VERSION ""

NS_ :

BS_:

BU_: BCM_PB ECM_PB TCM_PB Router_PB APA_PB SBSA_PB EBCM_PB IPC_PB SDM_PB EPS_PB AHL_AFL_PB ECC_PB ESCL_PB Firewall_PB CGM_PB PFAF_PB IBOOST_PB

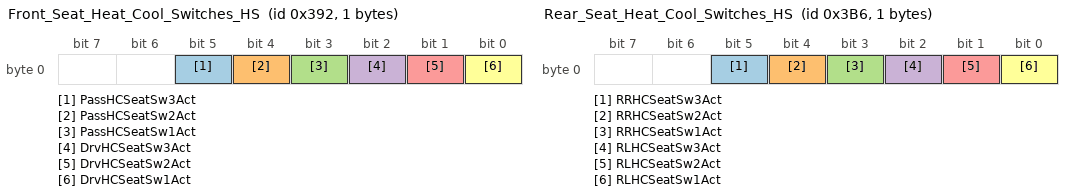
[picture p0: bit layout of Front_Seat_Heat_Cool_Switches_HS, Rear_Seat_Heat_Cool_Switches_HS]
BO_ 914 Front_Seat_Heat_Cool_Switches_HS: 1 ECC_PB
 SG_ PassHCSeatSw3Act : 5|1@0+ (1,0) [0|1] ""  BCM_PB
 SG_ PassHCSeatSw2Act : 4|1@0+ (1,0) [0|1] ""  BCM_PB
 SG_ PassHCSeatSw1Act : 3|1@0+ (1,0) [0|1] ""  BCM_PB
 SG_ DrvHCSeatSw3Act : 2|1@0+ (1,0) [0|1] ""  BCM_PB
 SG_ DrvHCSeatSw2Act : 1|1@0+ (1,0) [0|1] ""  BCM_PB
 SG_ DrvHCSeatSw1Act : 0|1@0+ (1,0) [0|1] ""  BCM_PB

BO_ 950 Rear_Seat_Heat_Cool_Switches_HS: 1 ECC_PB
 SG_ RRHCSeatSw3Act : 5|1@0+ (1,0) [0|1] ""  BCM_PB
 SG_ RRHCSeatSw2Act : 4|1@0+ (1,0) [0|1] ""  BCM_PB
 SG_ RRHCSeatSw1Act : 3|1@0+ (1,0) [0|1] ""  BCM_PB
 SG_ RLHCSeatSw3Act : 2|1@0+ (1,0) [0|1] ""  BCM_PB
 SG_ RLHCSeatSw2Act : 1|1@0+ (1,0) [0|1] ""  BCM_PB
 SG_ RLHCSeatSw1Act : 0|1@0+ (1,0) [0|1] ""  BCM_PB

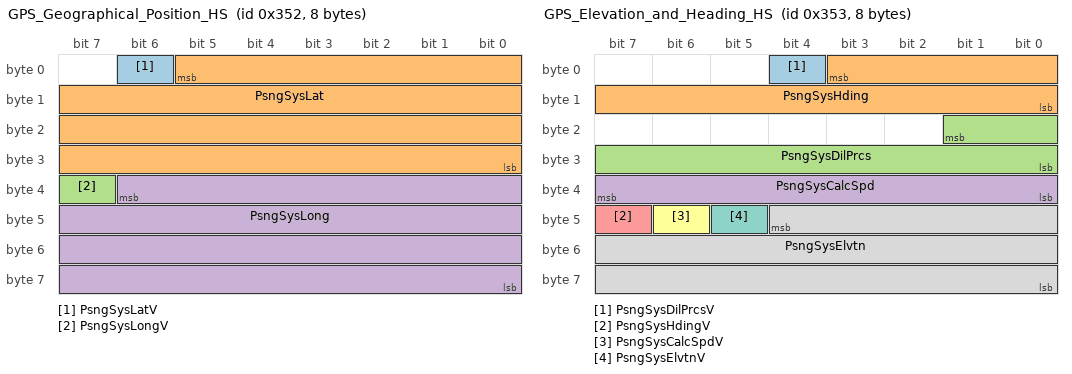
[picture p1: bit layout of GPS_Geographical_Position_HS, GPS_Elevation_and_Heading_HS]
BO_ 850 GPS_Geographical_Position_HS: 8 Firewall_PB
 SG_ PsngSysLatV : 6|1@0+ (1,0) [0|1] ""  ECC_PB
 SG_ PsngSysLat : 5|30@0- (1,0) [-536870912|536870911] "msarc"  ECC_PB
 SG_ PsngSysLongV : 39|1@0+ (1,0) [0|1] ""  ECC_PB
 SG_ PsngSysLong : 38|31@0- (1,0) [-1073741824|1073741823] "msarc"  ECC_PB

BO_ 851 GPS_Elevation_and_Heading_HS: 8 Firewall_PB
 SG_ PsngSysDilPrcsV : 4|1@0+ (1,0) [0|1] "" Vector__XXX
 SG_ PsngSysHding : 3|12@0+ (0.1,0) [0|409.5] "deg"  ECC_PB
 SG_ PsngSysDilPrcs : 17|10@0+ (0.1,0) [0|102.3] "" Vector__XXX
 SG_ PsngSysCalcSpd : 39|8@0+ (1,0) [0|255] "km/h" Vector__XXX
 SG_ PsngSysHdingV : 47|1@0+ (1,0) [0|1] ""  ECC_PB
 SG_ PsngSysCalcSpdV : 46|1@0+ (1,0) [0|1] "" Vector__XXX
 SG_ PsngSysElvtnV : 45|1@0+ (1,0) [0|1] ""  ECC_PB
 SG_ PsngSysElvtn : 44|21@0+ (1,-100000) [-100000|1997151] "cm"  ECC_PB

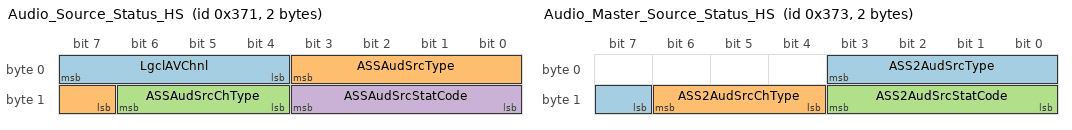
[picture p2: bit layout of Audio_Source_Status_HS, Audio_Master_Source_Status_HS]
BO_ 881 Audio_Source_Status_HS: 2 Firewall_PB
 SG_ LgclAVChnl : 7|4@0+ (1,0) [0|15] "" Vector__XXX
 SG_ ASSAudSrcType : 3|5@0+ (1,0) [0|31] ""  ECC_PB
 SG_ ASSAudSrcChType : 14|3@0+ (1,0) [0|7] ""  ECC_PB
 SG_ ASSAudSrcStatCode : 11|4@0+ (1,0) [0|15] ""  ECC_PB

BO_ 883 Audio_Master_Source_Status_HS: 2 Firewall_PB
 SG_ ASS2AudSrcType : 3|5@0+ (1,0) [0|31] ""  ECC_PB
 SG_ ASS2AudSrcChType : 14|3@0+ (1,0) [0|7] ""  ECC_PB
 SG_ ASS2AudSrcStatCode : 11|4@0+ (1,0) [0|15] ""  ECC_PB

BO_ 948 Rear_Seat_Heat_Cool_Control_HS: 4 BCM_PB
 SG_ RLHCSMIndReq : 4|2@0+ (1,0) [0|3] ""  ECC_PB
 SG_ RLHCSMInd1 : 2|1@0+ (1,0) [0|1] ""  ECC_PB
 SG_ RLHCSMInd2 : 1|1@0+ (1,0) [0|1] ""  ECC_PB
 SG_ RLHCSMInd3 : 0|1@0+ (1,0) [0|1] ""  ECC_PB
 SG_ RRHCSMIndReq : 12|2@0+ (1,0) [0|3] ""  ECC_PB
 SG_ RRHCSMInd1 : 10|1@0+ (1,0) [0|1] ""  ECC_PB
 SG_ RRHCSMInd2 : 9|1@0+ (1,0) [0|1] ""  ECC_PB
 SG_ RRHCSMInd3 : 8|1@0+ (1,0) [0|1] ""  ECC_PB
 SG_ RLHCSLIndReq : 22|2@0+ (1,0) [0|3] ""  ECC_PB
 SG_ RLHCSLSeatLev1 : 20|1@0+ (1,0) [0|1] ""  ECC_PB
 SG_ RLHCSLSeatLev2 : 19|1@0+ (1,0) [0|1] ""  ECC_PB
 SG_ RLHCSLSeatLev3 : 18|1@0+ (1,0) [0|1] ""  ECC_PB
 SG_ RLHCSLSeatLev4 : 17|1@0+ (1,0) [0|1] ""  ECC_PB
 SG_ RLHCSLSeatLev5 : 16|1@0+ (1,0) [0|1] ""  ECC_PB
 SG_ RRHCSLIndReq : 30|2@0+ (1,0) [0|3] ""  ECC_PB
 SG_ RRHCSLSeatLev1 : 28|1@0+ (1,0) [0|1] ""  ECC_PB
 SG_ RRHCSLSeatLev2 : 27|1@0+ (1,0) [0|1] ""  ECC_PB
 SG_ RRHCSLSeatLev3 : 26|1@0+ (1,0) [0|1] ""  ECC_PB
 SG_ RRHCSLSeatLev4 : 25|1@0+ (1,0) [0|1] ""  ECC_PB
 SG_ RRHCSLSeatLev5 : 24|1@0+ (1,0) [0|1] ""  ECC_PB

BO_ 1061 Display_Measurement_System_HS: 1 IPC_PB
 SG_ DispMeasSys : 2|1@0+ (1,0) [0|1] "" Vector__XXX
 SG_ DispMeasSysExt : 1|2@0+ (1,0) [0|3] ""  ECC_PB

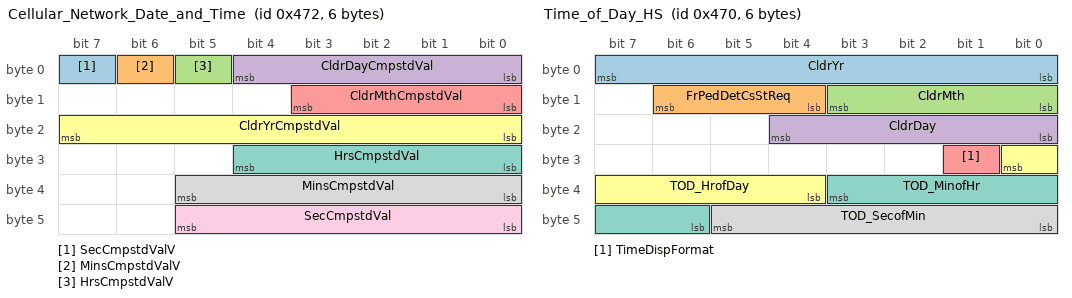
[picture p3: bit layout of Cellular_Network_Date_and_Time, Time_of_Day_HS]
BO_ 1138 Cellular_Network_Date_and_Time: 6 Firewall_PB
 SG_ SecCmpstdValV : 7|1@0+ (1,0) [0|1] "" Vector__XXX
 SG_ MinsCmpstdValV : 6|1@0+ (1,0) [0|1] "" Vector__XXX
 SG_ HrsCmpstdValV : 5|1@0+ (1,0) [0|1] "" Vector__XXX
 SG_ CldrDayCmpstdVal : 4|5@0+ (1,0) [0|31] "days"  ECC_PB
 SG_ CldrMthCmpstdVal : 11|4@0+ (1,0) [0|15] ""  ECC_PB
 SG_ CldrYrCmpstdVal : 23|8@0+ (1,2000) [2000|2255] "year" Vector__XXX
 SG_ HrsCmpstdVal : 28|5@0+ (1,0) [0|31] "h" Vector__XXX
 SG_ MinsCmpstdVal : 37|6@0+ (1,0) [0|63] "min" Vector__XXX
 SG_ SecCmpstdVal : 45|6@0+ (1,0) [0|63] "secs" Vector__XXX

BO_ 1136 Time_of_Day_HS: 6 Firewall_PB
 SG_ CldrYr : 7|8@0+ (1,2000) [2000|2255] "year" Vector__XXX
 SG_ FrPedDetCsStReq : 14|3@0+ (1,0) [0|7] "" Vector__XXX
 SG_ CldrMth : 11|4@0+ (1,0) [0|15] ""  ECC_PB
 SG_ CldrDay : 20|5@0+ (1,0) [0|31] "days"  ECC_PB
 SG_ TimeDispFormat : 25|1@0+ (1,0) [0|1] "" Vector__XXX
 SG_ TOD_HrofDay : 24|5@0+ (1,0) [0|31] "hr"  ECC_PB
 SG_ TOD_MinofHr : 35|6@0+ (1,0) [0|63] "min"  ECC_PB
 SG_ TOD_SecofMin : 45|6@0+ (1,0) [0|63] "s"  ECC_PB

BO_ 2430336753 Func_USDT_Req_to_All_F_TestTool: 8 Firewall_PB
 SG_ DgnInf : 7|64@0+ (1,0) [0|1.84467440737096E+019] ""  ECC_PB

BO_ 2430336755 Func_USDT_Req_to_All_F_ONSTAR: 8 Firewall_PB
 SG_ DgnInf : 7|64@0+ (1,0) [0|1.84467440737096E+019] ""  ECC_PB

BO_ 2497376665 Phy_USDT_Resp_F_ECC_To_TestTool: 8 ECC_PB
 SG_ DgnInf : 7|64@0+ (1,0) [0|1.84467440737096E+019] ""  Firewall_PB

BO_ 2497507737 Phy_UUDT_Resp_F_ECC_To_TestTool: 8 ECC_PB
 SG_ DgnInf : 7|64@0+ (1,0) [0|1.84467440737096E+019] ""  Firewall_PB

BO_ 2497377177 Phy_USDT_Resp_F_ECC_To_ONSTAR: 8 ECC_PB
 SG_ DgnInf : 7|64@0+ (1,0) [0|1.84467440737096E+019] ""  Firewall_PB

BO_ 2497508249 Phy_UUDT_Resp_F_ECC_To_ONSTAR: 8 ECC_PB
 SG_ DgnInf : 7|64@0+ (1,0) [0|1.84467440737096E+019] ""  Firewall_PB

BO_ 2497354225 Phy_USDT_Req_to_ECC_F_TestTool: 8 Firewall_PB
 SG_ DgnInf : 7|64@0+ (1,0) [0|1.84467440737096E+019] ""  ECC_PB

BO_ 2497354227 Phy_USDT_Req_to_ECC_F_ONSTAR: 8 Firewall_PB
 SG_ DgnInf : 7|64@0+ (1,0) [0|1.84467440737096E+019] ""  ECC_PB

BO_ 1088 Re_Initialization_Request_BCM: 1 BCM_PB
 SG_ ReIniReq_BCM : 7|1@0+ (1,0) [0|1] ""  ECC_PB

BO_ 1089 Re_Initialization_Request_IPC: 1 IPC_PB
 SG_ ReIniReq_IPC : 7|1@0+ (1,0) [0|1] ""  ECC_PB

BO_ 1122 Re_Initialization_Request_APA: 1 APA_PB
 SG_ ReIniReq_APA : 7|1@0+ (1,0) [0|1] ""  ECC_PB

BO_ 1091 Re_Initialization_Request_ECC: 1 ECC_PB
 SG_ ReIniReq_ECC : 7|1@0+ (1,0) [0|1] ""  IPC_PB,APA_PB,SBSA_PB,BCM_PB,ESCL_PB,Firewall_PB,SDM_PB

BO_ 1093 Re_Initialization_Request_ESCL: 1 ESCL_PB
 SG_ ReIniReq_ESCL : 7|1@0+ (1,0) [0|1] ""  ECC_PB

BO_ 1094 Re_Initialization_Request_FCM: 1 Firewall_PB
 SG_ ReIniReq_FCM : 7|1@0+ (1,0) [0|1] ""  ECC_PB

BO_ 1095 Re_Initialization_Request_ONSTAR: 1 Firewall_PB
 SG_ ReIniReq_ONSTAR : 7|1@0+ (1,0) [0|1] ""  ECC_PB

BO_ 1096 Re_Initialization_Request_RadioH: 1 Firewall_PB
 SG_ ReIniReq_RadioHead : 7|1@0+ (1,0) [0|1] ""  ECC_PB

BO_ 1097 Re_Initialization_Request_SDM: 1 SDM_PB
 SG_ ReIniReq_SDM : 7|1@0+ (1,0) [0|1] ""  ECC_PB

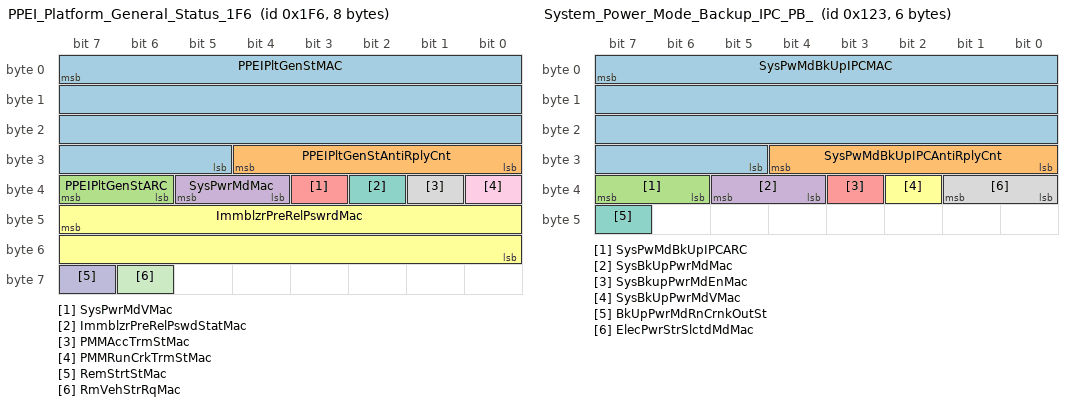
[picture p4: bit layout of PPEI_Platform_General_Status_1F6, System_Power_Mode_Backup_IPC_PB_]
BO_ 502 PPEI_Platform_General_Status_1F6: 8 BCM_PB
 SG_ PPEIPltGenStMAC : 7|27@0+ (1,0) [0|134217727] "" Vector__XXX
 SG_ PPEIPltGenStAntiRplyCnt : 28|5@0+ (1,0) [0|31] "" Vector__XXX
 SG_ PPEIPltGenStARC : 39|2@0+ (1,0) [0|3] "" Vector__XXX
 SG_ SysPwrMdMac : 37|2@0+ (1,0) [0|3] ""  ECC_PB
 SG_ SysPwrMdVMac : 35|1@0+ (1,0) [0|1] ""  ECC_PB
 SG_ ImmblzrPreRelPswrdMac : 47|16@0+ (1,0) [0|65535] "passwrd" Vector__XXX
 SG_ ImmblzrPreRelPswdStatMac : 34|1@0+ (1,0) [0|1] "" Vector__XXX
 SG_ PMMAccTrmStMac : 33|1@0+ (1,0) [0|1] "" Vector__XXX
 SG_ PMMRunCrkTrmStMac : 32|1@0+ (1,0) [0|1] "" Vector__XXX
 SG_ RemStrtStMac : 63|1@0+ (1,0) [0|1] ""  ECC_PB
 SG_ RmVehStrRqMac : 62|1@0+ (1,0) [0|1] "" Vector__XXX

BO_ 291 System_Power_Mode_Backup_IPC_PB_: 6 IPC_PB
 SG_ SysPwMdBkUpIPCMAC : 7|27@0+ (1,0) [0|134217727] "" Vector__XXX
 SG_ SysPwMdBkUpIPCAntiRplyCnt : 28|5@0+ (1,0) [0|31] "" Vector__XXX
 SG_ SysPwMdBkUpIPCARC : 39|2@0+ (1,0) [0|3] "" Vector__XXX
 SG_ SysBkUpPwrMdMac : 37|2@0+ (1,0) [0|3] ""  ECC_PB
 SG_ SysBkupPwrMdEnMac : 35|1@0+ (1,0) [0|1] ""  ECC_PB
 SG_ SysBkUpPwrMdVMac : 34|1@0+ (1,0) [0|1] ""  ECC_PB
 SG_ BkUpPwrMdRnCrnkOutSt : 47|1@0+ (1,0) [0|1] "" Vector__XXX
 SG_ ElecPwrStrSlctdMdMac : 33|2@0+ (1,0) [0|3] "" Vector__XXX

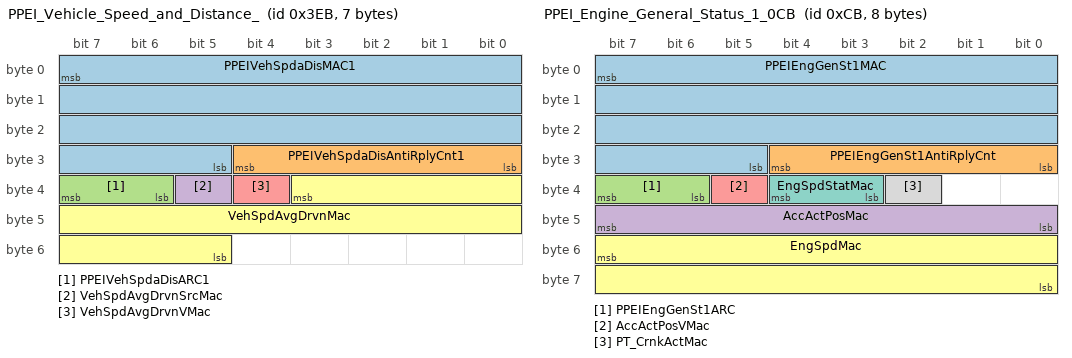
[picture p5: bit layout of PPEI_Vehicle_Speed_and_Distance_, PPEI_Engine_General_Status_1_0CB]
BO_ 1003 PPEI_Vehicle_Speed_and_Distance_: 7 ECM_PB
 SG_ PPEIVehSpdaDisMAC1 : 7|27@0+ (1,0) [0|134217727] "" Vector__XXX
 SG_ PPEIVehSpdaDisAntiRplyCnt1 : 28|5@0+ (1,0) [0|31] "" Vector__XXX
 SG_ PPEIVehSpdaDisARC1 : 39|2@0+ (1,0) [0|3] "" Vector__XXX
 SG_ VehSpdAvgDrvnSrcMac : 37|1@0+ (1,0) [0|1] "" Vector__XXX
 SG_ VehSpdAvgDrvnVMac : 36|1@0+ (1,0) [0|1] ""  ECC_PB
 SG_ VehSpdAvgDrvnMac : 35|15@0+ (0.015625,0) [0|511.984375] "km/h"  ECC_PB

BO_ 203 PPEI_Engine_General_Status_1_0CB: 8 ECM_PB
 SG_ PPEIEngGenSt1MAC : 7|27@0+ (1,0) [0|134217727] "" Vector__XXX
 SG_ PPEIEngGenSt1AntiRplyCnt : 28|5@0+ (1,0) [0|31] "" Vector__XXX
 SG_ PPEIEngGenSt1ARC : 39|2@0+ (1,0) [0|3] "" Vector__XXX
 SG_ AccActPosMac : 47|8@0+ (0.392157,0) [0|100.000035] "%" Vector__XXX
 SG_ AccActPosVMac : 37|1@0+ (1,0) [0|1] "" Vector__XXX
 SG_ EngSpdMac : 55|16@0+ (0.25,0) [0|16383.75] "rpm"  ECC_PB
 SG_ EngSpdStatMac : 36|2@0+ (1,0) [0|3] ""  ECC_PB
 SG_ PT_CrnkActMac : 34|1@0+ (1,0) [0|1] "" Vector__XXX

BO_ 1630 Climate_Control_Customization_In: 6 ECC_PB
 SG_ AirQltySnsCstCrStVal : 7|3@0+ (1,0) [0|7] ""  Firewall_PB
 SG_ AirQltySnsCstStAvl : 4|1@0+ (1,0) [0|1] ""  Firewall_PB
 SG_ AirQltySnsCstAvlFlg1 : 3|1@0+ (1,0) [0|1] ""  Firewall_PB
 SG_ AirQltySnsCstAvlFlg2 : 2|1@0+ (1,0) [0|1] ""  Firewall_PB
 SG_ AirQltySnsCstAvlFlg3 : 1|1@0+ (1,0) [0|1] ""  Firewall_PB
 SG_ AirQltySnsCstAvlFlg4 : 0|1@0+ (1,0) [0|1] ""  Firewall_PB
 SG_ AirQltySnsCstAvlFlg5 : 15|1@0+ (1,0) [0|1] ""  Firewall_PB
 SG_ AirQltySnsCstAvlFlg6 : 14|1@0+ (1,0) [0|1] ""  Firewall_PB
 SG_ AirQltySnsCstAvlFlg7 : 13|1@0+ (1,0) [0|1] ""  Firewall_PB
 SG_ IonzrCtrlCstCrStVal : 12|3@0+ (1,0) [0|7] ""  Firewall_PB
 SG_ IonzrCtrlCstStAvl : 9|1@0+ (1,0) [0|1] ""  Firewall_PB
 SG_ IonzrCtrlCstAvlFlg1 : 8|1@0+ (1,0) [0|1] ""  Firewall_PB
 SG_ IonzrCtrlCstAvlFlg2 : 23|1@0+ (1,0) [0|1] ""  Firewall_PB
 SG_ IonzrCtrlCstAvlFlg3 : 22|1@0+ (1,0) [0|1] ""  Firewall_PB
 SG_ IonzrCtrlCstAvlFlg4 : 21|1@0+ (1,0) [0|1] ""  Firewall_PB
 SG_ IonzrCtrlCstAvlFlg5 : 20|1@0+ (1,0) [0|1] ""  Firewall_PB
 SG_ IonzrCtrlCstAvlFlg6 : 19|1@0+ (1,0) [0|1] ""  Firewall_PB
 SG_ IonzrCtrlCstAvlFlg7 : 18|1@0+ (1,0) [0|1] ""  Firewall_PB
 SG_ AutoDfgCstCrStVal : 17|3@0+ (1,0) [0|7] ""  Firewall_PB
 SG_ AutoDfgCstStAvl : 30|1@0+ (1,0) [0|1] ""  Firewall_PB
 SG_ AutoDfgCstAvlFlg1 : 29|1@0+ (1,0) [0|1] ""  Firewall_PB
 SG_ AutoDfgCstAvlFlg2 : 28|1@0+ (1,0) [0|1] ""  Firewall_PB
 SG_ AutoDfgCstAvlFlg3 : 27|1@0+ (1,0) [0|1] ""  Firewall_PB
 SG_ AutoDfgCstAvlFlg4 : 26|1@0+ (1,0) [0|1] ""  Firewall_PB
 SG_ AutoDfgCstAvlFlg5 : 25|1@0+ (1,0) [0|1] ""  Firewall_PB
 SG_ AutoDfgCstAvlFlg6 : 24|1@0+ (1,0) [0|1] ""  Firewall_PB
 SG_ AutoDfgCstAvlFlg7 : 39|1@0+ (1,0) [0|1] ""  Firewall_PB
 SG_ AutoFanCstCrStVal : 38|3@0+ (1,0) [0|7] ""  Firewall_PB
 SG_ AutoFanCstStAvl : 35|1@0+ (1,0) [0|1] ""  Firewall_PB
 SG_ AutoFanCstAvlFlg1 : 34|1@0+ (1,0) [0|1] ""  Firewall_PB
 SG_ AutoFanCstAvlFlg2 : 33|1@0+ (1,0) [0|1] ""  Firewall_PB
 SG_ AutoFanCstAvlFlg3 : 32|1@0+ (1,0) [0|1] ""  Firewall_PB
 SG_ AutoFanCstAvlFlg4 : 47|1@0+ (1,0) [0|1] ""  Firewall_PB
 SG_ AutoFanCstAvlFlg5 : 46|1@0+ (1,0) [0|1] ""  Firewall_PB
 SG_ AutoFanCstAvlFlg6 : 45|1@0+ (1,0) [0|1] ""  Firewall_PB
 SG_ AutoFanCstAvlFlg7 : 44|1@0+ (1,0) [0|1] ""  Firewall_PB

BO_ 1638 Climate_Control_Customizati_0000: 7 ECC_PB
 SG_ RrDfgStUpCstCrStVal : 7|3@0+ (1,0) [0|7] ""  Firewall_PB
 SG_ RrDfgStUpCstStAvl : 4|1@0+ (1,0) [0|1] ""  Firewall_PB
 SG_ RrDfgStUpCstAvlFlg1 : 3|1@0+ (1,0) [0|1] ""  Firewall_PB
 SG_ RrDfgStUpCstAvlFlg2 : 2|1@0+ (1,0) [0|1] ""  Firewall_PB
 SG_ RrDfgStUpCstAvlFlg3 : 1|1@0+ (1,0) [0|1] ""  Firewall_PB
 SG_ RrDfgStUpCstAvlFlg4 : 0|1@0+ (1,0) [0|1] ""  Firewall_PB
 SG_ RrDfgStUpCstAvlFlg5 : 15|1@0+ (1,0) [0|1] ""  Firewall_PB
 SG_ RrDfgStUpCstAvlFlg6 : 14|1@0+ (1,0) [0|1] ""  Firewall_PB
 SG_ RrDfgStUpCstAvlFlg7 : 13|1@0+ (1,0) [0|1] ""  Firewall_PB
 SG_ RrZnStUpCstCrStVal : 12|3@0+ (1,0) [0|7] ""  Firewall_PB
 SG_ RrZnStUpCstStAvl : 9|1@0+ (1,0) [0|1] ""  Firewall_PB
 SG_ RrZnStUpCstAvlFlg1 : 8|1@0+ (1,0) [0|1] ""  Firewall_PB
 SG_ RrZnStUpCstAvlFlg2 : 23|1@0+ (1,0) [0|1] ""  Firewall_PB
 SG_ RrZnStUpCstAvlFlg3 : 22|1@0+ (1,0) [0|1] ""  Firewall_PB
 SG_ RrZnStUpCstAvlFlg4 : 21|1@0+ (1,0) [0|1] ""  Firewall_PB
 SG_ RrZnStUpCstAvlFlg5 : 20|1@0+ (1,0) [0|1] ""  Firewall_PB
 SG_ RrZnStUpCstAvlFlg6 : 19|1@0+ (1,0) [0|1] ""  Firewall_PB
 SG_ RrZnStUpCstAvlFlg7 : 18|1@0+ (1,0) [0|1] ""  Firewall_PB
 SG_ AutoCoolStCstCrStVal : 17|3@0+ (1,0) [0|7] ""  Firewall_PB
 SG_ AutoCoolStCstStAvl : 30|1@0+ (1,0) [0|1] ""  Firewall_PB
 SG_ AutoCoolStCstAvlFlg1 : 29|1@0+ (1,0) [0|1] ""  Firewall_PB
 SG_ AutoCoolStCstAvlFlg2 : 28|1@0+ (1,0) [0|1] ""  Firewall_PB
 SG_ AutoCoolStCstAvlFlg3 : 27|1@0+ (1,0) [0|1] ""  Firewall_PB
 SG_ AutoCoolStCstAvlFlg4 : 26|1@0+ (1,0) [0|1] ""  Firewall_PB
 SG_ AutoCoolStCstAvlFlg5 : 25|1@0+ (1,0) [0|1] ""  Firewall_PB
 SG_ AutoCoolStCstAvlFlg6 : 24|1@0+ (1,0) [0|1] ""  Firewall_PB
 SG_ AutoCoolStCstAvlFlg7 : 39|1@0+ (1,0) [0|1] ""  Firewall_PB
 SG_ AutoHtdStCstCrStVal : 38|3@0+ (1,0) [0|7] ""  Firewall_PB
 SG_ AutoHtdStCstStAvl : 35|1@0+ (1,0) [0|1] ""  Firewall_PB
 SG_ AutoHtdStCstAvlFlg1 : 34|1@0+ (1,0) [0|1] ""  Firewall_PB
 SG_ AutoHtdStCstAvlFlg2 : 33|1@0+ (1,0) [0|1] ""  Firewall_PB
 SG_ AutoHtdStCstAvlFlg3 : 32|1@0+ (1,0) [0|1] ""  Firewall_PB
 SG_ AutoHtdStCstAvlFlg4 : 47|1@0+ (1,0) [0|1] ""  Firewall_PB
 SG_ AutoHtdStCstAvlFlg5 : 46|1@0+ (1,0) [0|1] ""  Firewall_PB
 SG_ AutoHtdStCstAvlFlg6 : 45|1@0+ (1,0) [0|1] ""  Firewall_PB
 SG_ AutoHtdStCstAvlFlg7 : 44|1@0+ (1,0) [0|1] ""  Firewall_PB
 SG_ HVACRmtStrtStCstCurSetVal : 43|3@0+ (1,0) [0|7] ""  Firewall_PB
 SG_ HVACRmtStrtStCstStAvl : 40|1@0+ (1,0) [0|1] ""  Firewall_PB
 SG_ HVACRmtStrtStCstAvlFlg1 : 55|1@0+ (1,0) [0|1] ""  Firewall_PB
 SG_ HVACRmtStrtStCstAvlFlg2 : 54|1@0+ (1,0) [0|1] ""  Firewall_PB
 SG_ HVACRmtStrtStCstAvlFlg3 : 53|1@0+ (1,0) [0|1] ""  Firewall_PB
 SG_ HVACRmtStrtStCstAvlFlg4 : 52|1@0+ (1,0) [0|1] ""  Firewall_PB
 SG_ HVACRmtStrtStCstAvlFlg5 : 51|1@0+ (1,0) [0|1] ""  Firewall_PB
 SG_ HVACRmtStrtStCstAvlFlg6 : 50|1@0+ (1,0) [0|1] ""  Firewall_PB
 SG_ HVACRmtStrtStCstAvlFlg7 : 49|1@0+ (1,0) [0|1] ""  Firewall_PB

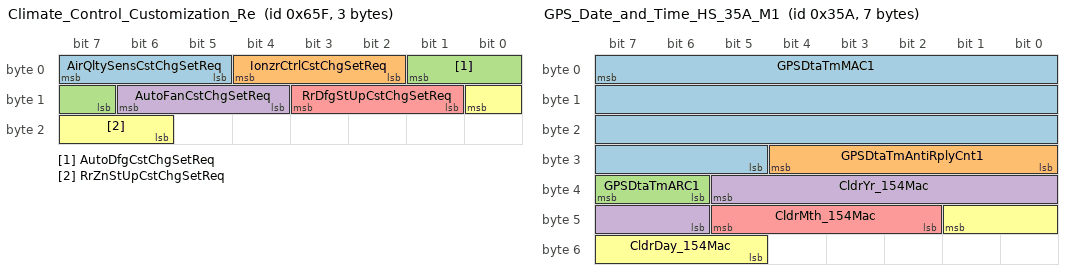
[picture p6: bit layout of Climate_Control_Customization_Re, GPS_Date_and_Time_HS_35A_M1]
BO_ 1631 Climate_Control_Customization_Re: 3 Firewall_PB
 SG_ AirQltySensCstChgSetReq : 7|3@0+ (1,0) [0|7] ""  ECC_PB
 SG_ IonzrCtrlCstChgSetReq : 4|3@0+ (1,0) [0|7] ""  ECC_PB
 SG_ AutoDfgCstChgSetReq : 1|3@0+ (1,0) [0|7] ""  ECC_PB
 SG_ AutoFanCstChgSetReq : 14|3@0+ (1,0) [0|7] ""  ECC_PB
 SG_ RrDfgStUpCstChgSetReq : 11|3@0+ (1,0) [0|7] ""  ECC_PB
 SG_ RrZnStUpCstChgSetReq : 8|3@0+ (1,0) [0|7] ""  ECC_PB

BO_ 1639 Climate_Control_Customizati_0001: 2 Firewall_PB
 SG_ AutoHtdStCstChgSetReq : 7|3@0+ (1,0) [0|7] ""  ECC_PB
 SG_ HVACRmtStrtStCstChgSetReq : 1|3@0+ (1,0) [0|7] ""  ECC_PB

BO_ 1704 Restore_Customization_Defaults_R: 1 Firewall_PB
 SG_ RstrCstDfltReq : 7|1@0+ (1,0) [0|1] ""  ECC_PB

BO_ 1713 Indication_Temperature_Setting: 7 ECC_PB
 SG_ IndAirDstFL : 7|4@0+ (1,0) [0|15] ""  Firewall_PB
 SG_ IndAirDstFR : 3|4@0+ (1,0) [0|15] ""  Firewall_PB
 SG_ IndFrtHVAC_On : 15|1@0+ (1,0) [0|1] ""  Firewall_PB
 SG_ IndBlwStngLvlFrt : 14|4@0+ (1,0) [0|15] ""  Firewall_PB
 SG_ IndBlwStngStFrt : 10|2@0+ (1,0) [0|3] ""  Firewall_PB
 SG_ IndTmpStngLvlFL : 8|7@0+ (1,0) [0|127] ""  Firewall_PB
 SG_ IndTmpStngStFL : 17|3@0+ (1,0) [0|7] ""  Firewall_PB
 SG_ IndTmpStngLvlFR : 30|7@0+ (1,0) [0|127] ""  Firewall_PB
 SG_ IndTmpStngStFR : 39|3@0+ (1,0) [0|7] ""  Firewall_PB
 SG_ IndTmpUnts : 36|1@0+ (1,0) [0|1] ""  Firewall_PB
 SG_ IndRecircStng : 35|2@0+ (1,0) [0|3] ""  Firewall_PB
 SG_ IndFogPrtcTkngFrshAirActMsg : 33|1@0+ (1,0) [0|1] ""  Firewall_PB
 SG_ IndAirQltSysTkngRecircActMsg : 32|1@0+ (1,0) [0|1] ""  Firewall_PB
 SG_ IndLowSpdPlltnTkngRecircActMsg : 47|1@0+ (1,0) [0|1] ""  Firewall_PB
 SG_ IndRrWndDfgStng : 46|1@0+ (1,0) [0|1] ""  Firewall_PB
 SG_ AirCndActIO : 45|1@0+ (1,0) [0|1] ""  Firewall_PB,IPC_PB
 SG_ IndCompStng : 44|2@0+ (1,0) [0|3] ""  Firewall_PB
 SG_ IndClmMdStng : 42|2@0+ (1,0) [0|3] ""  Firewall_PB
 SG_ IndInzrStat : 40|3@0+ (1,0) [0|7] ""  Firewall_PB
 SG_ IndAC_OnBatCoolMsg : 53|1@0+ (1,0) [0|1] ""  Firewall_PB
 SG_ IndSYNC_All : 52|1@0+ (1,0) [0|1] ""  Firewall_PB
 SG_ HVAC_StngsCtrlAvlbl : 50|1@0+ (1,0) [0|1] ""  Firewall_PB

BO_ 1716 Request_Air_Distribution_Info: 8 Firewall_PB
 SG_ ReqAirDstFLInfo : 7|4@0+ (1,0) [0|15] ""  ECC_PB
 SG_ ReqAirDstFRInfo : 3|4@0+ (1,0) [0|15] ""  ECC_PB
 SG_ ReqFrtHVAC_PwrChgInfo : 15|1@0+ (1,0) [0|1] ""  ECC_PB
 SG_ ReqFrtAutoInfo : 14|1@0+ (1,0) [0|1] ""  ECC_PB
 SG_ ReqBlwLvlChgFrtInfo : 13|5@0+ (1,-16) [0|31] ""  ECC_PB
 SG_ ReqBlwLvlFrtInfo : 8|4@0+ (1,0) [0|15] ""  ECC_PB
 SG_ ReqBlwLvlFrtAtvInfo : 20|1@0+ (1,0) [0|1] ""  ECC_PB
 SG_ ReqBlwSpdRdctnInfo : 19|1@0+ (1,0) [0|1] ""  ECC_PB
 SG_ ReqTmpChgFLInfo : 18|7@0+ (1,-64) [0|127] ""  ECC_PB
 SG_ ReqTmpChgFRInfo : 27|7@0+ (1,-64) [0|127] ""  ECC_PB
 SG_ ReqTmpLvlFLInfo : 36|7@0+ (1,0) [0|127] ""  ECC_PB
 SG_ ReqTmpLvlFLAtvInfo : 45|1@0+ (1,0) [0|1] ""  ECC_PB
 SG_ ReqTmpLvlFRInfo : 44|7@0+ (1,0) [0|127] ""  ECC_PB
 SG_ ReqTmpLvlFRAtvInfo : 53|1@0+ (1,0) [0|1] ""  ECC_PB
 SG_ ReqRecircStngChgInfo : 52|1@0+ (1,0) [0|1] ""  ECC_PB
 SG_ ReqCompStngChgInfo : 51|1@0+ (1,0) [0|1] ""  ECC_PB
 SG_ ReqCompStngInfo : 50|2@0+ (1,0) [0|3] ""  ECC_PB
 SG_ ReqClmtMdStngChgInfo : 48|1@0+ (1,0) [0|1] ""  ECC_PB
 SG_ ReqClmtMdStngInfo : 63|2@0+ (1,0) [0|3] ""  ECC_PB
 SG_ ReqSYNC_AllChgInfo : 61|1@0+ (1,0) [0|1] ""  ECC_PB

BO_ 1717 Request_Front_Climate_APP: 7 ECC_PB
 SG_ ReqFrtClmtApp : 51|1@0+ (1,0) [0|1] ""  Firewall_PB

BO_ 858 GPS_Date_and_Time_HS_35A_M1: 7 Firewall_PB
 SG_ GPSDtaTmMAC1 : 7|27@0+ (1,0) [0|134217727] "" Vector__XXX
 SG_ GPSDtaTmAntiRplyCnt1 : 28|5@0+ (1,0) [0|31] "" Vector__XXX
 SG_ GPSDtaTmARC1 : 39|2@0+ (1,0) [0|3] "" Vector__XXX
 SG_ CldrYr_154Mac : 37|8@0+ (1,2000) [2000|2255] "year" Vector__XXX
 SG_ CldrMth_154Mac : 45|4@0+ (1,0) [0|15] ""  ECC_PB
 SG_ CldrDay_154Mac : 41|5@0+ (1,0) [0|31] "days"  ECC_PB

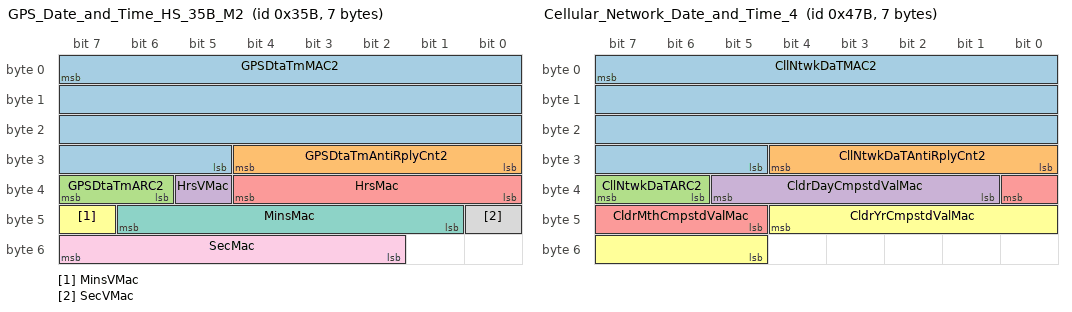
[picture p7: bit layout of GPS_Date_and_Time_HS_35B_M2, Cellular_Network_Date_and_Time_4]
BO_ 859 GPS_Date_and_Time_HS_35B_M2: 7 Firewall_PB
 SG_ GPSDtaTmMAC2 : 7|27@0+ (1,0) [0|134217727] "" Vector__XXX
 SG_ GPSDtaTmAntiRplyCnt2 : 28|5@0+ (1,0) [0|31] "" Vector__XXX
 SG_ GPSDtaTmARC2 : 39|2@0+ (1,0) [0|3] "" Vector__XXX
 SG_ HrsVMac : 37|1@0+ (1,0) [0|1] ""  ECC_PB
 SG_ HrsMac : 36|5@0+ (1,0) [0|31] "h"  ECC_PB
 SG_ MinsVMac : 47|1@0+ (1,0) [0|1] ""  ECC_PB
 SG_ MinsMac : 46|6@0+ (1,0) [0|63] "min"  ECC_PB
 SG_ SecVMac : 40|1@0+ (1,0) [0|1] "" Vector__XXX
 SG_ SecMac : 55|6@0+ (1,0) [0|63] "s" Vector__XXX

BO_ 1147 Cellular_Network_Date_and_Time_4: 7 Firewall_PB
 SG_ CllNtwkDaTMAC2 : 7|27@0+ (1,0) [0|134217727] "" Vector__XXX
 SG_ CllNtwkDaTAntiRplyCnt2 : 28|5@0+ (1,0) [0|31] "" Vector__XXX
 SG_ CllNtwkDaTARC2 : 39|2@0+ (1,0) [0|3] "" Vector__XXX
 SG_ CldrDayCmpstdValMac : 37|5@0+ (1,0) [0|31] "days"  ECC_PB
 SG_ CldrMthCmpstdValMac : 32|4@0+ (1,0) [0|15] ""  ECC_PB
 SG_ CldrYrCmpstdValMac : 44|8@0+ (1,2000) [2000|2255] "year" Vector__XXX

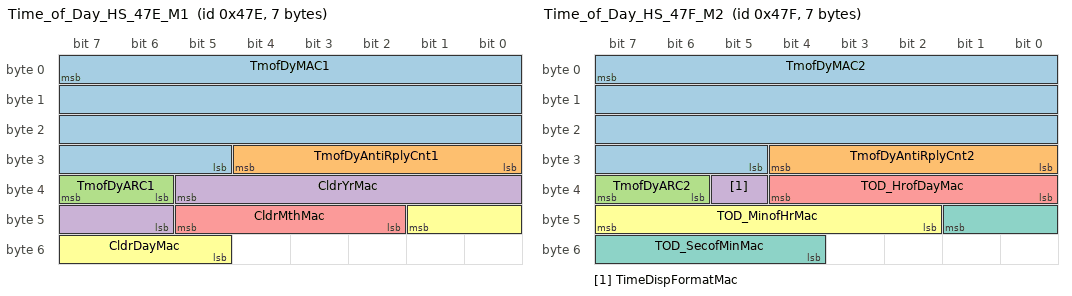
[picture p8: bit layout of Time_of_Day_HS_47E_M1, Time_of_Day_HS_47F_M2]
BO_ 1150 Time_of_Day_HS_47E_M1: 7 Firewall_PB
 SG_ TmofDyMAC1 : 7|27@0+ (1,0) [0|134217727] "" Vector__XXX
 SG_ TmofDyAntiRplyCnt1 : 28|5@0+ (1,0) [0|31] "" Vector__XXX
 SG_ TmofDyARC1 : 39|2@0+ (1,0) [0|3] "" Vector__XXX
 SG_ CldrYrMac : 37|8@0+ (1,2000) [2000|2255] "year" Vector__XXX
 SG_ CldrMthMac : 45|4@0+ (1,0) [0|15] ""  ECC_PB
 SG_ CldrDayMac : 41|5@0+ (1,0) [0|31] "days"  ECC_PB

BO_ 1151 Time_of_Day_HS_47F_M2: 7 Firewall_PB
 SG_ TmofDyMAC2 : 7|27@0+ (1,0) [0|134217727] "" Vector__XXX
 SG_ TmofDyAntiRplyCnt2 : 28|5@0+ (1,0) [0|31] "" Vector__XXX
 SG_ TmofDyARC2 : 39|2@0+ (1,0) [0|3] "" Vector__XXX
 SG_ TimeDispFormatMac : 37|1@0+ (1,0) [0|1] "" Vector__XXX
 SG_ TOD_HrofDayMac : 36|5@0+ (1,0) [0|31] "hr"  ECC_PB
 SG_ TOD_MinofHrMac : 47|6@0+ (1,0) [0|63] "min"  ECC_PB
 SG_ TOD_SecofMinMac : 41|6@0+ (1,0) [0|63] "s"  ECC_PB

BO_ 921 DTC_Triggered_399: 7 ECC_PB
 SG_ DTCIUnused6_399 : 7|1@0+ (1,0) [0|1] ""  Firewall_PB
 SG_ DTCIUnused5_399 : 6|1@0+ (1,0) [0|1] ""  Firewall_PB
 SG_ DTCIUnused4_399 : 5|1@0+ (1,0) [0|1] ""  Firewall_PB
 SG_ DTCIUnused3_399 : 4|1@0+ (1,0) [0|1] ""  Firewall_PB
 SG_ DTCIUnused2_399 : 3|1@0+ (1,0) [0|1] ""  Firewall_PB
 SG_ DTCIUnused1_399 : 2|1@0+ (1,0) [0|1] ""  Firewall_PB
 SG_ DTCI_WrnIndTrggrd_399 : 1|1@0+ (1,0) [0|1] ""  Firewall_PB
 SG_ DTCI_DTCTriggered_399 : 0|1@0+ (1,0) [0|1] ""  Firewall_PB
 SG_ DTCI_DTCSource_399 : 15|8@0+ (1,0) [0|255] ""  Firewall_PB
 SG_ DTCI_DTCNumber_399 : 23|16@0+ (1,0) [0|65535] ""  Firewall_PB
 SG_ DTCI_DTCFailType_399 : 39|8@0+ (1,0) [0|255] ""  Firewall_PB
 SG_ DTCI_WIR_399 : 47|1@0+ (1,0) [0|1] ""  Firewall_PB
 SG_ DTCI_TNCTOC_399 : 46|1@0+ (1,0) [0|1] ""  Firewall_PB
 SG_ DTCI_TFSLC_399 : 45|1@0+ (1,0) [0|1] ""  Firewall_PB
 SG_ DTCI_TNCSLC_399 : 44|1@0+ (1,0) [0|1] ""  Firewall_PB
 SG_ DTCI_CDTC_399 : 43|1@0+ (1,0) [0|1] ""  Firewall_PB
 SG_ DTCI_PDTC_399 : 42|1@0+ (1,0) [0|1] ""  Firewall_PB
 SG_ DTCI_TFTOC_399 : 41|1@0+ (1,0) [0|1] ""  Firewall_PB
 SG_ DTCI_TF_399 : 40|1@0+ (1,0) [0|1] ""  Firewall_PB
 SG_ DTCI_DTCFaultType_399 : 55|8@0+ (1,0) [0|255] ""  Firewall_PB

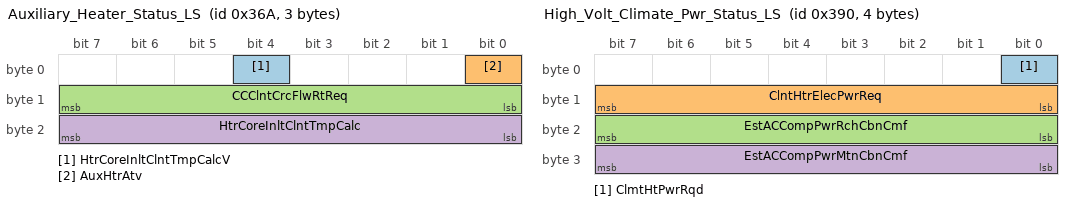
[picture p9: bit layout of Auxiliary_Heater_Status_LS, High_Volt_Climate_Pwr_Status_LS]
BO_ 874 Auxiliary_Heater_Status_LS: 3 ECC_PB
 SG_ HtrCoreInltClntTmpCalcV : 4|1@0+ (1,0) [0|1] ""  CGM_PB
 SG_ AuxHtrAtv : 0|1@0+ (1,0) [0|1] ""  CGM_PB
 SG_ CCClntCrcFlwRtReq : 15|8@0+ (0.392157,0) [0|100.000035] "%"  CGM_PB
 SG_ HtrCoreInltClntTmpCalc : 23|8@0+ (1,-40) [-40|215] "degC"  CGM_PB

BO_ 912 High_Volt_Climate_Pwr_Status_LS: 4 ECC_PB
 SG_ ClmtHtPwrRqd : 0|1@0+ (1,0) [0|1] ""  CGM_PB
 SG_ ClntHtrElecPwrReq : 15|8@0+ (0.04,0) [0|10.2] "kW" Vector__XXX
 SG_ EstACCompPwrRchCbnCmf : 23|8@0+ (0.04,0) [0|10.2] "kw"  CGM_PB
 SG_ EstACCompPwrMtnCbnCmf : 31|8@0+ (0.04,0) [0|10.2] "kW"  CGM_PB

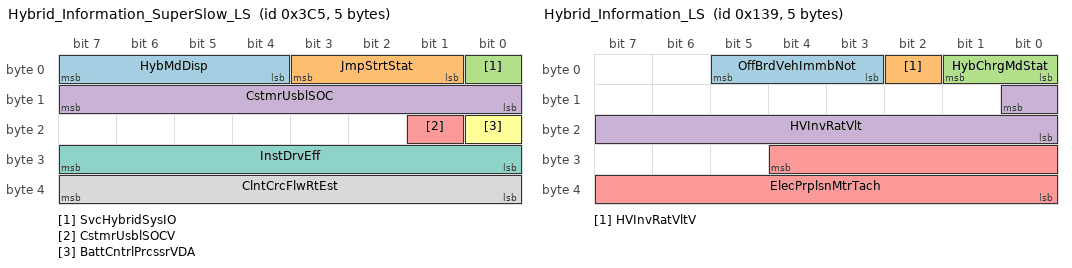
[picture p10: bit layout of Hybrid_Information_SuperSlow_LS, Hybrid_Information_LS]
BO_ 965 Hybrid_Information_SuperSlow_LS: 5 CGM_PB
 SG_ HybMdDisp : 7|4@0+ (1,0) [0|15] "" Vector__XXX
 SG_ JmpStrtStat : 3|3@0+ (1,0) [0|7] "" Vector__XXX
 SG_ SvcHybridSysIO : 0|1@0+ (1,0) [0|1] "" Vector__XXX
 SG_ CstmrUsblSOC : 15|8@0+ (0.39216,0) [0|100.0008] "%" Vector__XXX
 SG_ CstmrUsblSOCV : 17|1@0+ (1,0) [0|1] "" Vector__XXX
 SG_ BattCntrlPrcssrVDA : 16|1@0+ (1,0) [0|1] "" Vector__XXX
 SG_ InstDrvEff : 31|8@0- (0.78125,0) [-100|99.21875] "%" Vector__XXX
 SG_ ClntCrcFlwRtEst : 39|8@0+ (0.392157,0) [0|100.000035] "%"  ECC_PB

BO_ 313 Hybrid_Information_LS: 5 CGM_PB
 SG_ OffBrdVehImmbNot : 5|3@0+ (1,0) [0|7] "" Vector__XXX
 SG_ HVInvRatVltV : 2|1@0+ (1,0) [0|1] ""  ECC_PB
 SG_ HybChrgMdStat : 1|2@0+ (1,0) [0|3] "" Vector__XXX
 SG_ HVInvRatVlt : 8|9@0+ (1,0) [0|511] "volts"  ECC_PB
 SG_ ElecPrplsnMtrTach : 28|13@0+ (1,0) [0|8191] "rpm" Vector__XXX

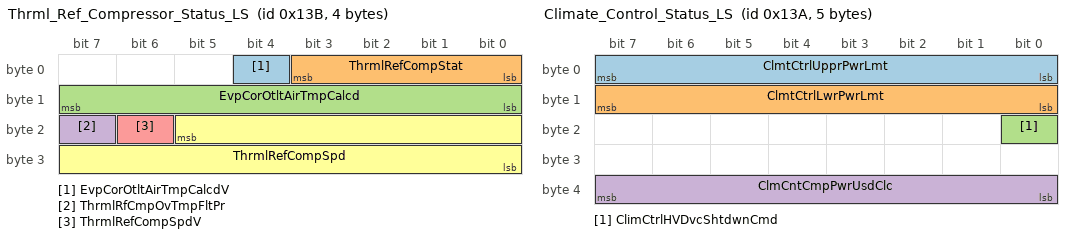
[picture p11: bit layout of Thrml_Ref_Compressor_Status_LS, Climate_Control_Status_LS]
BO_ 315 Thrml_Ref_Compressor_Status_LS: 4 CGM_PB
 SG_ EvpCorOtltAirTmpCalcdV : 4|1@0+ (1,0) [0|1] ""  ECC_PB
 SG_ ThrmlRefCompStat : 3|4@0+ (1,0) [0|15] ""  ECC_PB
 SG_ EvpCorOtltAirTmpCalcd : 15|8@0+ (0.5,-40) [-40|87.5] "degC"  ECC_PB
 SG_ ThrmlRfCmpOvTmpFltPr : 23|1@0+ (1,0) [0|1] ""  ECC_PB
 SG_ ThrmlRefCompSpdV : 22|1@0+ (1,0) [0|1] ""  ECC_PB
 SG_ ThrmlRefCompSpd : 21|14@0+ (1,0) [0|16383] "rpm"  ECC_PB

BO_ 314 Climate_Control_Status_LS: 5 CGM_PB
 SG_ ClmtCtrlUpprPwrLmt : 7|8@0+ (0.1,0) [0|25.5] "kW"  ECC_PB
 SG_ ClmtCtrlLwrPwrLmt : 15|8@0+ (0.1,0) [0|25.5] "kW"  ECC_PB
 SG_ ClimCtrlHVDvcShtdwnCmd : 16|1@0+ (1,0) [0|1] ""  ECC_PB
 SG_ ClmCntCmpPwrUsdClc : 39|8@0+ (0.04,0) [0|10.2] "kW"  ECC_PB

BO_ 317 Aux_Coolant_Heater_Status_LS: 8 CGM_PB
 SG_ LBCCsStAvl : 7|1@0+ (1,0) [0|1] "" Vector__XXX
 SG_ LBCChrgLvlPrfExpIO : 6|1@0+ (1,0) [0|1] "" Vector__XXX
 SG_ AuxClntHtrVlvStat : 5|3@0+ (1,0) [0|7] ""  ECC_PB
 SG_ LBCCsCrStVal : 2|2@0+ (1,0) [0|3] "" Vector__XXX
 SG_ EngAstHtDfrdHtMdAct : 0|1@0+ (1,0) [0|1] ""  ECC_PB
 SG_ LBCCDRR_ClrStrdPosResp : 12|2@0+ (1,0) [0|3] "" Vector__XXX
 SG_ LBCCDRR_PosNumbr : 10|3@0+ (1,0) [0|7] "" Vector__XXX
 SG_ LBCPSS_PosUpdtStat : 20|2@0+ (1,0) [0|3] "" Vector__XXX
 SG_ LBCPSS_PosUpdtLct : 18|3@0+ (1,0) [0|7] "" Vector__XXX
 SG_ LBCCF_Lct1PosStrdIO : 31|1@0+ (1,0) [0|1] "" Vector__XXX
 SG_ LBCCF_Lct2PosStrdIO : 30|1@0+ (1,0) [0|1] "" Vector__XXX
 SG_ LBCCF_Lct3PosStrdIO : 29|1@0+ (1,0) [0|1] "" Vector__XXX
 SG_ LBCCF_Lct4PosStrdIO : 28|1@0+ (1,0) [0|1] "" Vector__XXX
 SG_ LBCVLS_VehGPSLctV : 27|1@0+ (1,0) [0|1] "" Vector__XXX
 SG_ LBCVLS_VehGPSLct : 26|3@0+ (1,0) [0|7] "" Vector__XXX
 SG_ ChrgCyclElecEngyEcnEq : 35|12@0+ (0.1,0) [0|409.5] "km/l" Vector__XXX
 SG_ ChrgCyclOvrlEngyEcnEq : 51|12@0+ (0.1,0) [0|409.5] "km/l" Vector__XXX

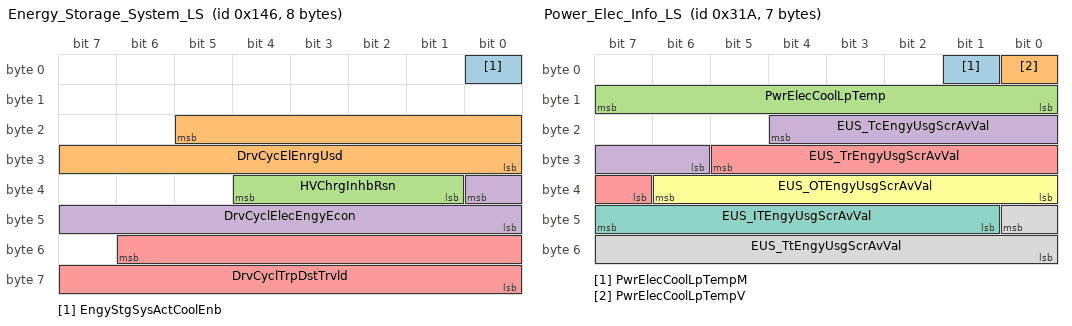
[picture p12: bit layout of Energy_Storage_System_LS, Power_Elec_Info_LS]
BO_ 326 Energy_Storage_System_LS: 8 CGM_PB
 SG_ EngyStgSysActCoolEnb : 0|1@0+ (1,0) [0|1] ""  ECC_PB
 SG_ DrvCycElEnrgUsd : 21|14@0+ (0.36,0) [0|5897.88] "MJ" Vector__XXX
 SG_ HVChrgInhbRsn : 36|4@0+ (1,0) [0|15] "" Vector__XXX
 SG_ DrvCyclElecEngyEcon : 32|9@0+ (0.1,0) [0|51.1] "" Vector__XXX
 SG_ DrvCyclTrpDstTrvld : 54|15@0+ (0.1,0) [0|3276.7] "km" Vector__XXX

BO_ 794 Power_Elec_Info_LS: 7 CGM_PB
 SG_ PwrElecCoolLpTempM : 1|1@0+ (1,0) [0|1] ""  ECC_PB
 SG_ PwrElecCoolLpTempV : 0|1@0+ (1,0) [0|1] ""  ECC_PB
 SG_ PwrElecCoolLpTemp : 15|8@0+ (1,-40) [-40|215] "degC"  ECC_PB
 SG_ EUS_TcEngyUsgScrAvVal : 20|7@0- (0.1,0) [-5|5] "" Vector__XXX
 SG_ EUS_TrEngyUsgScrAvVal : 29|7@0- (0.1,0) [-5|5] "" Vector__XXX
 SG_ EUS_OTEngyUsgScrAvVal : 38|7@0- (0.1,0) [-5|5] "" Vector__XXX
 SG_ EUS_ITEngyUsgScrAvVal : 47|7@0- (0.1,0) [-5|5] "" Vector__XXX
 SG_ EUS_TtEngyUsgScrAvVal : 40|9@0- (0.1,0) [-20|20] "" Vector__XXX

BO_ 1575 Network_Management_Gateway: 8 CGM_PB
 SG_ SrcNodeID : 7|8@0+ (1,0) [0|255] ""  ECC_PB
 SG_ UDat : 23|48@0+ (1,0) [0|281474976710655] ""  ECC_PB

BO_ 1587 Network_Management_PFAF: 8 PFAF_PB
 SG_ SrcNodeID : 7|8@0+ (1,0) [0|255] ""  ECC_PB
 SG_ UDat : 23|48@0+ (1,0) [0|281474976710655] ""  ECC_PB

BO_ 1588 Network_Management_IBOOST: 8 IBOOST_PB
 SG_ SrcNodeID : 7|8@0+ (1,0) [0|255] ""  ECC_PB
 SG_ UDat : 23|48@0+ (1,0) [0|281474976710655] ""  ECC_PB

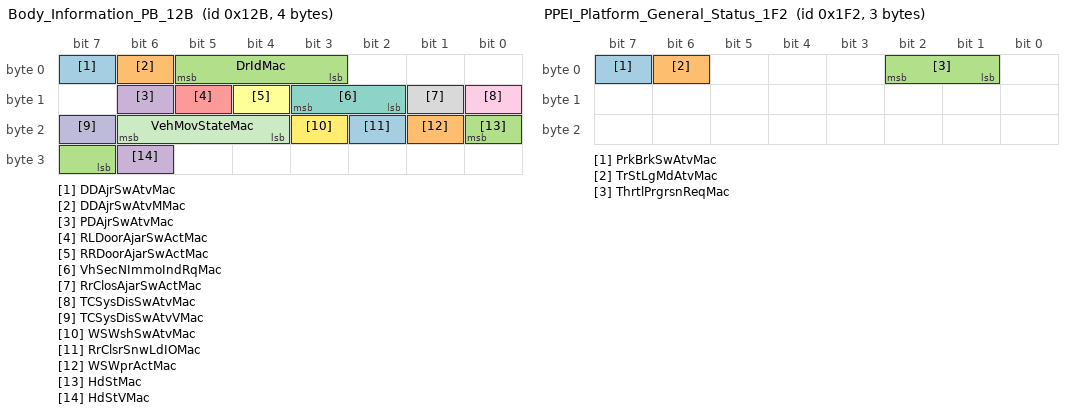
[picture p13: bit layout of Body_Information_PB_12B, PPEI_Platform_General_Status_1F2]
BO_ 299 Body_Information_PB_12B: 4 BCM_PB
 SG_ DDAjrSwAtvMac : 7|1@0+ (1,0) [0|1] "" Vector__XXX
 SG_ DDAjrSwAtvMMac : 6|1@0+ (1,0) [0|1] "" Vector__XXX
 SG_ DrIdMac : 5|3@0+ (1,0) [0|7] ""  ECC_PB
 SG_ PDAjrSwAtvMac : 14|1@0+ (1,0) [0|1] "" Vector__XXX
 SG_ RLDoorAjarSwActMac : 13|1@0+ (1,0) [0|1] "" Vector__XXX
 SG_ RRDoorAjarSwActMac : 12|1@0+ (1,0) [0|1] "" Vector__XXX
 SG_ VhSecNImmoIndRqMac : 11|2@0+ (1,0) [0|3] "" Vector__XXX
 SG_ RrClosAjarSwActMac : 9|1@0+ (1,0) [0|1] "" Vector__XXX
 SG_ TCSysDisSwAtvMac : 8|1@0+ (1,0) [0|1] "" Vector__XXX
 SG_ TCSysDisSwAtvVMac : 23|1@0+ (1,0) [0|1] "" Vector__XXX
 SG_ VehMovStateMac : 22|3@0+ (1,0) [0|7] "" Vector__XXX
 SG_ WSWshSwAtvMac : 19|1@0+ (1,0) [0|1] "" Vector__XXX
 SG_ RrClsrSnwLdIOMac : 18|1@0+ (1,0) [0|1] "" Vector__XXX
 SG_ WSWprActMac : 17|1@0+ (1,0) [0|1] "" Vector__XXX
 SG_ HdStMac : 16|2@0+ (1,0) [0|3] "" Vector__XXX
 SG_ HdStVMac : 30|1@0+ (1,0) [0|1] "" Vector__XXX

BO_ 498 PPEI_Platform_General_Status_1F2: 3 BCM_PB
 SG_ PrkBrkSwAtvMac : 7|1@0+ (1,0) [0|1] "" Vector__XXX
 SG_ TrStLgMdAtvMac : 6|1@0+ (1,0) [0|1] ""  ECC_PB
 SG_ ThrtlPrgrsnReqMac : 2|2@0+ (1,0) [0|3] "" Vector__XXX

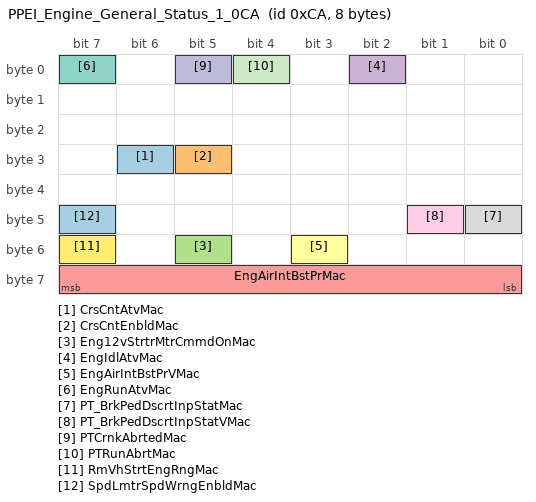
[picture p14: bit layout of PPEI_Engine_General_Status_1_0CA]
BO_ 202 PPEI_Engine_General_Status_1_0CA: 8 ECM_PB
 SG_ CrsCntAtvMac : 30|1@0+ (1,0) [0|1] "" Vector__XXX
 SG_ CrsCntEnbldMac : 29|1@0+ (1,0) [0|1] "" Vector__XXX
 SG_ Eng12vStrtrMtrCmmdOnMac : 53|1@0+ (1,0) [0|1] "" Vector__XXX
 SG_ EngIdlAtvMac : 2|1@0+ (1,0) [0|1] "" Vector__XXX
 SG_ EngAirIntBstPrMac : 63|8@0- (1,0) [-128|127] "kPaG" Vector__XXX
 SG_ EngAirIntBstPrVMac : 51|1@0+ (1,0) [0|1] "" Vector__XXX
 SG_ EngRunAtvMac : 7|1@0+ (1,0) [0|1] ""  ECC_PB
 SG_ PT_BrkPedDscrtInpStatMac : 40|1@0+ (1,0) [0|1] "" Vector__XXX
 SG_ PT_BrkPedDscrtInpStatVMac : 41|1@0+ (1,0) [0|1] "" Vector__XXX
 SG_ PTCrnkAbrtedMac : 5|1@0+ (1,0) [0|1] "" Vector__XXX
 SG_ PTRunAbrtMac : 4|1@0+ (1,0) [0|1] "" Vector__XXX
 SG_ RmVhStrtEngRngMac : 55|1@0+ (1,0) [0|1] ""  ECC_PB
 SG_ SpdLmtrSpdWrngEnbldMac : 47|1@0+ (1,0) [0|1] "" Vector__XXX

BO_TX_BU_ 1122 : APA_PB,SBSA_PB;

BA_DEF_ BO_  "DiagConnection" INT 0 100;
BA_DEF_ BO_  "GenMsgILSupport" ENUM  "No","Yes";
BA_DEF_ BO_  "GenMsgCycleTime" INT 0 100000;
BA_DEF_ BO_  "GenMsgDelayTime" INT 0 100000;
BA_DEF_ BO_  "DiagRequest" ENUM  "No","Yes";
BA_DEF_ BO_  "DiagResponse" ENUM  "No","Yes";
BA_DEF_ BO_  "DiagState" ENUM  "No","Yes";
BA_DEF_ BO_  "MessageSubnet" ENUM  "BB","PB","CB","Body","HS","Powertrain","Chassis","Spare","PE","CC";
BA_DEF_ BO_  "TpTxIndex" INT 0 99;
BA_DEF_ BO_  "GenMsgStartDelayTime" INT 0 100000;
BA_DEF_ SG_  "GenSigStartValue" INT 0 65535;
BA_DEF_ SG_  "SignalLongName" STRING ;
BA_DEF_ SG_  "SignalType" STRING ;
BA_DEF_ SG_  "GenSigDeltaValue" INT 0 65535;
BA_DEF_ SG_  "GenSigSendOnInit" ENUM  "Not Initialized","Application","Handler";
BA_DEF_ BO_  "GenMsgSendType" ENUM  "Cyclic","NotUsed","NotUsed","NotUsed","NotUsed","NotUsed","NotUsed","NotUsed","NoMsgSendType";
BA_DEF_ BO_  "NmAsrMessage" ENUM  "No","Yes";
BA_DEF_ BO_  "DiagUUDTResponse" ENUM  "No","Yes";
BA_DEF_ SG_  "GenSigSendType" ENUM  "NotUsed","OnWrite","OnWriteWithRepetition","OnChange","OnChangeWithRepetition","IfActive","IfActiveWithRepeition","NoSigSendType";
BA_DEF_ BO_  "SystemMessageLongSymbol" STRING ;
BA_DEF_REL_ BU_SG_REL_  "GenSigTimeoutMsg" HEX 0 2032;
BA_DEF_REL_ BU_SG_REL_  "GenSigTimeoutTime" INT 0 15000;
BA_DEF_REL_ BU_SG_REL_  "GenSigSuprvResp" ENUM  "None","Notify App","Substitute Default";
BA_DEF_REL_ BU_SG_REL_  "GenSigSuprvRespSubValue" INT 0 65535;
BA_DEF_REL_ BU_SG_REL_  "GenSigVBitResp" ENUM  "No","Yes";
BA_DEF_REL_ BU_SG_REL_  "GenSigVBitRespComment" STRING ;
BA_DEF_REL_ BU_SG_REL_  "GenSigVDAFailResp" ENUM  "No","Yes";
BA_DEF_REL_ BU_SG_REL_  "GenSigRxStartValue" STRING ;
BA_DEF_REL_ BU_SG_REL_  "GenSigVDAFailComment" STRING ;
BA_DEF_DEF_  "DiagConnection" 0;
BA_DEF_DEF_  "GenMsgILSupport" "Yes";
BA_DEF_DEF_  "GenMsgCycleTime" 0;
BA_DEF_DEF_  "GenMsgDelayTime" 0;
BA_DEF_DEF_  "DiagRequest" "No";
BA_DEF_DEF_  "DiagResponse" "No";
BA_DEF_DEF_  "DiagState" "No";
BA_DEF_DEF_  "MessageSubnet" "Body";
BA_DEF_DEF_  "TpTxIndex" 0;
BA_DEF_DEF_  "GenMsgStartDelayTime" 0;
BA_DEF_DEF_  "GenSigStartValue" 0;
BA_DEF_DEF_  "SignalLongName" "";
BA_DEF_DEF_  "SignalType" "";
BA_DEF_DEF_  "GenSigDeltaValue" 0;
BA_DEF_DEF_  "GenSigSendOnInit" "Not Initialized";
BA_DEF_DEF_  "GenMsgSendType" "NoMsgSendType";
BA_DEF_DEF_  "NmAsrMessage" "No";
BA_DEF_DEF_  "DiagUUDTResponse" "No";
BA_DEF_DEF_  "GenSigSendType" "NoSigSendType";
BA_DEF_DEF_REL_ "GenSigTimeoutMsg" 0;
BA_DEF_DEF_REL_ "GenSigTimeoutTime" 0;
BA_DEF_DEF_REL_ "GenSigSuprvResp" "None";
BA_DEF_DEF_REL_ "GenSigSuprvRespSubValue" 0;
BA_DEF_DEF_REL_ "GenSigVBitResp" "No";
BA_DEF_DEF_REL_ "GenSigVBitRespComment" "";
BA_DEF_DEF_REL_ "GenSigVDAFailResp" "No";
BA_DEF_DEF_REL_ "GenSigRxStartValue" "";
BA_DEF_DEF_REL_ "GenSigVDAFailComment" "";
BA_DEF_DEF_  "SystemMessageLongSymbol" "";
BA_ "MessageSubnet" BO_ 914 1;
BA_ "GenMsgDelayTime" BO_ 914 100;
BA_ "GenMsgCycleTime" BO_ 914 1000;
BA_ "GenMsgSendType" BO_ 914 0;
BA_ "MessageSubnet" BO_ 950 1;
BA_ "GenMsgDelayTime" BO_ 950 100;
BA_ "GenMsgCycleTime" BO_ 950 1000;
BA_ "GenMsgSendType" BO_ 950 0;
BA_ "MessageSubnet" BO_ 850 1;
BA_ "GenMsgDelayTime" BO_ 850 100;
BA_ "MessageSubnet" BO_ 851 1;
BA_ "GenMsgDelayTime" BO_ 851 100;
BA_ "MessageSubnet" BO_ 881 1;
BA_ "GenMsgDelayTime" BO_ 881 10;
BA_ "MessageSubnet" BO_ 883 1;
BA_ "GenMsgDelayTime" BO_ 883 200;
BA_ "MessageSubnet" BO_ 948 1;
BA_ "GenMsgDelayTime" BO_ 948 100;
BA_ "GenMsgCycleTime" BO_ 948 1000;
BA_ "GenMsgSendType" BO_ 948 0;
BA_ "MessageSubnet" BO_ 1061 1;
BA_ "GenMsgDelayTime" BO_ 1061 30;
BA_ "GenMsgCycleTime" BO_ 1061 100;
BA_ "GenMsgSendType" BO_ 1061 0;
BA_ "MessageSubnet" BO_ 1138 1;
BA_ "GenMsgDelayTime" BO_ 1138 500;
BA_ "MessageSubnet" BO_ 1136 1;
BA_ "GenMsgDelayTime" BO_ 1136 100;
BA_ "MessageSubnet" BO_ 2430336753 1;
BA_ "GenMsgILSupport" BO_ 2430336753 0;
BA_ "DiagState" BO_ 2430336753 1;
BA_ "DiagConnection" BO_ 2430336753 2;
BA_ "MessageSubnet" BO_ 2430336755 1;
BA_ "GenMsgILSupport" BO_ 2430336755 0;
BA_ "DiagState" BO_ 2430336755 1;
BA_ "DiagConnection" BO_ 2430336755 1;
BA_ "MessageSubnet" BO_ 2497376665 1;
BA_ "DiagResponse" BO_ 2497376665 1;
BA_ "DiagConnection" BO_ 2497376665 2;
BA_ "MessageSubnet" BO_ 2497507737 1;
BA_ "GenMsgILSupport" BO_ 2497507737 0;
BA_ "DiagUUDTResponse" BO_ 2497507737 1;
BA_ "DiagConnection" BO_ 2497507737 2;
BA_ "MessageSubnet" BO_ 2497377177 1;
BA_ "DiagResponse" BO_ 2497377177 1;
BA_ "DiagConnection" BO_ 2497377177 1;
BA_ "MessageSubnet" BO_ 2497508249 1;
BA_ "GenMsgILSupport" BO_ 2497508249 0;
BA_ "DiagUUDTResponse" BO_ 2497508249 1;
BA_ "DiagConnection" BO_ 2497508249 1;
BA_ "MessageSubnet" BO_ 2497354225 1;
BA_ "DiagRequest" BO_ 2497354225 1;
BA_ "DiagConnection" BO_ 2497354225 2;
BA_ "MessageSubnet" BO_ 2497354227 1;
BA_ "DiagRequest" BO_ 2497354227 1;
BA_ "DiagConnection" BO_ 2497354227 1;
BA_ "MessageSubnet" BO_ 1088 1;
BA_ "GenMsgDelayTime" BO_ 1088 10;
BA_ "MessageSubnet" BO_ 1089 1;
BA_ "GenMsgDelayTime" BO_ 1089 10;
BA_ "MessageSubnet" BO_ 1122 1;
BA_ "GenMsgDelayTime" BO_ 1122 10;
BA_ "MessageSubnet" BO_ 1091 1;
BA_ "GenMsgDelayTime" BO_ 1091 10;
BA_ "MessageSubnet" BO_ 1093 1;
BA_ "GenMsgDelayTime" BO_ 1093 10;
BA_ "MessageSubnet" BO_ 1094 1;
BA_ "GenMsgDelayTime" BO_ 1094 10;
BA_ "MessageSubnet" BO_ 1095 1;
BA_ "GenMsgDelayTime" BO_ 1095 10;
BA_ "MessageSubnet" BO_ 1096 1;
BA_ "GenMsgDelayTime" BO_ 1096 10;
BA_ "SystemMessageLongSymbol" BO_ 1096 "Re_Initialization_Request_RadioHead";
BA_ "MessageSubnet" BO_ 1097 1;
BA_ "GenMsgDelayTime" BO_ 1097 10;
BA_ "MessageSubnet" BO_ 502 1;
BA_ "GenMsgDelayTime" BO_ 502 30;
BA_ "GenMsgCycleTime" BO_ 502 100;
BA_ "GenMsgStartDelayTime" BO_ 502 10;
BA_ "GenMsgSendType" BO_ 502 0;
BA_ "SystemMessageLongSymbol" BO_ 502 "PPEI_Platform_General_Status_1F6_M";
BA_ "MessageSubnet" BO_ 291 1;
BA_ "GenMsgCycleTime" BO_ 291 100;
BA_ "GenMsgSendType" BO_ 291 0;
BA_ "SystemMessageLongSymbol" BO_ 291 "System_Power_Mode_Backup_IPC_PB_123_M";
BA_ "MessageSubnet" BO_ 1003 1;
BA_ "GenMsgCycleTime" BO_ 1003 100;
BA_ "GenMsgSendType" BO_ 1003 0;
BA_ "SystemMessageLongSymbol" BO_ 1003 "PPEI_Vehicle_Speed_and_Distance_3EB_M1";
BA_ "MessageSubnet" BO_ 203 1;
BA_ "GenMsgCycleTime" BO_ 203 12;
BA_ "GenMsgSendType" BO_ 203 0;
BA_ "SystemMessageLongSymbol" BO_ 203 "PPEI_Engine_General_Status_1_0CB_M";
BA_ "MessageSubnet" BO_ 1630 1;
BA_ "GenMsgCycleTime" BO_ 1630 100;
BA_ "GenMsgSendType" BO_ 1630 0;
BA_ "SystemMessageLongSymbol" BO_ 1630 "Climate_Control_Customization_Info_1";
BA_ "MessageSubnet" BO_ 1638 1;
BA_ "GenMsgCycleTime" BO_ 1638 100;
BA_ "GenMsgSendType" BO_ 1638 0;
BA_ "SystemMessageLongSymbol" BO_ 1638 "Climate_Control_Customization_Info_2";
BA_ "MessageSubnet" BO_ 1631 1;
BA_ "GenMsgCycleTime" BO_ 1631 100;
BA_ "GenMsgSendType" BO_ 1631 0;
BA_ "SystemMessageLongSymbol" BO_ 1631 "Climate_Control_Customization_Req_1";
BA_ "MessageSubnet" BO_ 1639 1;
BA_ "GenMsgDelayTime" BO_ 1639 100;
BA_ "GenMsgCycleTime" BO_ 1639 1000;
BA_ "GenMsgSendType" BO_ 1639 0;
BA_ "SystemMessageLongSymbol" BO_ 1639 "Climate_Control_Customization_Req_2";
BA_ "MessageSubnet" BO_ 1704 1;
BA_ "GenMsgDelayTime" BO_ 1704 25;
BA_ "GenMsgCycleTime" BO_ 1704 100;
BA_ "GenMsgSendType" BO_ 1704 0;
BA_ "SystemMessageLongSymbol" BO_ 1704 "Restore_Customization_Defaults_Req";
BA_ "MessageSubnet" BO_ 1713 1;
BA_ "GenMsgDelayTime" BO_ 1713 10;
BA_ "GenMsgCycleTime" BO_ 1713 500;
BA_ "GenMsgSendType" BO_ 1713 0;
BA_ "MessageSubnet" BO_ 1716 1;
BA_ "GenMsgDelayTime" BO_ 1716 10;
BA_ "GenMsgCycleTime" BO_ 1716 500;
BA_ "GenMsgSendType" BO_ 1716 0;
BA_ "MessageSubnet" BO_ 1717 1;
BA_ "GenMsgDelayTime" BO_ 1717 10;
BA_ "GenMsgCycleTime" BO_ 1717 500;
BA_ "GenMsgSendType" BO_ 1717 0;
BA_ "MessageSubnet" BO_ 858 1;
BA_ "GenMsgDelayTime" BO_ 858 100;
BA_ "MessageSubnet" BO_ 859 1;
BA_ "GenMsgDelayTime" BO_ 859 100;
BA_ "MessageSubnet" BO_ 1147 1;
BA_ "GenMsgDelayTime" BO_ 1147 500;
BA_ "SystemMessageLongSymbol" BO_ 1147 "Cellular_Network_Date_and_Time_47B_M2";
BA_ "MessageSubnet" BO_ 1150 1;
BA_ "GenMsgDelayTime" BO_ 1150 100;
BA_ "MessageSubnet" BO_ 1151 1;
BA_ "GenMsgDelayTime" BO_ 1151 100;
BA_ "MessageSubnet" BO_ 921 1;
BA_ "GenMsgCycleTime" BO_ 921 1000;
BA_ "GenMsgSendType" BO_ 921 0;
BA_ "MessageSubnet" BO_ 874 1;
BA_ "GenMsgDelayTime" BO_ 874 100;
BA_ "MessageSubnet" BO_ 912 1;
BA_ "GenMsgDelayTime" BO_ 912 100;
BA_ "MessageSubnet" BO_ 965 1;
BA_ "GenMsgDelayTime" BO_ 965 100;
BA_ "GenMsgCycleTime" BO_ 965 250;
BA_ "GenMsgStartDelayTime" BO_ 965 10;
BA_ "GenMsgSendType" BO_ 965 0;
BA_ "MessageSubnet" BO_ 313 1;
BA_ "GenMsgCycleTime" BO_ 313 250;
BA_ "GenMsgSendType" BO_ 313 0;
BA_ "MessageSubnet" BO_ 315 1;
BA_ "GenMsgDelayTime" BO_ 315 100;
BA_ "MessageSubnet" BO_ 314 1;
BA_ "GenMsgDelayTime" BO_ 314 100;
BA_ "MessageSubnet" BO_ 317 1;
BA_ "GenMsgDelayTime" BO_ 317 100;
BA_ "MessageSubnet" BO_ 326 1;
BA_ "GenMsgDelayTime" BO_ 326 100;
BA_ "MessageSubnet" BO_ 794 1;
BA_ "GenMsgDelayTime" BO_ 794 100;
BA_ "MessageSubnet" BO_ 1575 1;
BA_ "NmAsrMessage" BO_ 1575 1;
BA_ "GenMsgCycleTime" BO_ 1575 640;
BA_ "GenMsgSendType" BO_ 1575 0;
BA_ "MessageSubnet" BO_ 1587 1;
BA_ "NmAsrMessage" BO_ 1587 1;
BA_ "GenMsgCycleTime" BO_ 1587 640;
BA_ "GenMsgSendType" BO_ 1587 0;
BA_ "MessageSubnet" BO_ 1588 1;
BA_ "NmAsrMessage" BO_ 1588 1;
BA_ "GenMsgCycleTime" BO_ 1588 640;
BA_ "GenMsgSendType" BO_ 1588 0;
BA_ "MessageSubnet" BO_ 299 1;
BA_ "GenMsgCycleTime" BO_ 299 100;
BA_ "GenMsgStartDelayTime" BO_ 299 40;
BA_ "GenMsgSendType" BO_ 299 0;
BA_ "MessageSubnet" BO_ 498 1;
BA_ "GenMsgDelayTime" BO_ 498 30;
BA_ "GenMsgCycleTime" BO_ 498 100;
BA_ "GenMsgStartDelayTime" BO_ 498 10;
BA_ "GenMsgSendType" BO_ 498 0;
BA_ "MessageSubnet" BO_ 202 1;
BA_ "GenMsgCycleTime" BO_ 202 12;
BA_ "GenMsgSendType" BO_ 202 0;
BA_ "SignalLongName" SG_ 914 PassHCSeatSw3Act "Passenger Heated/Cooled Seat Switch #3 Active";
BA_ "SignalType" SG_ 914 PassHCSeatSw3Act "BLN";
BA_ "GenSigSendType" SG_ 914 PassHCSeatSw3Act 1;
BA_ "GenSigSendOnInit" SG_ 914 PassHCSeatSw3Act 1;
BA_ "SignalLongName" SG_ 914 PassHCSeatSw2Act "Passenger Heated/Cooled Seat Switch #2 Active";
BA_ "SignalType" SG_ 914 PassHCSeatSw2Act "BLN";
BA_ "GenSigSendType" SG_ 914 PassHCSeatSw2Act 1;
BA_ "GenSigSendOnInit" SG_ 914 PassHCSeatSw2Act 1;
BA_ "SignalLongName" SG_ 914 PassHCSeatSw1Act "Passenger Heated/Cooled Seat Switch #1 Active";
BA_ "SignalType" SG_ 914 PassHCSeatSw1Act "BLN";
BA_ "GenSigSendType" SG_ 914 PassHCSeatSw1Act 1;
BA_ "GenSigSendOnInit" SG_ 914 PassHCSeatSw1Act 1;
BA_ "SignalLongName" SG_ 914 DrvHCSeatSw3Act "Driver Heated/Cooled Seat Switch #3 Active";
BA_ "SignalType" SG_ 914 DrvHCSeatSw3Act "BLN";
BA_ "GenSigSendType" SG_ 914 DrvHCSeatSw3Act 1;
BA_ "GenSigSendOnInit" SG_ 914 DrvHCSeatSw3Act 1;
BA_ "SignalLongName" SG_ 914 DrvHCSeatSw2Act "Driver Heated/Cooled Seat Switch #2 Active";
BA_ "SignalType" SG_ 914 DrvHCSeatSw2Act "BLN";
BA_ "GenSigSendType" SG_ 914 DrvHCSeatSw2Act 1;
BA_ "GenSigSendOnInit" SG_ 914 DrvHCSeatSw2Act 1;
BA_ "SignalLongName" SG_ 914 DrvHCSeatSw1Act "Driver Heated/Cooled Seat Switch #1 Active";
BA_ "SignalType" SG_ 914 DrvHCSeatSw1Act "BLN";
BA_ "GenSigSendType" SG_ 914 DrvHCSeatSw1Act 1;
BA_ "GenSigSendOnInit" SG_ 914 DrvHCSeatSw1Act 1;
BA_ "SignalLongName" SG_ 950 RRHCSeatSw3Act "Rear Right Heated/Cooled Seat Switch #3 Active";
BA_ "SignalType" SG_ 950 RRHCSeatSw3Act "BLN";
BA_ "GenSigSendType" SG_ 950 RRHCSeatSw3Act 1;
BA_ "GenSigSendOnInit" SG_ 950 RRHCSeatSw3Act 1;
BA_ "SignalLongName" SG_ 950 RRHCSeatSw2Act "Rear Right Heated/Cooled Seat Switch #2 Active";
BA_ "SignalType" SG_ 950 RRHCSeatSw2Act "BLN";
BA_ "GenSigSendType" SG_ 950 RRHCSeatSw2Act 1;
BA_ "GenSigSendOnInit" SG_ 950 RRHCSeatSw2Act 1;
BA_ "SignalLongName" SG_ 950 RRHCSeatSw1Act "Rear Right Heated/Cooled Seat Switch #1 Active";
BA_ "SignalType" SG_ 950 RRHCSeatSw1Act "BLN";
BA_ "GenSigSendType" SG_ 950 RRHCSeatSw1Act 1;
BA_ "GenSigSendOnInit" SG_ 950 RRHCSeatSw1Act 1;
BA_ "SignalLongName" SG_ 950 RLHCSeatSw3Act "Rear Left Heated/Cooled Seat Switch #3 Active";
BA_ "SignalType" SG_ 950 RLHCSeatSw3Act "BLN";
BA_ "GenSigSendType" SG_ 950 RLHCSeatSw3Act 1;
BA_ "GenSigSendOnInit" SG_ 950 RLHCSeatSw3Act 1;
BA_ "SignalLongName" SG_ 950 RLHCSeatSw2Act "Rear Left Heated/Cooled Seat Switch #2 Active";
BA_ "SignalType" SG_ 950 RLHCSeatSw2Act "BLN";
BA_ "GenSigSendType" SG_ 950 RLHCSeatSw2Act 1;
BA_ "GenSigSendOnInit" SG_ 950 RLHCSeatSw2Act 1;
BA_ "SignalLongName" SG_ 950 RLHCSeatSw1Act "Rear Left Heated/Cooled Seat Switch #1 Active";
BA_ "SignalType" SG_ 950 RLHCSeatSw1Act "BLN";
BA_ "GenSigSendType" SG_ 950 RLHCSeatSw1Act 1;
BA_ "GenSigSendOnInit" SG_ 950 RLHCSeatSw1Act 1;
BA_ "SignalLongName" SG_ 850 PsngSysLatV "Positioning System Latitude Validity";
BA_ "SignalType" SG_ 850 PsngSysLatV "ENM";
BA_ "GenSigSendType" SG_ 850 PsngSysLatV 1;
BA_ "SignalLongName" SG_ 850 PsngSysLat "Positioning System Latitude";
BA_ "SignalType" SG_ 850 PsngSysLat "SNM";
BA_ "GenSigDeltaValue" SG_ 850 PsngSysLat 10;
BA_ "GenSigSendType" SG_ 850 PsngSysLat 1;
BA_ "GenSigSendOnInit" SG_ 850 PsngSysLat 1;
BA_ "SignalLongName" SG_ 850 PsngSysLongV "Positioning System Longitude Validity";
BA_ "SignalType" SG_ 850 PsngSysLongV "ENM";
BA_ "GenSigSendType" SG_ 850 PsngSysLongV 1;
BA_ "SignalLongName" SG_ 850 PsngSysLong "Positioning System Longitude";
BA_ "SignalType" SG_ 850 PsngSysLong "SNM";
BA_ "GenSigDeltaValue" SG_ 850 PsngSysLong 10;
BA_ "GenSigSendType" SG_ 850 PsngSysLong 1;
BA_ "SignalLongName" SG_ 851 PsngSysDilPrcsV "Positioning System Dilution of Precision Validity";
BA_ "SignalType" SG_ 851 PsngSysDilPrcsV "ENM";
BA_ "GenSigSendType" SG_ 851 PsngSysDilPrcsV 1;
BA_ "SignalLongName" SG_ 851 PsngSysHding "Positioning System Heading";
BA_ "SignalType" SG_ 851 PsngSysHding "UNM";
BA_ "GenSigDeltaValue" SG_ 851 PsngSysHding 50;
BA_ "GenSigSendType" SG_ 851 PsngSysHding 1;
BA_ "SignalLongName" SG_ 851 PsngSysDilPrcs "Positioning System Dilution of Precision";
BA_ "SignalType" SG_ 851 PsngSysDilPrcs "UNM";
BA_ "GenSigDeltaValue" SG_ 851 PsngSysDilPrcs 10;
BA_ "GenSigSendType" SG_ 851 PsngSysDilPrcs 1;
BA_ "SignalLongName" SG_ 851 PsngSysCalcSpd "Positioning System Calculated Speed";
BA_ "SignalType" SG_ 851 PsngSysCalcSpd "UNM";
BA_ "GenSigDeltaValue" SG_ 851 PsngSysCalcSpd 5;
BA_ "GenSigSendType" SG_ 851 PsngSysCalcSpd 1;
BA_ "SignalLongName" SG_ 851 PsngSysHdingV "Positioning System Heading Validity";
BA_ "SignalType" SG_ 851 PsngSysHdingV "ENM";
BA_ "GenSigSendType" SG_ 851 PsngSysHdingV 1;
BA_ "SignalLongName" SG_ 851 PsngSysCalcSpdV "Positioning System Calculated Speed Validity";
BA_ "SignalType" SG_ 851 PsngSysCalcSpdV "ENM";
BA_ "GenSigSendType" SG_ 851 PsngSysCalcSpdV 1;
BA_ "SignalLongName" SG_ 851 PsngSysElvtnV "Positioning System Elevation Validity";
BA_ "SignalType" SG_ 851 PsngSysElvtnV "ENM";
BA_ "GenSigSendType" SG_ 851 PsngSysElvtnV 1;
BA_ "SignalLongName" SG_ 851 PsngSysElvtn "Positioning System Elevation";
BA_ "SignalType" SG_ 851 PsngSysElvtn "UNM";
BA_ "GenSigDeltaValue" SG_ 851 PsngSysElvtn 100;
BA_ "GenSigSendType" SG_ 851 PsngSysElvtn 1;
BA_ "SignalLongName" SG_ 881 LgclAVChnl "Logical AV Channel";
BA_ "SignalType" SG_ 881 LgclAVChnl "ENM";
BA_ "GenSigSendType" SG_ 881 LgclAVChnl 1;
BA_ "SignalLongName" SG_ 881 ASSAudSrcType "Audio Source Status : Audio Source Type";
BA_ "SignalType" SG_ 881 ASSAudSrcType "ENM";
BA_ "GenSigSendType" SG_ 881 ASSAudSrcType 1;
BA_ "SignalLongName" SG_ 881 ASSAudSrcChType "Audio Source Status : Audio Source Channel Type";
BA_ "SignalType" SG_ 881 ASSAudSrcChType "ENM";
BA_ "GenSigSendType" SG_ 881 ASSAudSrcChType 1;
BA_ "SignalLongName" SG_ 881 ASSAudSrcStatCode "Audio Source Status : Audio Source Status Code";
BA_ "SignalType" SG_ 881 ASSAudSrcStatCode "ENM";
BA_ "GenSigSendType" SG_ 881 ASSAudSrcStatCode 1;
BA_ "SignalLongName" SG_ 883 ASS2AudSrcType "Audio Source Status 2 : Audio Source Type";
BA_ "SignalType" SG_ 883 ASS2AudSrcType "ENM";
BA_ "GenSigSendType" SG_ 883 ASS2AudSrcType 1;
BA_ "SignalLongName" SG_ 883 ASS2AudSrcChType "Audio Source Status 2 : Audio Source Channel Type";
BA_ "SignalType" SG_ 883 ASS2AudSrcChType "ENM";
BA_ "GenSigSendType" SG_ 883 ASS2AudSrcChType 1;
BA_ "SignalLongName" SG_ 883 ASS2AudSrcStatCode "Audio Source Status 2 : Audio Source Status Code";
BA_ "SignalType" SG_ 883 ASS2AudSrcStatCode "ENM";
BA_ "GenSigSendType" SG_ 883 ASS2AudSrcStatCode 1;
BA_ "SignalLongName" SG_ 948 RLHCSMIndReq "Rear Left Heated/Cooled Seat Mode Indication Control : Indication Request";
BA_ "SignalType" SG_ 948 RLHCSMIndReq "ENM";
BA_ "GenSigSendType" SG_ 948 RLHCSMIndReq 1;
BA_ "SignalLongName" SG_ 948 RLHCSMInd1 "Rear Left Heated/Cooled Seat Mode Indication Control : Seat Mode Indication 1";
BA_ "SignalType" SG_ 948 RLHCSMInd1 "BLN";
BA_ "GenSigSendType" SG_ 948 RLHCSMInd1 1;
BA_ "SignalLongName" SG_ 948 RLHCSMInd2 "Rear Left Heated/Cooled Seat Mode Indication Control : Seat Mode Indication 2";
BA_ "SignalType" SG_ 948 RLHCSMInd2 "BLN";
BA_ "GenSigSendType" SG_ 948 RLHCSMInd2 1;
BA_ "SignalLongName" SG_ 948 RLHCSMInd3 "Rear Left Heated/Cooled Seat Mode Indication Control : Seat Mode Indication 3";
BA_ "SignalType" SG_ 948 RLHCSMInd3 "BLN";
BA_ "GenSigSendType" SG_ 948 RLHCSMInd3 1;
BA_ "SignalLongName" SG_ 948 RRHCSMIndReq "Rear Right Heated/Cooled Seat Mode Indication Control : Indication Request";
BA_ "SignalType" SG_ 948 RRHCSMIndReq "ENM";
BA_ "GenSigSendType" SG_ 948 RRHCSMIndReq 1;
BA_ "SignalLongName" SG_ 948 RRHCSMInd1 "Rear Right Heated/Cooled Seat Mode Indication Control : Seat Mode Indication 1";
BA_ "SignalType" SG_ 948 RRHCSMInd1 "BLN";
BA_ "GenSigSendType" SG_ 948 RRHCSMInd1 1;
BA_ "SignalLongName" SG_ 948 RRHCSMInd2 "Rear Right Heated/Cooled Seat Mode Indication Control : Seat Mode Indication 2";
BA_ "SignalType" SG_ 948 RRHCSMInd2 "BLN";
BA_ "GenSigSendType" SG_ 948 RRHCSMInd2 1;
BA_ "SignalLongName" SG_ 948 RRHCSMInd3 "Rear Right Heated/Cooled Seat Mode Indication Control : Seat Mode Indication 3";
BA_ "SignalType" SG_ 948 RRHCSMInd3 "BLN";
BA_ "GenSigSendType" SG_ 948 RRHCSMInd3 1;
BA_ "SignalLongName" SG_ 948 RLHCSLIndReq "Rear Left Heated/Cooled Seat Level Indication Control : Indication Request";
BA_ "SignalType" SG_ 948 RLHCSLIndReq "ENM";
BA_ "GenSigSendType" SG_ 948 RLHCSLIndReq 1;
BA_ "SignalLongName" SG_ 948 RLHCSLSeatLev1 "Rear Left Heated/Cooled Seat Level Indication Control : Seat Level 1";
BA_ "SignalType" SG_ 948 RLHCSLSeatLev1 "BLN";
BA_ "GenSigSendType" SG_ 948 RLHCSLSeatLev1 1;
BA_ "SignalLongName" SG_ 948 RLHCSLSeatLev2 "Rear Left Heated/Cooled Seat Level Indication Control : Seat Level 2";
BA_ "SignalType" SG_ 948 RLHCSLSeatLev2 "BLN";
BA_ "GenSigSendType" SG_ 948 RLHCSLSeatLev2 1;
BA_ "SignalLongName" SG_ 948 RLHCSLSeatLev3 "Rear Left Heated/Cooled Seat Level Indication Control : Seat Level 3";
BA_ "SignalType" SG_ 948 RLHCSLSeatLev3 "BLN";
BA_ "GenSigSendType" SG_ 948 RLHCSLSeatLev3 1;
BA_ "SignalLongName" SG_ 948 RLHCSLSeatLev4 "Rear Left Heated/Cooled Seat Level Indication Control : Seat Level 4";
BA_ "SignalType" SG_ 948 RLHCSLSeatLev4 "BLN";
BA_ "GenSigSendType" SG_ 948 RLHCSLSeatLev4 1;
BA_ "SignalLongName" SG_ 948 RLHCSLSeatLev5 "Rear Left Heated/Cooled Seat Level Indication Control : Seat Level 5";
BA_ "SignalType" SG_ 948 RLHCSLSeatLev5 "BLN";
BA_ "GenSigSendType" SG_ 948 RLHCSLSeatLev5 1;
BA_ "SignalLongName" SG_ 948 RRHCSLIndReq "Rear Right Heated/Cooled Seat Level Indication Control : Indication Request";
BA_ "SignalType" SG_ 948 RRHCSLIndReq "ENM";
BA_ "GenSigSendType" SG_ 948 RRHCSLIndReq 1;
BA_ "SignalLongName" SG_ 948 RRHCSLSeatLev1 "Rear Right Heated/Cooled Seat Level Indication Control : Seat Level 1";
BA_ "SignalType" SG_ 948 RRHCSLSeatLev1 "BLN";
BA_ "GenSigSendType" SG_ 948 RRHCSLSeatLev1 1;
BA_ "SignalLongName" SG_ 948 RRHCSLSeatLev2 "Rear Right Heated/Cooled Seat Level Indication Control : Seat Level 2";
BA_ "SignalType" SG_ 948 RRHCSLSeatLev2 "BLN";
BA_ "GenSigSendType" SG_ 948 RRHCSLSeatLev2 1;
BA_ "SignalLongName" SG_ 948 RRHCSLSeatLev3 "Rear Right Heated/Cooled Seat Level Indication Control : Seat Level 3";
BA_ "SignalType" SG_ 948 RRHCSLSeatLev3 "BLN";
BA_ "GenSigSendType" SG_ 948 RRHCSLSeatLev3 1;
BA_ "SignalLongName" SG_ 948 RRHCSLSeatLev4 "Rear Right Heated/Cooled Seat Level Indication Control : Seat Level 4";
BA_ "SignalType" SG_ 948 RRHCSLSeatLev4 "BLN";
BA_ "GenSigSendType" SG_ 948 RRHCSLSeatLev4 1;
BA_ "SignalLongName" SG_ 948 RRHCSLSeatLev5 "Rear Right Heated/Cooled Seat Level Indication Control : Seat Level 5";
BA_ "SignalType" SG_ 948 RRHCSLSeatLev5 "BLN";
BA_ "GenSigSendType" SG_ 948 RRHCSLSeatLev5 1;
BA_ "SignalLongName" SG_ 1061 DispMeasSys "Display Measurement System";
BA_ "SignalType" SG_ 1061 DispMeasSys "ENM";
BA_ "GenSigSendType" SG_ 1061 DispMeasSys 1;
BA_ "GenSigSendOnInit" SG_ 1061 DispMeasSys 1;
BA_ "SignalLongName" SG_ 1061 DispMeasSysExt "Display Measurement System Extended";
BA_ "SignalType" SG_ 1061 DispMeasSysExt "ENM";
BA_ "GenSigSendType" SG_ 1061 DispMeasSysExt 1;
BA_ "GenSigSendOnInit" SG_ 1061 DispMeasSysExt 1;
BA_ "SignalLongName" SG_ 1138 SecCmpstdValV "Seconds Compensated Value Validity";
BA_ "SignalType" SG_ 1138 SecCmpstdValV "ENM";
BA_ "GenSigSendType" SG_ 1138 SecCmpstdValV 1;
BA_ "SignalLongName" SG_ 1138 MinsCmpstdValV "Minutes Compensated Value Validity";
BA_ "SignalType" SG_ 1138 MinsCmpstdValV "ENM";
BA_ "GenSigSendType" SG_ 1138 MinsCmpstdValV 1;
BA_ "SignalLongName" SG_ 1138 HrsCmpstdValV "Hours Compensated Value Validity";
BA_ "SignalType" SG_ 1138 HrsCmpstdValV "ENM";
BA_ "GenSigSendType" SG_ 1138 HrsCmpstdValV 1;
BA_ "SignalLongName" SG_ 1138 CldrDayCmpstdVal "Calendar Day Compensated Value";
BA_ "SignalType" SG_ 1138 CldrDayCmpstdVal "UNM";
BA_ "GenSigDeltaValue" SG_ 1138 CldrDayCmpstdVal 1;
BA_ "GenSigSendType" SG_ 1138 CldrDayCmpstdVal 1;
BA_ "SignalLongName" SG_ 1138 CldrMthCmpstdVal "Calendar Month Compensated Value";
BA_ "SignalType" SG_ 1138 CldrMthCmpstdVal "ENM";
BA_ "GenSigSendType" SG_ 1138 CldrMthCmpstdVal 1;
BA_ "SignalLongName" SG_ 1138 CldrYrCmpstdVal "Calendar Year Compensated Value";
BA_ "SignalType" SG_ 1138 CldrYrCmpstdVal "UNM";
BA_ "GenSigDeltaValue" SG_ 1138 CldrYrCmpstdVal 1;
BA_ "GenSigSendType" SG_ 1138 CldrYrCmpstdVal 1;
BA_ "SignalLongName" SG_ 1138 HrsCmpstdVal "Hours Compensated Value";
BA_ "SignalType" SG_ 1138 HrsCmpstdVal "UNM";
BA_ "GenSigDeltaValue" SG_ 1138 HrsCmpstdVal 1;
BA_ "GenSigSendType" SG_ 1138 HrsCmpstdVal 1;
BA_ "SignalLongName" SG_ 1138 MinsCmpstdVal "Minutes Compensated Value";
BA_ "SignalType" SG_ 1138 MinsCmpstdVal "UNM";
BA_ "GenSigDeltaValue" SG_ 1138 MinsCmpstdVal 1;
BA_ "GenSigSendType" SG_ 1138 MinsCmpstdVal 1;
BA_ "SignalLongName" SG_ 1138 SecCmpstdVal "Seconds Compensated Value";
BA_ "SignalType" SG_ 1138 SecCmpstdVal "UNM";
BA_ "GenSigDeltaValue" SG_ 1138 SecCmpstdVal 1;
BA_ "GenSigSendType" SG_ 1138 SecCmpstdVal 1;
BA_ "SignalLongName" SG_ 1136 CldrYr "Calendar Year";
BA_ "SignalType" SG_ 1136 CldrYr "UNM";
BA_ "GenSigDeltaValue" SG_ 1136 CldrYr 1;
BA_ "GenSigSendType" SG_ 1136 CldrYr 1;
BA_ "GenSigSendOnInit" SG_ 1136 CldrYr 1;
BA_ "SignalLongName" SG_ 1136 FrPedDetCsStReq "Front Pedestrian Detection Customization Setting Request";
BA_ "SignalType" SG_ 1136 FrPedDetCsStReq "ENM";
BA_ "GenSigSendType" SG_ 1136 FrPedDetCsStReq 1;
BA_ "SignalLongName" SG_ 1136 CldrMth "Calendar Month";
BA_ "SignalType" SG_ 1136 CldrMth "ENM";
BA_ "GenSigSendType" SG_ 1136 CldrMth 1;
BA_ "GenSigSendOnInit" SG_ 1136 CldrMth 1;
BA_ "SignalLongName" SG_ 1136 CldrDay "Calendar Day";
BA_ "SignalType" SG_ 1136 CldrDay "UNM";
BA_ "GenSigDeltaValue" SG_ 1136 CldrDay 1;
BA_ "GenSigSendType" SG_ 1136 CldrDay 1;
BA_ "GenSigSendOnInit" SG_ 1136 CldrDay 1;
BA_ "SignalLongName" SG_ 1136 TimeDispFormat "Time Display Format";
BA_ "SignalType" SG_ 1136 TimeDispFormat "ENM";
BA_ "GenSigSendType" SG_ 1136 TimeDispFormat 1;
BA_ "GenSigSendOnInit" SG_ 1136 TimeDispFormat 1;
BA_ "SignalLongName" SG_ 1136 TOD_HrofDay "Time of Day : Hour of Day";
BA_ "SignalType" SG_ 1136 TOD_HrofDay "UNM";
BA_ "GenSigDeltaValue" SG_ 1136 TOD_HrofDay 1;
BA_ "GenSigSendType" SG_ 1136 TOD_HrofDay 1;
BA_ "SignalLongName" SG_ 1136 TOD_MinofHr "Time of Day : Minute of Hour";
BA_ "SignalType" SG_ 1136 TOD_MinofHr "UNM";
BA_ "GenSigDeltaValue" SG_ 1136 TOD_MinofHr 1;
BA_ "GenSigSendType" SG_ 1136 TOD_MinofHr 1;
BA_ "SignalLongName" SG_ 1136 TOD_SecofMin "Time of Day : Seconds of Minute";
BA_ "SignalType" SG_ 1136 TOD_SecofMin "UNM";
BA_ "GenSigDeltaValue" SG_ 1136 TOD_SecofMin 1;
BA_ "GenSigSendType" SG_ 1136 TOD_SecofMin 1;
BA_ "SignalLongName" SG_ 2430336753 DgnInf "Diagnostic Information";
BA_ "SignalType" SG_ 2430336753 DgnInf "UNM";
BA_ "SignalLongName" SG_ 2430336755 DgnInf "Diagnostic Information";
BA_ "SignalType" SG_ 2430336755 DgnInf "UNM";
BA_ "SignalLongName" SG_ 2497376665 DgnInf "Diagnostic Information";
BA_ "SignalType" SG_ 2497376665 DgnInf "UNM";
BA_ "SignalLongName" SG_ 2497507737 DgnInf "Diagnostic Information";
BA_ "SignalType" SG_ 2497507737 DgnInf "UNM";
BA_ "SignalLongName" SG_ 2497377177 DgnInf "Diagnostic Information";
BA_ "SignalType" SG_ 2497377177 DgnInf "UNM";
BA_ "SignalLongName" SG_ 2497508249 DgnInf "Diagnostic Information";
BA_ "SignalType" SG_ 2497508249 DgnInf "UNM";
BA_ "SignalLongName" SG_ 2497354225 DgnInf "Diagnostic Information";
BA_ "SignalType" SG_ 2497354225 DgnInf "UNM";
BA_ "SignalLongName" SG_ 2497354227 DgnInf "Diagnostic Information";
BA_ "SignalType" SG_ 2497354227 DgnInf "UNM";
BA_ "SignalLongName" SG_ 1088 ReIniReq_BCM "Re Initialization Request BCM";
BA_ "SignalType" SG_ 1088 ReIniReq_BCM "BLN";
BA_ "GenSigSendType" SG_ 1088 ReIniReq_BCM 1;
BA_ "SignalLongName" SG_ 1089 ReIniReq_IPC "Re Initialization Request IPC";
BA_ "SignalType" SG_ 1089 ReIniReq_IPC "BLN";
BA_ "GenSigSendType" SG_ 1089 ReIniReq_IPC 1;
BA_ "SignalLongName" SG_ 1122 ReIniReq_APA "Re Initialization Request APA";
BA_ "SignalType" SG_ 1122 ReIniReq_APA "BLN";
BA_ "GenSigSendType" SG_ 1122 ReIniReq_APA 1;
BA_ "SignalLongName" SG_ 1091 ReIniReq_ECC "Re Initialization Request ECC";
BA_ "SignalType" SG_ 1091 ReIniReq_ECC "BLN";
BA_ "GenSigSendType" SG_ 1091 ReIniReq_ECC 1;
BA_ "SignalLongName" SG_ 1093 ReIniReq_ESCL "Re Initialization Request ESCL";
BA_ "SignalType" SG_ 1093 ReIniReq_ESCL "BLN";
BA_ "GenSigSendType" SG_ 1093 ReIniReq_ESCL 1;
BA_ "SignalLongName" SG_ 1094 ReIniReq_FCM "Re Initialization Request FCM";
BA_ "SignalType" SG_ 1094 ReIniReq_FCM "BLN";
BA_ "GenSigSendType" SG_ 1094 ReIniReq_FCM 1;
BA_ "SignalLongName" SG_ 1095 ReIniReq_ONSTAR "Re Initialization Request ONSTAR";
BA_ "SignalType" SG_ 1095 ReIniReq_ONSTAR "BLN";
BA_ "GenSigSendType" SG_ 1095 ReIniReq_ONSTAR 1;
BA_ "SignalLongName" SG_ 1096 ReIniReq_RadioHead "Re Initialization Request RadioHead";
BA_ "SignalType" SG_ 1096 ReIniReq_RadioHead "BLN";
BA_ "GenSigSendType" SG_ 1096 ReIniReq_RadioHead 1;
BA_ "SignalLongName" SG_ 1097 ReIniReq_SDM "Re Initialization Request SDM";
BA_ "SignalType" SG_ 1097 ReIniReq_SDM "BLN";
BA_ "GenSigSendType" SG_ 1097 ReIniReq_SDM 1;
BA_ "SignalLongName" SG_ 502 PPEIPltGenStMAC "PPEI Platform General Status MAC";
BA_ "SignalType" SG_ 502 PPEIPltGenStMAC "UNM";
BA_ "SignalLongName" SG_ 502 PPEIPltGenStAntiRplyCnt "PPEI Platform General Status Anti Replay Counter";
BA_ "SignalType" SG_ 502 PPEIPltGenStAntiRplyCnt "UNM";
BA_ "SignalLongName" SG_ 502 PPEIPltGenStARC "PPEI Platform General Status Alive Rolling Counter";
BA_ "SignalType" SG_ 502 PPEIPltGenStARC "UNM";
BA_ "SignalLongName" SG_ 502 SysPwrMdMac "System Power Mode";
BA_ "SignalType" SG_ 502 SysPwrMdMac "ENM";
BA_ "GenSigSendType" SG_ 502 SysPwrMdMac 1;
BA_ "SignalLongName" SG_ 502 SysPwrMdVMac "System Power Mode Validity";
BA_ "SignalType" SG_ 502 SysPwrMdVMac "ENM";
BA_ "GenSigSendType" SG_ 502 SysPwrMdVMac 1;
BA_ "GenSigSendOnInit" SG_ 502 SysPwrMdVMac 1;
BA_ "SignalLongName" SG_ 502 ImmblzrPreRelPswrdMac "Immobilizer Pre Release Password";
BA_ "SignalType" SG_ 502 ImmblzrPreRelPswrdMac "UNM";
BA_ "GenSigDeltaValue" SG_ 502 ImmblzrPreRelPswrdMac 1;
BA_ "GenSigSendType" SG_ 502 ImmblzrPreRelPswrdMac 1;
BA_ "SignalLongName" SG_ 502 ImmblzrPreRelPswdStatMac "Immobilizer Pre Release Password Status";
BA_ "SignalType" SG_ 502 ImmblzrPreRelPswdStatMac "ENM";
BA_ "GenSigSendType" SG_ 502 ImmblzrPreRelPswdStatMac 1;
BA_ "SignalLongName" SG_ 502 PMMAccTrmStMac "Power Mode Master Accessory Terminal Status";
BA_ "SignalType" SG_ 502 PMMAccTrmStMac "ENM";
BA_ "GenSigSendType" SG_ 502 PMMAccTrmStMac 1;
BA_ "SignalLongName" SG_ 502 PMMRunCrkTrmStMac "Power Mode Master Run Crank Terminal Status";
BA_ "SignalType" SG_ 502 PMMRunCrkTrmStMac "ENM";
BA_ "GenSigSendType" SG_ 502 PMMRunCrkTrmStMac 1;
BA_ "SignalLongName" SG_ 502 RemStrtStMac "Remote Start Status";
BA_ "SignalType" SG_ 502 RemStrtStMac "ENM";
BA_ "GenSigSendType" SG_ 502 RemStrtStMac 1;
BA_ "GenSigSendOnInit" SG_ 502 RemStrtStMac 1;
BA_ "SignalLongName" SG_ 502 RmVehStrRqMac "Remote Vehicle Start Request";
BA_ "SignalType" SG_ 502 RmVehStrRqMac "ENM";
BA_ "GenSigSendType" SG_ 502 RmVehStrRqMac 1;
BA_ "SignalLongName" SG_ 291 SysPwMdBkUpIPCMAC "System Power Mode Backup IPC MAC";
BA_ "SignalType" SG_ 291 SysPwMdBkUpIPCMAC "UNM";
BA_ "SignalLongName" SG_ 291 SysPwMdBkUpIPCAntiRplyCnt "System Power Mode Backup IPC Anti Replay Counter";
BA_ "SignalType" SG_ 291 SysPwMdBkUpIPCAntiRplyCnt "UNM";
BA_ "SignalLongName" SG_ 291 SysPwMdBkUpIPCARC "System Power Mode Backup IPC Alive Rolling Counter";
BA_ "SignalType" SG_ 291 SysPwMdBkUpIPCARC "UNM";
BA_ "SignalLongName" SG_ 291 SysBkUpPwrMdMac "System Backup Power Mode";
BA_ "SignalType" SG_ 291 SysBkUpPwrMdMac "ENM";
BA_ "GenSigSendType" SG_ 291 SysBkUpPwrMdMac 1;
BA_ "GenSigSendOnInit" SG_ 291 SysBkUpPwrMdMac 1;
BA_ "SignalLongName" SG_ 291 SysBkupPwrMdEnMac "System Backup Power Mode Enabled";
BA_ "SignalType" SG_ 291 SysBkupPwrMdEnMac "BLN";
BA_ "GenSigSendType" SG_ 291 SysBkupPwrMdEnMac 1;
BA_ "GenSigSendOnInit" SG_ 291 SysBkupPwrMdEnMac 1;
BA_ "SignalLongName" SG_ 291 SysBkUpPwrMdVMac "System Backup Power Mode Validity";
BA_ "SignalType" SG_ 291 SysBkUpPwrMdVMac "ENM";
BA_ "GenSigSendType" SG_ 291 SysBkUpPwrMdVMac 1;
BA_ "SignalLongName" SG_ 291 BkUpPwrMdRnCrnkOutSt "Backup Power Mode RUN Crank Output State";
BA_ "SignalType" SG_ 291 BkUpPwrMdRnCrnkOutSt "ENM";
BA_ "GenSigSendType" SG_ 291 BkUpPwrMdRnCrnkOutSt 1;
BA_ "SignalLongName" SG_ 291 ElecPwrStrSlctdMdMac "Electrical Power Steering Selected Mode";
BA_ "SignalType" SG_ 291 ElecPwrStrSlctdMdMac "ENM";
BA_ "SignalLongName" SG_ 1003 PPEIVehSpdaDisMAC1 "PPEI Vehicle Speed and Distance MAC1";
BA_ "SignalType" SG_ 1003 PPEIVehSpdaDisMAC1 "UNM";
BA_ "SignalLongName" SG_ 1003 PPEIVehSpdaDisAntiRplyCnt1 "PPEI Vehicle Speed and Distance Anti Replay Counter1";
BA_ "SignalType" SG_ 1003 PPEIVehSpdaDisAntiRplyCnt1 "UNM";
BA_ "SignalLongName" SG_ 1003 PPEIVehSpdaDisARC1 "PPEI Vehicle Speed and Distance Alive Rolling Counter1";
BA_ "SignalType" SG_ 1003 PPEIVehSpdaDisARC1 "UNM";
BA_ "SignalLongName" SG_ 1003 VehSpdAvgDrvnSrcMac "Vehicle Speed Average Driven Source";
BA_ "SignalType" SG_ 1003 VehSpdAvgDrvnSrcMac "ENM";
BA_ "SignalLongName" SG_ 1003 VehSpdAvgDrvnVMac "Vehicle Speed Average Driven Validity";
BA_ "SignalType" SG_ 1003 VehSpdAvgDrvnVMac "ENM";
BA_ "SignalLongName" SG_ 1003 VehSpdAvgDrvnMac "Vehicle Speed Average Driven";
BA_ "SignalType" SG_ 1003 VehSpdAvgDrvnMac "UNM";
BA_ "SignalLongName" SG_ 203 PPEIEngGenSt1MAC "PPEI Engine General Status 1 MAC";
BA_ "SignalType" SG_ 203 PPEIEngGenSt1MAC "UNM";
BA_ "SignalLongName" SG_ 203 PPEIEngGenSt1AntiRplyCnt "PPEI Engine General Status 1 Anti Replay Counter";
BA_ "SignalType" SG_ 203 PPEIEngGenSt1AntiRplyCnt "UNM";
BA_ "SignalLongName" SG_ 203 PPEIEngGenSt1ARC "PPEI Engine General Status 1 Alive Rolling Counter";
BA_ "SignalType" SG_ 203 PPEIEngGenSt1ARC "UNM";
BA_ "SignalLongName" SG_ 203 AccActPosMac "Accelerator Actual Position";
BA_ "SignalType" SG_ 203 AccActPosMac "UNM";
BA_ "SignalLongName" SG_ 203 AccActPosVMac "Accelerator Actual Position Validity";
BA_ "SignalType" SG_ 203 AccActPosVMac "ENM";
BA_ "SignalLongName" SG_ 203 EngSpdMac "Engine Speed";
BA_ "SignalType" SG_ 203 EngSpdMac "UNM";
BA_ "SignalLongName" SG_ 203 EngSpdStatMac "Engine Speed Status";
BA_ "SignalType" SG_ 203 EngSpdStatMac "ENM";
BA_ "SignalLongName" SG_ 203 PT_CrnkActMac "Powertrain Crank Active";
BA_ "SignalType" SG_ 203 PT_CrnkActMac "BLN";
BA_ "SignalLongName" SG_ 1630 AirQltySnsCstCrStVal "Air Quality Sensor Customization Current Setting Value";
BA_ "SignalType" SG_ 1630 AirQltySnsCstCrStVal "ENM";
BA_ "GenSigSendType" SG_ 1630 AirQltySnsCstCrStVal 1;
BA_ "SignalLongName" SG_ 1630 AirQltySnsCstStAvl "Air Quality Sensor Customization Setting Available";
BA_ "SignalType" SG_ 1630 AirQltySnsCstStAvl "BLN";
BA_ "GenSigSendType" SG_ 1630 AirQltySnsCstStAvl 1;
BA_ "SignalLongName" SG_ 1630 AirQltySnsCstAvlFlg1 "Air Quality Sensor Customization Availability Flag 1";
BA_ "SignalType" SG_ 1630 AirQltySnsCstAvlFlg1 "BLN";
BA_ "GenSigSendType" SG_ 1630 AirQltySnsCstAvlFlg1 1;
BA_ "SignalLongName" SG_ 1630 AirQltySnsCstAvlFlg2 "Air Quality Sensor Customization Availability Flag 2";
BA_ "SignalType" SG_ 1630 AirQltySnsCstAvlFlg2 "BLN";
BA_ "GenSigSendType" SG_ 1630 AirQltySnsCstAvlFlg2 1;
BA_ "SignalLongName" SG_ 1630 AirQltySnsCstAvlFlg3 "Air Quality Sensor Customization Availability Flag 3";
BA_ "SignalType" SG_ 1630 AirQltySnsCstAvlFlg3 "BLN";
BA_ "GenSigSendType" SG_ 1630 AirQltySnsCstAvlFlg3 1;
BA_ "SignalLongName" SG_ 1630 AirQltySnsCstAvlFlg4 "Air Quality Sensor Customization Availability Flag 4";
BA_ "SignalType" SG_ 1630 AirQltySnsCstAvlFlg4 "BLN";
BA_ "GenSigSendType" SG_ 1630 AirQltySnsCstAvlFlg4 1;
BA_ "SignalLongName" SG_ 1630 AirQltySnsCstAvlFlg5 "Air Quality Sensor Customization Availability Flag 5";
BA_ "SignalType" SG_ 1630 AirQltySnsCstAvlFlg5 "BLN";
BA_ "GenSigSendType" SG_ 1630 AirQltySnsCstAvlFlg5 1;
BA_ "SignalLongName" SG_ 1630 AirQltySnsCstAvlFlg6 "Air Quality Sensor Customization Availability Flag 6";
BA_ "SignalType" SG_ 1630 AirQltySnsCstAvlFlg6 "BLN";
BA_ "GenSigSendType" SG_ 1630 AirQltySnsCstAvlFlg6 1;
BA_ "SignalLongName" SG_ 1630 AirQltySnsCstAvlFlg7 "Air Quality Sensor Customization Availability Flag 7";
BA_ "SignalType" SG_ 1630 AirQltySnsCstAvlFlg7 "BLN";
BA_ "GenSigSendType" SG_ 1630 AirQltySnsCstAvlFlg7 1;
BA_ "SignalLongName" SG_ 1630 IonzrCtrlCstCrStVal "Ionizer Control Customization Current Setting Value";
BA_ "SignalType" SG_ 1630 IonzrCtrlCstCrStVal "ENM";
BA_ "GenSigSendType" SG_ 1630 IonzrCtrlCstCrStVal 1;
BA_ "SignalLongName" SG_ 1630 IonzrCtrlCstStAvl "Ionizer Control Customization Setting Available";
BA_ "SignalType" SG_ 1630 IonzrCtrlCstStAvl "BLN";
BA_ "GenSigSendType" SG_ 1630 IonzrCtrlCstStAvl 1;
BA_ "SignalLongName" SG_ 1630 IonzrCtrlCstAvlFlg1 "Ionizer Control Customization Availability Flag 1";
BA_ "SignalType" SG_ 1630 IonzrCtrlCstAvlFlg1 "BLN";
BA_ "GenSigSendType" SG_ 1630 IonzrCtrlCstAvlFlg1 1;
BA_ "SignalLongName" SG_ 1630 IonzrCtrlCstAvlFlg2 "Ionizer Control Customization Availability Flag 2";
BA_ "SignalType" SG_ 1630 IonzrCtrlCstAvlFlg2 "BLN";
BA_ "GenSigSendType" SG_ 1630 IonzrCtrlCstAvlFlg2 1;
BA_ "SignalLongName" SG_ 1630 IonzrCtrlCstAvlFlg3 "Ionizer Control Customization Availability Flag 3";
BA_ "SignalType" SG_ 1630 IonzrCtrlCstAvlFlg3 "BLN";
BA_ "GenSigSendType" SG_ 1630 IonzrCtrlCstAvlFlg3 1;
BA_ "SignalLongName" SG_ 1630 IonzrCtrlCstAvlFlg4 "Ionizer Control Customization Availability Flag 4";
BA_ "SignalType" SG_ 1630 IonzrCtrlCstAvlFlg4 "BLN";
BA_ "GenSigSendType" SG_ 1630 IonzrCtrlCstAvlFlg4 1;
BA_ "SignalLongName" SG_ 1630 IonzrCtrlCstAvlFlg5 "Ionizer Control Customization Availability Flag 5";
BA_ "SignalType" SG_ 1630 IonzrCtrlCstAvlFlg5 "BLN";
BA_ "GenSigSendType" SG_ 1630 IonzrCtrlCstAvlFlg5 1;
BA_ "SignalLongName" SG_ 1630 IonzrCtrlCstAvlFlg6 "Ionizer Control Customization Availability Flag 6";
BA_ "SignalType" SG_ 1630 IonzrCtrlCstAvlFlg6 "BLN";
BA_ "GenSigSendType" SG_ 1630 IonzrCtrlCstAvlFlg6 1;
BA_ "SignalLongName" SG_ 1630 IonzrCtrlCstAvlFlg7 "Ionizer Control Customization Availability Flag 7";
BA_ "SignalType" SG_ 1630 IonzrCtrlCstAvlFlg7 "BLN";
BA_ "GenSigSendType" SG_ 1630 IonzrCtrlCstAvlFlg7 1;
BA_ "SignalLongName" SG_ 1630 AutoDfgCstCrStVal "Automatic Defog Customization Current Setting Value";
BA_ "SignalType" SG_ 1630 AutoDfgCstCrStVal "ENM";
BA_ "GenSigSendType" SG_ 1630 AutoDfgCstCrStVal 1;
BA_ "SignalLongName" SG_ 1630 AutoDfgCstStAvl "Automatic Defog Customization Setting Available";
BA_ "SignalType" SG_ 1630 AutoDfgCstStAvl "BLN";
BA_ "GenSigSendType" SG_ 1630 AutoDfgCstStAvl 1;
BA_ "SignalLongName" SG_ 1630 AutoDfgCstAvlFlg1 "Automatic Defog Customization Availability Flag 1";
BA_ "SignalType" SG_ 1630 AutoDfgCstAvlFlg1 "BLN";
BA_ "GenSigSendType" SG_ 1630 AutoDfgCstAvlFlg1 1;
BA_ "SignalLongName" SG_ 1630 AutoDfgCstAvlFlg2 "Automatic Defog Customization Availability Flag 2";
BA_ "SignalType" SG_ 1630 AutoDfgCstAvlFlg2 "BLN";
BA_ "GenSigSendType" SG_ 1630 AutoDfgCstAvlFlg2 1;
BA_ "SignalLongName" SG_ 1630 AutoDfgCstAvlFlg3 "Automatic Defog Customization Availability Flag 3";
BA_ "SignalType" SG_ 1630 AutoDfgCstAvlFlg3 "BLN";
BA_ "GenSigSendType" SG_ 1630 AutoDfgCstAvlFlg3 1;
BA_ "SignalLongName" SG_ 1630 AutoDfgCstAvlFlg4 "Automatic Defog Customization Availability Flag 4";
BA_ "SignalType" SG_ 1630 AutoDfgCstAvlFlg4 "BLN";
BA_ "GenSigSendType" SG_ 1630 AutoDfgCstAvlFlg4 1;
BA_ "SignalLongName" SG_ 1630 AutoDfgCstAvlFlg5 "Automatic Defog Customization Availability Flag 5";
BA_ "SignalType" SG_ 1630 AutoDfgCstAvlFlg5 "BLN";
BA_ "GenSigSendType" SG_ 1630 AutoDfgCstAvlFlg5 1;
BA_ "SignalLongName" SG_ 1630 AutoDfgCstAvlFlg6 "Automatic Defog Customization Availability Flag 6";
BA_ "SignalType" SG_ 1630 AutoDfgCstAvlFlg6 "BLN";
BA_ "GenSigSendType" SG_ 1630 AutoDfgCstAvlFlg6 1;
BA_ "SignalLongName" SG_ 1630 AutoDfgCstAvlFlg7 "Automatic Defog Customization Availability Flag 7";
BA_ "SignalType" SG_ 1630 AutoDfgCstAvlFlg7 "BLN";
BA_ "GenSigSendType" SG_ 1630 AutoDfgCstAvlFlg7 1;
BA_ "SignalLongName" SG_ 1630 AutoFanCstCrStVal "Automatic Fan Customization Current Setting Value";
BA_ "SignalType" SG_ 1630 AutoFanCstCrStVal "ENM";
BA_ "GenSigSendType" SG_ 1630 AutoFanCstCrStVal 1;
BA_ "SignalLongName" SG_ 1630 AutoFanCstStAvl "Automatic Fan Customization Setting Available";
BA_ "SignalType" SG_ 1630 AutoFanCstStAvl "BLN";
BA_ "GenSigSendType" SG_ 1630 AutoFanCstStAvl 1;
BA_ "SignalLongName" SG_ 1630 AutoFanCstAvlFlg1 "Automatic Fan Customization Availability Flag 1";
BA_ "SignalType" SG_ 1630 AutoFanCstAvlFlg1 "BLN";
BA_ "GenSigSendType" SG_ 1630 AutoFanCstAvlFlg1 1;
BA_ "SignalLongName" SG_ 1630 AutoFanCstAvlFlg2 "Automatic Fan Customization Availability Flag 2";
BA_ "SignalType" SG_ 1630 AutoFanCstAvlFlg2 "BLN";
BA_ "GenSigSendType" SG_ 1630 AutoFanCstAvlFlg2 1;
BA_ "SignalLongName" SG_ 1630 AutoFanCstAvlFlg3 "Automatic Fan Customization Availability Flag 3";
BA_ "SignalType" SG_ 1630 AutoFanCstAvlFlg3 "BLN";
BA_ "GenSigSendType" SG_ 1630 AutoFanCstAvlFlg3 1;
BA_ "SignalLongName" SG_ 1630 AutoFanCstAvlFlg4 "Automatic Fan Customization Availability Flag 4";
BA_ "SignalType" SG_ 1630 AutoFanCstAvlFlg4 "BLN";
BA_ "GenSigSendType" SG_ 1630 AutoFanCstAvlFlg4 1;
BA_ "SignalLongName" SG_ 1630 AutoFanCstAvlFlg5 "Automatic Fan Customization Availability Flag 5";
BA_ "SignalType" SG_ 1630 AutoFanCstAvlFlg5 "BLN";
BA_ "GenSigSendType" SG_ 1630 AutoFanCstAvlFlg5 1;
BA_ "SignalLongName" SG_ 1630 AutoFanCstAvlFlg6 "Automatic Fan Customization Availability Flag 6";
BA_ "SignalType" SG_ 1630 AutoFanCstAvlFlg6 "BLN";
BA_ "GenSigSendType" SG_ 1630 AutoFanCstAvlFlg6 1;
BA_ "SignalLongName" SG_ 1630 AutoFanCstAvlFlg7 "Automatic Fan Customization Availability Flag 7";
BA_ "SignalType" SG_ 1630 AutoFanCstAvlFlg7 "BLN";
BA_ "GenSigSendType" SG_ 1630 AutoFanCstAvlFlg7 1;
BA_ "SignalLongName" SG_ 1638 RrDfgStUpCstCrStVal "Rear Defog Startup Customization Current Setting Value";
BA_ "SignalType" SG_ 1638 RrDfgStUpCstCrStVal "ENM";
BA_ "GenSigSendType" SG_ 1638 RrDfgStUpCstCrStVal 1;
BA_ "SignalLongName" SG_ 1638 RrDfgStUpCstStAvl "Rear Defog Startup Customization Setting Available";
BA_ "SignalType" SG_ 1638 RrDfgStUpCstStAvl "BLN";
BA_ "GenSigSendType" SG_ 1638 RrDfgStUpCstStAvl 1;
BA_ "SignalLongName" SG_ 1638 RrDfgStUpCstAvlFlg1 "Rear Defog Startup Customization Availability Flag 1";
BA_ "SignalType" SG_ 1638 RrDfgStUpCstAvlFlg1 "BLN";
BA_ "GenSigSendType" SG_ 1638 RrDfgStUpCstAvlFlg1 1;
BA_ "SignalLongName" SG_ 1638 RrDfgStUpCstAvlFlg2 "Rear Defog Startup Customization Availability Flag 2";
BA_ "SignalType" SG_ 1638 RrDfgStUpCstAvlFlg2 "BLN";
BA_ "GenSigSendType" SG_ 1638 RrDfgStUpCstAvlFlg2 1;
BA_ "SignalLongName" SG_ 1638 RrDfgStUpCstAvlFlg3 "Rear Defog Startup Customization Availability Flag 3";
BA_ "SignalType" SG_ 1638 RrDfgStUpCstAvlFlg3 "BLN";
BA_ "GenSigSendType" SG_ 1638 RrDfgStUpCstAvlFlg3 1;
BA_ "SignalLongName" SG_ 1638 RrDfgStUpCstAvlFlg4 "Rear Defog Startup Customization Availability Flag 4";
BA_ "SignalType" SG_ 1638 RrDfgStUpCstAvlFlg4 "BLN";
BA_ "GenSigSendType" SG_ 1638 RrDfgStUpCstAvlFlg4 1;
BA_ "SignalLongName" SG_ 1638 RrDfgStUpCstAvlFlg5 "Rear Defog Startup Customization Availability Flag 5";
BA_ "SignalType" SG_ 1638 RrDfgStUpCstAvlFlg5 "BLN";
BA_ "GenSigSendType" SG_ 1638 RrDfgStUpCstAvlFlg5 1;
BA_ "SignalLongName" SG_ 1638 RrDfgStUpCstAvlFlg6 "Rear Defog Startup Customization Availability Flag 6";
BA_ "SignalType" SG_ 1638 RrDfgStUpCstAvlFlg6 "BLN";
BA_ "GenSigSendType" SG_ 1638 RrDfgStUpCstAvlFlg6 1;
BA_ "SignalLongName" SG_ 1638 RrDfgStUpCstAvlFlg7 "Rear Defog Startup Customization Availability Flag 7";
BA_ "SignalType" SG_ 1638 RrDfgStUpCstAvlFlg7 "BLN";
BA_ "GenSigSendType" SG_ 1638 RrDfgStUpCstAvlFlg7 1;
BA_ "SignalLongName" SG_ 1638 RrZnStUpCstCrStVal "Rear Zone Startup Customization Current Setting Value";
BA_ "SignalType" SG_ 1638 RrZnStUpCstCrStVal "ENM";
BA_ "GenSigSendType" SG_ 1638 RrZnStUpCstCrStVal 1;
BA_ "SignalLongName" SG_ 1638 RrZnStUpCstStAvl "Rear Zone Startup Customization Setting Available";
BA_ "SignalType" SG_ 1638 RrZnStUpCstStAvl "BLN";
BA_ "GenSigSendType" SG_ 1638 RrZnStUpCstStAvl 1;
BA_ "SignalLongName" SG_ 1638 RrZnStUpCstAvlFlg1 "Rear Zone Startup Customization Availability Flag 1";
BA_ "SignalType" SG_ 1638 RrZnStUpCstAvlFlg1 "BLN";
BA_ "GenSigSendType" SG_ 1638 RrZnStUpCstAvlFlg1 1;
BA_ "SignalLongName" SG_ 1638 RrZnStUpCstAvlFlg2 "Rear Zone Startup Customization Availability Flag 2";
BA_ "SignalType" SG_ 1638 RrZnStUpCstAvlFlg2 "BLN";
BA_ "GenSigSendType" SG_ 1638 RrZnStUpCstAvlFlg2 1;
BA_ "SignalLongName" SG_ 1638 RrZnStUpCstAvlFlg3 "Rear Zone Startup Customization Availability Flag 3";
BA_ "SignalType" SG_ 1638 RrZnStUpCstAvlFlg3 "BLN";
BA_ "GenSigSendType" SG_ 1638 RrZnStUpCstAvlFlg3 1;
BA_ "SignalLongName" SG_ 1638 RrZnStUpCstAvlFlg4 "Rear Zone Startup Customization Availability Flag 4";
BA_ "SignalType" SG_ 1638 RrZnStUpCstAvlFlg4 "BLN";
BA_ "GenSigSendType" SG_ 1638 RrZnStUpCstAvlFlg4 1;
BA_ "SignalLongName" SG_ 1638 RrZnStUpCstAvlFlg5 "Rear Zone Startup Customization Availability Flag 5";
BA_ "SignalType" SG_ 1638 RrZnStUpCstAvlFlg5 "BLN";
BA_ "GenSigSendType" SG_ 1638 RrZnStUpCstAvlFlg5 1;
BA_ "SignalLongName" SG_ 1638 RrZnStUpCstAvlFlg6 "Rear Zone Startup Customization Availability Flag 6";
BA_ "SignalType" SG_ 1638 RrZnStUpCstAvlFlg6 "BLN";
BA_ "GenSigSendType" SG_ 1638 RrZnStUpCstAvlFlg6 1;
BA_ "SignalLongName" SG_ 1638 RrZnStUpCstAvlFlg7 "Rear Zone Startup Customization Availability Flag 7";
BA_ "SignalType" SG_ 1638 RrZnStUpCstAvlFlg7 "BLN";
BA_ "GenSigSendType" SG_ 1638 RrZnStUpCstAvlFlg7 1;
BA_ "SignalLongName" SG_ 1638 AutoCoolStCstCrStVal "Automatic Cooled Seat Customization Current Setting Value";
BA_ "SignalType" SG_ 1638 AutoCoolStCstCrStVal "ENM";
BA_ "GenSigSendType" SG_ 1638 AutoCoolStCstCrStVal 1;
BA_ "SignalLongName" SG_ 1638 AutoCoolStCstStAvl "Automatic Cooled Seat Customization Setting Available";
BA_ "SignalType" SG_ 1638 AutoCoolStCstStAvl "BLN";
BA_ "GenSigSendType" SG_ 1638 AutoCoolStCstStAvl 1;
BA_ "SignalLongName" SG_ 1638 AutoCoolStCstAvlFlg1 "Automatic Cooled Seat Customization Availability Flag 1";
BA_ "SignalType" SG_ 1638 AutoCoolStCstAvlFlg1 "BLN";
BA_ "GenSigSendType" SG_ 1638 AutoCoolStCstAvlFlg1 1;
BA_ "SignalLongName" SG_ 1638 AutoCoolStCstAvlFlg2 "Automatic Cooled Seat Customization Availability Flag 2";
BA_ "SignalType" SG_ 1638 AutoCoolStCstAvlFlg2 "BLN";
BA_ "GenSigSendType" SG_ 1638 AutoCoolStCstAvlFlg2 1;
BA_ "SignalLongName" SG_ 1638 AutoCoolStCstAvlFlg3 "Automatic Cooled Seat Customization Availability Flag 3";
BA_ "SignalType" SG_ 1638 AutoCoolStCstAvlFlg3 "BLN";
BA_ "GenSigSendType" SG_ 1638 AutoCoolStCstAvlFlg3 1;
BA_ "SignalLongName" SG_ 1638 AutoCoolStCstAvlFlg4 "Automatic Cooled Seat Customization Availability Flag 4";
BA_ "SignalType" SG_ 1638 AutoCoolStCstAvlFlg4 "BLN";
BA_ "GenSigSendType" SG_ 1638 AutoCoolStCstAvlFlg4 1;
BA_ "SignalLongName" SG_ 1638 AutoCoolStCstAvlFlg5 "Automatic Cooled Seat Customization Availability Flag 5";
BA_ "SignalType" SG_ 1638 AutoCoolStCstAvlFlg5 "BLN";
BA_ "GenSigSendType" SG_ 1638 AutoCoolStCstAvlFlg5 1;
BA_ "SignalLongName" SG_ 1638 AutoCoolStCstAvlFlg6 "Automatic Cooled Seat Customization Availability Flag 6";
BA_ "SignalType" SG_ 1638 AutoCoolStCstAvlFlg6 "BLN";
BA_ "GenSigSendType" SG_ 1638 AutoCoolStCstAvlFlg6 1;
BA_ "SignalLongName" SG_ 1638 AutoCoolStCstAvlFlg7 "Automatic Cooled Seat Customization Availability Flag 7";
BA_ "SignalType" SG_ 1638 AutoCoolStCstAvlFlg7 "BLN";
BA_ "GenSigSendType" SG_ 1638 AutoCoolStCstAvlFlg7 1;
BA_ "SignalLongName" SG_ 1638 AutoHtdStCstCrStVal "Automatic Heated Seat Customization Current Setting Value";
BA_ "SignalType" SG_ 1638 AutoHtdStCstCrStVal "ENM";
BA_ "GenSigSendType" SG_ 1638 AutoHtdStCstCrStVal 1;
BA_ "SignalLongName" SG_ 1638 AutoHtdStCstStAvl "Automatic Heated Seat Customization Setting Available";
BA_ "SignalType" SG_ 1638 AutoHtdStCstStAvl "BLN";
BA_ "GenSigSendType" SG_ 1638 AutoHtdStCstStAvl 1;
BA_ "SignalLongName" SG_ 1638 AutoHtdStCstAvlFlg1 "Automatic Heated Seat Customization Availability Flag 1";
BA_ "SignalType" SG_ 1638 AutoHtdStCstAvlFlg1 "BLN";
BA_ "GenSigSendType" SG_ 1638 AutoHtdStCstAvlFlg1 1;
BA_ "SignalLongName" SG_ 1638 AutoHtdStCstAvlFlg2 "Automatic Heated Seat Customization Availability Flag 2";
BA_ "SignalType" SG_ 1638 AutoHtdStCstAvlFlg2 "BLN";
BA_ "GenSigSendType" SG_ 1638 AutoHtdStCstAvlFlg2 1;
BA_ "SignalLongName" SG_ 1638 AutoHtdStCstAvlFlg3 "Automatic Heated Seat Customization Availability Flag 3";
BA_ "SignalType" SG_ 1638 AutoHtdStCstAvlFlg3 "BLN";
BA_ "GenSigSendType" SG_ 1638 AutoHtdStCstAvlFlg3 1;
BA_ "SignalLongName" SG_ 1638 AutoHtdStCstAvlFlg4 "Automatic Heated Seat Customization Availability Flag 4";
BA_ "SignalType" SG_ 1638 AutoHtdStCstAvlFlg4 "BLN";
BA_ "GenSigSendType" SG_ 1638 AutoHtdStCstAvlFlg4 1;
BA_ "SignalLongName" SG_ 1638 AutoHtdStCstAvlFlg5 "Automatic Heated Seat Customization Availability Flag 5";
BA_ "SignalType" SG_ 1638 AutoHtdStCstAvlFlg5 "BLN";
BA_ "GenSigSendType" SG_ 1638 AutoHtdStCstAvlFlg5 1;
BA_ "SignalLongName" SG_ 1638 AutoHtdStCstAvlFlg6 "Automatic Heated Seat Customization Availability Flag 6";
BA_ "SignalType" SG_ 1638 AutoHtdStCstAvlFlg6 "BLN";
BA_ "GenSigSendType" SG_ 1638 AutoHtdStCstAvlFlg6 1;
BA_ "SignalLongName" SG_ 1638 AutoHtdStCstAvlFlg7 "Automatic Heated Seat Customization Availability Flag 7";
BA_ "SignalType" SG_ 1638 AutoHtdStCstAvlFlg7 "BLN";
BA_ "GenSigSendType" SG_ 1638 AutoHtdStCstAvlFlg7 1;
BA_ "SignalLongName" SG_ 1638 HVACRmtStrtStCstCurSetVal "HVAC Remote Start Setting Customization Current Setting Value";
BA_ "SignalType" SG_ 1638 HVACRmtStrtStCstCurSetVal "ENM";
BA_ "GenSigSendType" SG_ 1638 HVACRmtStrtStCstCurSetVal 1;
BA_ "SignalLongName" SG_ 1638 HVACRmtStrtStCstStAvl "HVAC Remote Start Setting Customization Setting Available";
BA_ "SignalType" SG_ 1638 HVACRmtStrtStCstStAvl "BLN";
BA_ "GenSigSendType" SG_ 1638 HVACRmtStrtStCstStAvl 1;
BA_ "SignalLongName" SG_ 1638 HVACRmtStrtStCstAvlFlg1 "HVAC Remote Start Setting Customization Availability Flag 1";
BA_ "SignalType" SG_ 1638 HVACRmtStrtStCstAvlFlg1 "BLN";
BA_ "GenSigSendType" SG_ 1638 HVACRmtStrtStCstAvlFlg1 1;
BA_ "SignalLongName" SG_ 1638 HVACRmtStrtStCstAvlFlg2 "HVAC Remote Start Setting Customization Availability Flag 2";
BA_ "SignalType" SG_ 1638 HVACRmtStrtStCstAvlFlg2 "BLN";
BA_ "GenSigSendType" SG_ 1638 HVACRmtStrtStCstAvlFlg2 1;
BA_ "SignalLongName" SG_ 1638 HVACRmtStrtStCstAvlFlg3 "HVAC Remote Start Setting Customization Availability Flag 3";
BA_ "SignalType" SG_ 1638 HVACRmtStrtStCstAvlFlg3 "BLN";
BA_ "GenSigSendType" SG_ 1638 HVACRmtStrtStCstAvlFlg3 1;
BA_ "SignalLongName" SG_ 1638 HVACRmtStrtStCstAvlFlg4 "HVAC Remote Start Setting Customization Availability Flag 4";
BA_ "SignalType" SG_ 1638 HVACRmtStrtStCstAvlFlg4 "BLN";
BA_ "GenSigSendType" SG_ 1638 HVACRmtStrtStCstAvlFlg4 1;
BA_ "SignalLongName" SG_ 1638 HVACRmtStrtStCstAvlFlg5 "HVAC Remote Start Setting Customization Availability Flag 5";
BA_ "SignalType" SG_ 1638 HVACRmtStrtStCstAvlFlg5 "BLN";
BA_ "GenSigSendType" SG_ 1638 HVACRmtStrtStCstAvlFlg5 1;
BA_ "SignalLongName" SG_ 1638 HVACRmtStrtStCstAvlFlg6 "HVAC Remote Start Setting Customization Availability Flag 6";
BA_ "SignalType" SG_ 1638 HVACRmtStrtStCstAvlFlg6 "BLN";
BA_ "GenSigSendType" SG_ 1638 HVACRmtStrtStCstAvlFlg6 1;
BA_ "SignalLongName" SG_ 1638 HVACRmtStrtStCstAvlFlg7 "HVAC Remote Start Setting Customization Availability Flag 7";
BA_ "SignalType" SG_ 1638 HVACRmtStrtStCstAvlFlg7 "BLN";
BA_ "GenSigSendType" SG_ 1638 HVACRmtStrtStCstAvlFlg7 1;
BA_ "SignalLongName" SG_ 1631 AirQltySensCstChgSetReq "Air Quality Sensor Customization Change Setting Request";
BA_ "SignalType" SG_ 1631 AirQltySensCstChgSetReq "ENM";
BA_ "GenSigSendType" SG_ 1631 AirQltySensCstChgSetReq 1;
BA_ "SignalLongName" SG_ 1631 IonzrCtrlCstChgSetReq "Ionizer Control Customization Change Setting Request";
BA_ "SignalType" SG_ 1631 IonzrCtrlCstChgSetReq "ENM";
BA_ "GenSigSendType" SG_ 1631 IonzrCtrlCstChgSetReq 1;
BA_ "SignalLongName" SG_ 1631 AutoDfgCstChgSetReq "Automatic Defog Customization Change Setting Request";
BA_ "SignalType" SG_ 1631 AutoDfgCstChgSetReq "ENM";
BA_ "GenSigSendType" SG_ 1631 AutoDfgCstChgSetReq 1;
BA_ "SignalLongName" SG_ 1631 AutoFanCstChgSetReq "Automatic Fan Customization Change Setting Request";
BA_ "SignalType" SG_ 1631 AutoFanCstChgSetReq "ENM";
BA_ "GenSigSendType" SG_ 1631 AutoFanCstChgSetReq 1;
BA_ "SignalLongName" SG_ 1631 RrDfgStUpCstChgSetReq "Rear Defog Startup Customization Change Setting Request";
BA_ "SignalType" SG_ 1631 RrDfgStUpCstChgSetReq "ENM";
BA_ "GenSigSendType" SG_ 1631 RrDfgStUpCstChgSetReq 1;
BA_ "SignalLongName" SG_ 1631 RrZnStUpCstChgSetReq "Rear Zone Startup Customization Change Setting Request";
BA_ "SignalType" SG_ 1631 RrZnStUpCstChgSetReq "ENM";
BA_ "GenSigSendType" SG_ 1631 RrZnStUpCstChgSetReq 1;
BA_ "SignalLongName" SG_ 1639 AutoHtdStCstChgSetReq "Automatic Cooled Seat Customization Change Setting Request";
BA_ "SignalType" SG_ 1639 AutoHtdStCstChgSetReq "ENM";
BA_ "GenSigSendType" SG_ 1639 AutoHtdStCstChgSetReq 1;
BA_ "SignalLongName" SG_ 1639 HVACRmtStrtStCstChgSetReq "HVAC Remote Start Setting Customization Change Setting Request";
BA_ "SignalType" SG_ 1639 HVACRmtStrtStCstChgSetReq "ENM";
BA_ "GenSigSendType" SG_ 1639 HVACRmtStrtStCstChgSetReq 1;
BA_ "SignalLongName" SG_ 1704 RstrCstDfltReq "Restore Customization Defaults Request";
BA_ "SignalType" SG_ 1704 RstrCstDfltReq "BLN";
BA_ "GenSigSendType" SG_ 1704 RstrCstDfltReq 1;
BA_ "SignalLongName" SG_ 1713 IndAirDstFL "Indication Air Distribution Front Left";
BA_ "SignalType" SG_ 1713 IndAirDstFL "ENM";
BA_ "GenSigSendType" SG_ 1713 IndAirDstFL 1;
BA_ "GenSigSendOnInit" SG_ 1713 IndAirDstFL 1;
BA_ "SignalLongName" SG_ 1713 IndAirDstFR "Indication Air Distribution Front Right";
BA_ "SignalType" SG_ 1713 IndAirDstFR "ENM";
BA_ "GenSigSendType" SG_ 1713 IndAirDstFR 1;
BA_ "GenSigSendOnInit" SG_ 1713 IndAirDstFR 1;
BA_ "SignalLongName" SG_ 1713 IndFrtHVAC_On "Indication Front HVAC On";
BA_ "SignalType" SG_ 1713 IndFrtHVAC_On "BLN";
BA_ "GenSigSendType" SG_ 1713 IndFrtHVAC_On 1;
BA_ "GenSigSendOnInit" SG_ 1713 IndFrtHVAC_On 1;
BA_ "SignalLongName" SG_ 1713 IndBlwStngLvlFrt "Indication Blower Setting Level Front";
BA_ "SignalType" SG_ 1713 IndBlwStngLvlFrt "UNM";
BA_ "GenSigSendType" SG_ 1713 IndBlwStngLvlFrt 1;
BA_ "GenSigSendOnInit" SG_ 1713 IndBlwStngLvlFrt 1;
BA_ "SignalLongName" SG_ 1713 IndBlwStngStFrt "Indication Blower Setting State Front";
BA_ "SignalType" SG_ 1713 IndBlwStngStFrt "ENM";
BA_ "GenSigSendType" SG_ 1713 IndBlwStngStFrt 1;
BA_ "GenSigSendOnInit" SG_ 1713 IndBlwStngStFrt 1;
BA_ "SignalLongName" SG_ 1713 IndTmpStngLvlFL "Indication Temperature Setting Level Front Left";
BA_ "SignalType" SG_ 1713 IndTmpStngLvlFL "UNM";
BA_ "GenSigSendType" SG_ 1713 IndTmpStngLvlFL 1;
BA_ "GenSigSendOnInit" SG_ 1713 IndTmpStngLvlFL 1;
BA_ "SignalLongName" SG_ 1713 IndTmpStngStFL "Indication Temperature Setting State Front Left";
BA_ "SignalType" SG_ 1713 IndTmpStngStFL "ENM";
BA_ "GenSigSendType" SG_ 1713 IndTmpStngStFL 1;
BA_ "GenSigSendOnInit" SG_ 1713 IndTmpStngStFL 1;
BA_ "SignalLongName" SG_ 1713 IndTmpStngLvlFR "Indication Temperature Setting Level Front Right";
BA_ "SignalType" SG_ 1713 IndTmpStngLvlFR "UNM";
BA_ "GenSigSendType" SG_ 1713 IndTmpStngLvlFR 1;
BA_ "GenSigSendOnInit" SG_ 1713 IndTmpStngLvlFR 1;
BA_ "SignalLongName" SG_ 1713 IndTmpStngStFR "Indication Temperature Setting State Front Right";
BA_ "SignalType" SG_ 1713 IndTmpStngStFR "ENM";
BA_ "GenSigSendType" SG_ 1713 IndTmpStngStFR 1;
BA_ "GenSigSendOnInit" SG_ 1713 IndTmpStngStFR 1;
BA_ "SignalLongName" SG_ 1713 IndTmpUnts "Indication Temperature Units";
BA_ "SignalType" SG_ 1713 IndTmpUnts "ENM";
BA_ "GenSigSendType" SG_ 1713 IndTmpUnts 1;
BA_ "GenSigSendOnInit" SG_ 1713 IndTmpUnts 1;
BA_ "SignalLongName" SG_ 1713 IndRecircStng "Indication Recirculation Setting";
BA_ "SignalType" SG_ 1713 IndRecircStng "ENM";
BA_ "GenSigSendType" SG_ 1713 IndRecircStng 1;
BA_ "GenSigSendOnInit" SG_ 1713 IndRecircStng 1;
BA_ "SignalLongName" SG_ 1713 IndFogPrtcTkngFrshAirActMsg "Indication Fog Protection Taking Fresh Air Action Message";
BA_ "SignalType" SG_ 1713 IndFogPrtcTkngFrshAirActMsg "BLN";
BA_ "GenSigSendType" SG_ 1713 IndFogPrtcTkngFrshAirActMsg 1;
BA_ "GenSigSendOnInit" SG_ 1713 IndFogPrtcTkngFrshAirActMsg 1;
BA_ "SignalLongName" SG_ 1713 IndAirQltSysTkngRecircActMsg "Indication Air Quality System Taking Recirc Action Message";
BA_ "SignalType" SG_ 1713 IndAirQltSysTkngRecircActMsg "BLN";
BA_ "GenSigSendType" SG_ 1713 IndAirQltSysTkngRecircActMsg 1;
BA_ "GenSigSendOnInit" SG_ 1713 IndAirQltSysTkngRecircActMsg 1;
BA_ "SignalLongName" SG_ 1713 IndLowSpdPlltnTkngRecircActMsg "Indication Low Speed Pollution Taking Recirc Action Meassage";
BA_ "SignalType" SG_ 1713 IndLowSpdPlltnTkngRecircActMsg "BLN";
BA_ "GenSigSendType" SG_ 1713 IndLowSpdPlltnTkngRecircActMsg 1;
BA_ "GenSigSendOnInit" SG_ 1713 IndLowSpdPlltnTkngRecircActMsg 1;
BA_ "SignalLongName" SG_ 1713 IndRrWndDfgStng "Indication Rear Window Defog Setting";
BA_ "SignalType" SG_ 1713 IndRrWndDfgStng "ENM";
BA_ "GenSigSendType" SG_ 1713 IndRrWndDfgStng 1;
BA_ "GenSigSendOnInit" SG_ 1713 IndRrWndDfgStng 1;
BA_ "SignalLongName" SG_ 1713 AirCndActIO "Air Conditioning Active Indication ON";
BA_ "SignalType" SG_ 1713 AirCndActIO "BLN";
BA_ "GenSigSendType" SG_ 1713 AirCndActIO 1;
BA_ "GenSigSendOnInit" SG_ 1713 AirCndActIO 1;
BA_ "SignalLongName" SG_ 1713 IndCompStng "Indication Compressor Setting";
BA_ "SignalType" SG_ 1713 IndCompStng "ENM";
BA_ "GenSigSendType" SG_ 1713 IndCompStng 1;
BA_ "GenSigSendOnInit" SG_ 1713 IndCompStng 1;
BA_ "SignalLongName" SG_ 1713 IndClmMdStng "Indication Climate Mode Setting";
BA_ "SignalType" SG_ 1713 IndClmMdStng "ENM";
BA_ "GenSigSendType" SG_ 1713 IndClmMdStng 1;
BA_ "GenSigSendOnInit" SG_ 1713 IndClmMdStng 1;
BA_ "SignalLongName" SG_ 1713 IndInzrStat "Indication Ionizer Status";
BA_ "SignalType" SG_ 1713 IndInzrStat "ENM";
BA_ "GenSigSendType" SG_ 1713 IndInzrStat 1;
BA_ "GenSigSendOnInit" SG_ 1713 IndInzrStat 1;
BA_ "SignalLongName" SG_ 1713 IndAC_OnBatCoolMsg "Indication AC On for Battery Cooling Message";
BA_ "SignalType" SG_ 1713 IndAC_OnBatCoolMsg "BLN";
BA_ "GenSigSendType" SG_ 1713 IndAC_OnBatCoolMsg 1;
BA_ "GenSigSendOnInit" SG_ 1713 IndAC_OnBatCoolMsg 1;
BA_ "SignalLongName" SG_ 1713 IndSYNC_All "Indication SYNC ALL";
BA_ "SignalType" SG_ 1713 IndSYNC_All "BLN";
BA_ "GenSigSendType" SG_ 1713 IndSYNC_All 1;
BA_ "GenSigSendOnInit" SG_ 1713 IndSYNC_All 1;
BA_ "SignalLongName" SG_ 1713 HVAC_StngsCtrlAvlbl "HVAC Settings Controller Available";
BA_ "SignalType" SG_ 1713 HVAC_StngsCtrlAvlbl "BLN";
BA_ "GenSigSendType" SG_ 1713 HVAC_StngsCtrlAvlbl 1;
BA_ "GenSigSendOnInit" SG_ 1713 HVAC_StngsCtrlAvlbl 1;
BA_ "SignalLongName" SG_ 1716 ReqAirDstFLInfo "Request Air Distribution Front Left Info";
BA_ "SignalType" SG_ 1716 ReqAirDstFLInfo "ENM";
BA_ "GenSigSendType" SG_ 1716 ReqAirDstFLInfo 1;
BA_ "GenSigSendOnInit" SG_ 1716 ReqAirDstFLInfo 1;
BA_ "SignalLongName" SG_ 1716 ReqAirDstFRInfo "Request Air Distribution Front Right Info";
BA_ "SignalType" SG_ 1716 ReqAirDstFRInfo "ENM";
BA_ "GenSigSendType" SG_ 1716 ReqAirDstFRInfo 1;
BA_ "GenSigSendOnInit" SG_ 1716 ReqAirDstFRInfo 1;
BA_ "SignalLongName" SG_ 1716 ReqFrtHVAC_PwrChgInfo "Request Front HVAC Power Change Info";
BA_ "SignalType" SG_ 1716 ReqFrtHVAC_PwrChgInfo "BLN";
BA_ "GenSigSendType" SG_ 1716 ReqFrtHVAC_PwrChgInfo 1;
BA_ "GenSigSendOnInit" SG_ 1716 ReqFrtHVAC_PwrChgInfo 1;
BA_ "SignalLongName" SG_ 1716 ReqFrtAutoInfo "Request Front Auto Info";
BA_ "SignalType" SG_ 1716 ReqFrtAutoInfo "BLN";
BA_ "GenSigSendType" SG_ 1716 ReqFrtAutoInfo 1;
BA_ "GenSigSendOnInit" SG_ 1716 ReqFrtAutoInfo 1;
BA_ "SignalLongName" SG_ 1716 ReqBlwLvlChgFrtInfo "Request Blower Level Change Front Info";
BA_ "SignalType" SG_ 1716 ReqBlwLvlChgFrtInfo "UNM";
BA_ "GenSigStartValue" SG_ 1716 ReqBlwLvlChgFrtInfo 16;
BA_ "GenSigSendType" SG_ 1716 ReqBlwLvlChgFrtInfo 1;
BA_ "GenSigSendOnInit" SG_ 1716 ReqBlwLvlChgFrtInfo 1;
BA_ "SignalLongName" SG_ 1716 ReqBlwLvlFrtInfo "Request Blower Level Front Info";
BA_ "SignalType" SG_ 1716 ReqBlwLvlFrtInfo "UNM";
BA_ "GenSigSendType" SG_ 1716 ReqBlwLvlFrtInfo 1;
BA_ "GenSigSendOnInit" SG_ 1716 ReqBlwLvlFrtInfo 1;
BA_ "SignalLongName" SG_ 1716 ReqBlwLvlFrtAtvInfo "Request Blower Level Front Active Info";
BA_ "SignalType" SG_ 1716 ReqBlwLvlFrtAtvInfo "BLN";
BA_ "GenSigSendType" SG_ 1716 ReqBlwLvlFrtAtvInfo 1;
BA_ "GenSigSendOnInit" SG_ 1716 ReqBlwLvlFrtAtvInfo 1;
BA_ "SignalLongName" SG_ 1716 ReqBlwSpdRdctnInfo "Request Blower Speed Reduction Info";
BA_ "SignalType" SG_ 1716 ReqBlwSpdRdctnInfo "BLN";
BA_ "GenSigSendType" SG_ 1716 ReqBlwSpdRdctnInfo 1;
BA_ "GenSigSendOnInit" SG_ 1716 ReqBlwSpdRdctnInfo 1;
BA_ "SignalLongName" SG_ 1716 ReqTmpChgFLInfo "Request Temperature Change Front Left Info";
BA_ "SignalType" SG_ 1716 ReqTmpChgFLInfo "UNM";
BA_ "GenSigStartValue" SG_ 1716 ReqTmpChgFLInfo 64;
BA_ "GenSigSendType" SG_ 1716 ReqTmpChgFLInfo 1;
BA_ "GenSigSendOnInit" SG_ 1716 ReqTmpChgFLInfo 1;
BA_ "SignalLongName" SG_ 1716 ReqTmpChgFRInfo "Request Temperature Change Front Right Info";
BA_ "SignalType" SG_ 1716 ReqTmpChgFRInfo "UNM";
BA_ "GenSigStartValue" SG_ 1716 ReqTmpChgFRInfo 64;
BA_ "GenSigSendType" SG_ 1716 ReqTmpChgFRInfo 1;
BA_ "GenSigSendOnInit" SG_ 1716 ReqTmpChgFRInfo 1;
BA_ "SignalLongName" SG_ 1716 ReqTmpLvlFLInfo "Request Temperature Level Front Left Info";
BA_ "SignalType" SG_ 1716 ReqTmpLvlFLInfo "UNM";
BA_ "GenSigSendType" SG_ 1716 ReqTmpLvlFLInfo 1;
BA_ "GenSigSendOnInit" SG_ 1716 ReqTmpLvlFLInfo 1;
BA_ "SignalLongName" SG_ 1716 ReqTmpLvlFLAtvInfo "Request Temperature Level Front Left Active Info";
BA_ "SignalType" SG_ 1716 ReqTmpLvlFLAtvInfo "BLN";
BA_ "GenSigSendType" SG_ 1716 ReqTmpLvlFLAtvInfo 1;
BA_ "GenSigSendOnInit" SG_ 1716 ReqTmpLvlFLAtvInfo 1;
BA_ "SignalLongName" SG_ 1716 ReqTmpLvlFRInfo "Request Temperature Level Front Right Info";
BA_ "SignalType" SG_ 1716 ReqTmpLvlFRInfo "UNM";
BA_ "GenSigSendType" SG_ 1716 ReqTmpLvlFRInfo 1;
BA_ "GenSigSendOnInit" SG_ 1716 ReqTmpLvlFRInfo 1;
BA_ "SignalLongName" SG_ 1716 ReqTmpLvlFRAtvInfo "Request Temperature Level Front Right Active Info";
BA_ "SignalType" SG_ 1716 ReqTmpLvlFRAtvInfo "BLN";
BA_ "GenSigSendType" SG_ 1716 ReqTmpLvlFRAtvInfo 1;
BA_ "GenSigSendOnInit" SG_ 1716 ReqTmpLvlFRAtvInfo 1;
BA_ "SignalLongName" SG_ 1716 ReqRecircStngChgInfo "Request Recirculation Setting Change Info";
BA_ "SignalType" SG_ 1716 ReqRecircStngChgInfo "BLN";
BA_ "GenSigSendType" SG_ 1716 ReqRecircStngChgInfo 1;
BA_ "GenSigSendOnInit" SG_ 1716 ReqRecircStngChgInfo 1;
BA_ "SignalLongName" SG_ 1716 ReqCompStngChgInfo "Request Compressor Setting Change Info";
BA_ "SignalType" SG_ 1716 ReqCompStngChgInfo "BLN";
BA_ "GenSigSendType" SG_ 1716 ReqCompStngChgInfo 1;
BA_ "GenSigSendOnInit" SG_ 1716 ReqCompStngChgInfo 1;
BA_ "SignalLongName" SG_ 1716 ReqCompStngInfo "Request Compressor Setting Info";
BA_ "SignalType" SG_ 1716 ReqCompStngInfo "ENM";
BA_ "GenSigSendType" SG_ 1716 ReqCompStngInfo 1;
BA_ "GenSigSendOnInit" SG_ 1716 ReqCompStngInfo 1;
BA_ "SignalLongName" SG_ 1716 ReqClmtMdStngChgInfo "Request Climate Mode Setting Change Info";
BA_ "SignalType" SG_ 1716 ReqClmtMdStngChgInfo "BLN";
BA_ "GenSigSendType" SG_ 1716 ReqClmtMdStngChgInfo 1;
BA_ "GenSigSendOnInit" SG_ 1716 ReqClmtMdStngChgInfo 1;
BA_ "SignalLongName" SG_ 1716 ReqClmtMdStngInfo "Request Climate Mode Setting Info";
BA_ "SignalType" SG_ 1716 ReqClmtMdStngInfo "ENM";
BA_ "GenSigSendType" SG_ 1716 ReqClmtMdStngInfo 1;
BA_ "GenSigSendOnInit" SG_ 1716 ReqClmtMdStngInfo 1;
BA_ "SignalLongName" SG_ 1716 ReqSYNC_AllChgInfo "Request SYNC All Change Info";
BA_ "SignalType" SG_ 1716 ReqSYNC_AllChgInfo "BLN";
BA_ "GenSigSendType" SG_ 1716 ReqSYNC_AllChgInfo 1;
BA_ "GenSigSendOnInit" SG_ 1716 ReqSYNC_AllChgInfo 1;
BA_ "SignalLongName" SG_ 1717 ReqFrtClmtApp "Request Front Climate APP";
BA_ "SignalType" SG_ 1717 ReqFrtClmtApp "BLN";
BA_ "GenSigSendType" SG_ 1717 ReqFrtClmtApp 1;
BA_ "GenSigSendOnInit" SG_ 1717 ReqFrtClmtApp 1;
BA_ "SignalLongName" SG_ 858 GPSDtaTmMAC1 "GPS Date and Time MAC1";
BA_ "SignalType" SG_ 858 GPSDtaTmMAC1 "UNM";
BA_ "GenSigSendType" SG_ 858 GPSDtaTmMAC1 1;
BA_ "SignalLongName" SG_ 858 GPSDtaTmAntiRplyCnt1 "GPS Date and Time Anti Replay Counter1";
BA_ "SignalType" SG_ 858 GPSDtaTmAntiRplyCnt1 "UNM";
BA_ "GenSigSendType" SG_ 858 GPSDtaTmAntiRplyCnt1 1;
BA_ "SignalLongName" SG_ 858 GPSDtaTmARC1 "GPS Date and Time Alive Rolling Counter1";
BA_ "SignalType" SG_ 858 GPSDtaTmARC1 "UNM";
BA_ "GenSigSendType" SG_ 858 GPSDtaTmARC1 1;
BA_ "SignalLongName" SG_ 858 CldrYr_154Mac "Calendar Year";
BA_ "SignalType" SG_ 858 CldrYr_154Mac "UNM";
BA_ "GenSigDeltaValue" SG_ 858 CldrYr_154Mac 1;
BA_ "GenSigSendType" SG_ 858 CldrYr_154Mac 1;
BA_ "GenSigSendOnInit" SG_ 858 CldrYr_154Mac 1;
BA_ "SignalLongName" SG_ 858 CldrMth_154Mac "Calendar Month";
BA_ "SignalType" SG_ 858 CldrMth_154Mac "ENM";
BA_ "GenSigSendType" SG_ 858 CldrMth_154Mac 1;
BA_ "GenSigSendOnInit" SG_ 858 CldrMth_154Mac 1;
BA_ "SignalLongName" SG_ 858 CldrDay_154Mac "Calendar Day";
BA_ "SignalType" SG_ 858 CldrDay_154Mac "UNM";
BA_ "GenSigDeltaValue" SG_ 858 CldrDay_154Mac 1;
BA_ "GenSigSendType" SG_ 858 CldrDay_154Mac 1;
BA_ "GenSigSendOnInit" SG_ 858 CldrDay_154Mac 1;
BA_ "SignalLongName" SG_ 859 GPSDtaTmMAC2 "GPS Date and Time MAC2";
BA_ "SignalType" SG_ 859 GPSDtaTmMAC2 "UNM";
BA_ "GenSigSendType" SG_ 859 GPSDtaTmMAC2 1;
BA_ "SignalLongName" SG_ 859 GPSDtaTmAntiRplyCnt2 "GPS Date and Time Anti Replay Counter2";
BA_ "SignalType" SG_ 859 GPSDtaTmAntiRplyCnt2 "UNM";
BA_ "GenSigSendType" SG_ 859 GPSDtaTmAntiRplyCnt2 1;
BA_ "SignalLongName" SG_ 859 GPSDtaTmARC2 "GPS Date and Time Alive Rolling Counter2";
BA_ "SignalType" SG_ 859 GPSDtaTmARC2 "UNM";
BA_ "GenSigSendType" SG_ 859 GPSDtaTmARC2 1;
BA_ "SignalLongName" SG_ 859 HrsVMac "Hours Validity";
BA_ "SignalType" SG_ 859 HrsVMac "ENM";
BA_ "GenSigSendType" SG_ 859 HrsVMac 1;
BA_ "GenSigSendOnInit" SG_ 859 HrsVMac 1;
BA_ "SignalLongName" SG_ 859 HrsMac "Hours";
BA_ "SignalType" SG_ 859 HrsMac "UNM";
BA_ "GenSigDeltaValue" SG_ 859 HrsMac 1;
BA_ "GenSigSendType" SG_ 859 HrsMac 1;
BA_ "GenSigSendOnInit" SG_ 859 HrsMac 1;
BA_ "SignalLongName" SG_ 859 MinsVMac "Minutes Validity";
BA_ "SignalType" SG_ 859 MinsVMac "ENM";
BA_ "GenSigSendType" SG_ 859 MinsVMac 1;
BA_ "GenSigSendOnInit" SG_ 859 MinsVMac 1;
BA_ "SignalLongName" SG_ 859 MinsMac "Minutes";
BA_ "SignalType" SG_ 859 MinsMac "UNM";
BA_ "GenSigDeltaValue" SG_ 859 MinsMac 1;
BA_ "GenSigSendType" SG_ 859 MinsMac 1;
BA_ "GenSigSendOnInit" SG_ 859 MinsMac 1;
BA_ "SignalLongName" SG_ 859 SecVMac "Seconds Validity";
BA_ "SignalType" SG_ 859 SecVMac "ENM";
BA_ "GenSigSendType" SG_ 859 SecVMac 1;
BA_ "GenSigSendOnInit" SG_ 859 SecVMac 1;
BA_ "SignalLongName" SG_ 859 SecMac "Seconds";
BA_ "SignalType" SG_ 859 SecMac "UNM";
BA_ "GenSigDeltaValue" SG_ 859 SecMac 1;
BA_ "GenSigSendType" SG_ 859 SecMac 1;
BA_ "GenSigSendOnInit" SG_ 859 SecMac 1;
BA_ "SignalLongName" SG_ 1147 CllNtwkDaTMAC2 "Cellular Network Date and Time MAC2";
BA_ "SignalType" SG_ 1147 CllNtwkDaTMAC2 "UNM";
BA_ "GenSigSendType" SG_ 1147 CllNtwkDaTMAC2 1;
BA_ "SignalLongName" SG_ 1147 CllNtwkDaTAntiRplyCnt2 "Cellular Network Date and Time Anti Replay Counter2";
BA_ "SignalType" SG_ 1147 CllNtwkDaTAntiRplyCnt2 "UNM";
BA_ "GenSigSendType" SG_ 1147 CllNtwkDaTAntiRplyCnt2 1;
BA_ "SignalLongName" SG_ 1147 CllNtwkDaTARC2 "Cellular Network Date and Time Alive Rolling Counter2";
BA_ "SignalType" SG_ 1147 CllNtwkDaTARC2 "UNM";
BA_ "GenSigSendType" SG_ 1147 CllNtwkDaTARC2 1;
BA_ "SignalLongName" SG_ 1147 CldrDayCmpstdValMac "Calendar Day Compensated Value";
BA_ "SignalType" SG_ 1147 CldrDayCmpstdValMac "UNM";
BA_ "GenSigDeltaValue" SG_ 1147 CldrDayCmpstdValMac 1;
BA_ "GenSigSendType" SG_ 1147 CldrDayCmpstdValMac 1;
BA_ "SignalLongName" SG_ 1147 CldrMthCmpstdValMac "Calendar Month Compensated Value";
BA_ "SignalType" SG_ 1147 CldrMthCmpstdValMac "ENM";
BA_ "GenSigSendType" SG_ 1147 CldrMthCmpstdValMac 1;
BA_ "SignalLongName" SG_ 1147 CldrYrCmpstdValMac "Calendar Year Compensated Value";
BA_ "SignalType" SG_ 1147 CldrYrCmpstdValMac "UNM";
BA_ "GenSigDeltaValue" SG_ 1147 CldrYrCmpstdValMac 1;
BA_ "GenSigSendType" SG_ 1147 CldrYrCmpstdValMac 1;
BA_ "SignalLongName" SG_ 1150 TmofDyMAC1 "Time of Day HS MAC1";
BA_ "SignalType" SG_ 1150 TmofDyMAC1 "UNM";
BA_ "GenSigSendType" SG_ 1150 TmofDyMAC1 1;
BA_ "SignalLongName" SG_ 1150 TmofDyAntiRplyCnt1 "Time of Day HS Anti Replay Counter1";
BA_ "SignalType" SG_ 1150 TmofDyAntiRplyCnt1 "UNM";
BA_ "GenSigSendType" SG_ 1150 TmofDyAntiRplyCnt1 1;
BA_ "SignalLongName" SG_ 1150 TmofDyARC1 "Time of Day HS Alive Rolling Counter1";
BA_ "SignalType" SG_ 1150 TmofDyARC1 "UNM";
BA_ "GenSigSendType" SG_ 1150 TmofDyARC1 1;
BA_ "SignalLongName" SG_ 1150 CldrYrMac "Calendar Year";
BA_ "SignalType" SG_ 1150 CldrYrMac "UNM";
BA_ "GenSigDeltaValue" SG_ 1150 CldrYrMac 1;
BA_ "GenSigSendType" SG_ 1150 CldrYrMac 1;
BA_ "GenSigSendOnInit" SG_ 1150 CldrYrMac 1;
BA_ "SignalLongName" SG_ 1150 CldrMthMac "Calendar Month";
BA_ "SignalType" SG_ 1150 CldrMthMac "ENM";
BA_ "GenSigSendType" SG_ 1150 CldrMthMac 1;
BA_ "GenSigSendOnInit" SG_ 1150 CldrMthMac 1;
BA_ "SignalLongName" SG_ 1150 CldrDayMac "Calendar Day";
BA_ "SignalType" SG_ 1150 CldrDayMac "UNM";
BA_ "GenSigDeltaValue" SG_ 1150 CldrDayMac 1;
BA_ "GenSigSendType" SG_ 1150 CldrDayMac 1;
BA_ "GenSigSendOnInit" SG_ 1150 CldrDayMac 1;
BA_ "SignalLongName" SG_ 1151 TmofDyMAC2 "Time of Day HS MAC2";
BA_ "SignalType" SG_ 1151 TmofDyMAC2 "UNM";
BA_ "GenSigSendType" SG_ 1151 TmofDyMAC2 1;
BA_ "SignalLongName" SG_ 1151 TmofDyAntiRplyCnt2 "Time of Day HS Anti Replay Counter2";
BA_ "SignalType" SG_ 1151 TmofDyAntiRplyCnt2 "UNM";
BA_ "GenSigSendType" SG_ 1151 TmofDyAntiRplyCnt2 1;
BA_ "SignalLongName" SG_ 1151 TmofDyARC2 "Time of Day HS Alive Rolling Counter2";
BA_ "SignalType" SG_ 1151 TmofDyARC2 "UNM";
BA_ "GenSigSendType" SG_ 1151 TmofDyARC2 1;
BA_ "SignalLongName" SG_ 1151 TimeDispFormatMac "Time Display Format";
BA_ "SignalType" SG_ 1151 TimeDispFormatMac "ENM";
BA_ "GenSigSendType" SG_ 1151 TimeDispFormatMac 1;
BA_ "GenSigSendOnInit" SG_ 1151 TimeDispFormatMac 1;
BA_ "SignalLongName" SG_ 1151 TOD_HrofDayMac "Time of Day : Hour of Day";
BA_ "SignalType" SG_ 1151 TOD_HrofDayMac "UNM";
BA_ "GenSigDeltaValue" SG_ 1151 TOD_HrofDayMac 1;
BA_ "GenSigSendType" SG_ 1151 TOD_HrofDayMac 1;
BA_ "SignalLongName" SG_ 1151 TOD_MinofHrMac "Time of Day : Minute of Hour";
BA_ "SignalType" SG_ 1151 TOD_MinofHrMac "UNM";
BA_ "GenSigDeltaValue" SG_ 1151 TOD_MinofHrMac 1;
BA_ "GenSigSendType" SG_ 1151 TOD_MinofHrMac 1;
BA_ "SignalLongName" SG_ 1151 TOD_SecofMinMac "Time of Day : Seconds of Minute";
BA_ "SignalType" SG_ 1151 TOD_SecofMinMac "UNM";
BA_ "GenSigDeltaValue" SG_ 1151 TOD_SecofMinMac 1;
BA_ "GenSigSendType" SG_ 1151 TOD_SecofMinMac 1;
BA_ "SignalLongName" SG_ 921 DTCIUnused6_399 "Diagnostic Trouble Code Information Extended 399 : Unused 6";
BA_ "SignalType" SG_ 921 DTCIUnused6_399 "BLN";
BA_ "SignalLongName" SG_ 921 DTCIUnused5_399 "Diagnostic Trouble Code Information Extended 399 : Unused 5";
BA_ "SignalType" SG_ 921 DTCIUnused5_399 "BLN";
BA_ "SignalLongName" SG_ 921 DTCIUnused4_399 "Diagnostic Trouble Code Information Extended 399 : Unused 4";
BA_ "SignalType" SG_ 921 DTCIUnused4_399 "BLN";
BA_ "SignalLongName" SG_ 921 DTCIUnused3_399 "Diagnostic Trouble Code Information Extended 399 : Unused 3";
BA_ "SignalType" SG_ 921 DTCIUnused3_399 "BLN";
BA_ "SignalLongName" SG_ 921 DTCIUnused2_399 "Diagnostic Trouble Code Information Extended 399 : Unused 2";
BA_ "SignalType" SG_ 921 DTCIUnused2_399 "BLN";
BA_ "SignalLongName" SG_ 921 DTCIUnused1_399 "Diagnostic Trouble Code Information Extended 399 : Unused 1";
BA_ "SignalType" SG_ 921 DTCIUnused1_399 "BLN";
BA_ "SignalLongName" SG_ 921 DTCI_WrnIndTrggrd_399 "Diagnostic Trouble Code Information Extended 399 : Warning Indicator Triggered";
BA_ "SignalType" SG_ 921 DTCI_WrnIndTrggrd_399 "BLN";
BA_ "SignalLongName" SG_ 921 DTCI_DTCTriggered_399 "Diagnostic Trouble Code Information Extended 399 : Diagnostic Trouble Code Triggered";
BA_ "SignalType" SG_ 921 DTCI_DTCTriggered_399 "BLN";
BA_ "SignalLongName" SG_ 921 DTCI_DTCSource_399 "Diagnostic Trouble Code Information Extended 399 : Diagnostic Trouble Code Source";
BA_ "SignalType" SG_ 921 DTCI_DTCSource_399 "UNM";
BA_ "SignalLongName" SG_ 921 DTCI_DTCNumber_399 "Diagnostic Trouble Code Information Extended 399 : Diagnostic Trouble Code Number";
BA_ "SignalType" SG_ 921 DTCI_DTCNumber_399 "UNM";
BA_ "SignalLongName" SG_ 921 DTCI_DTCFailType_399 "Diagnostic Trouble Code Information Extended 399 : Diagnostic Trouble Code Failure Code";
BA_ "SignalType" SG_ 921 DTCI_DTCFailType_399 "UNM";
BA_ "SignalLongName" SG_ 921 DTCI_WIR_399 "Diagnostic Trouble Code Information Extended 399 : Warning Indicator Requested";
BA_ "SignalType" SG_ 921 DTCI_WIR_399 "BLN";
BA_ "SignalLongName" SG_ 921 DTCI_TNCTOC_399 "Diagnostic Trouble Code Information Extended 399 : Test Not Completed This Operation Cycle";
BA_ "SignalType" SG_ 921 DTCI_TNCTOC_399 "BLN";
BA_ "SignalLongName" SG_ 921 DTCI_TFSLC_399 "Diagnostic Trouble Code Information Extended 399 : Test Failed Since Last Clear";
BA_ "SignalType" SG_ 921 DTCI_TFSLC_399 "BLN";
BA_ "SignalLongName" SG_ 921 DTCI_TNCSLC_399 "Diagnostic Trouble Code Information Extended 399 : Test Not Completed Since Last Clear";
BA_ "SignalType" SG_ 921 DTCI_TNCSLC_399 "BLN";
BA_ "SignalLongName" SG_ 921 DTCI_CDTC_399 "Diagnostic Trouble Code Information Extended 399 : Confirmed DTC";
BA_ "SignalType" SG_ 921 DTCI_CDTC_399 "BLN";
BA_ "SignalLongName" SG_ 921 DTCI_PDTC_399 "Diagnostic Trouble Code Information Extended 399 : Pending DTC";
BA_ "SignalType" SG_ 921 DTCI_PDTC_399 "BLN";
BA_ "SignalLongName" SG_ 921 DTCI_TFTOC_399 "Diagnostic Trouble Code Information Extended 399 : Test Failed This Operation Cycle";
BA_ "SignalType" SG_ 921 DTCI_TFTOC_399 "BLN";
BA_ "SignalLongName" SG_ 921 DTCI_TF_399 "Diagnostic Trouble Code Information Extended 399 : Test Failed";
BA_ "SignalType" SG_ 921 DTCI_TF_399 "BLN";
BA_ "SignalLongName" SG_ 921 DTCI_DTCFaultType_399 "Diagnostic Trouble Code Information Extended 399 : Diagnostic Trouble Code Fault Type";
BA_ "SignalType" SG_ 921 DTCI_DTCFaultType_399 "ENM";
BA_ "SignalLongName" SG_ 874 HtrCoreInltClntTmpCalcV "Heater Core Inlet Coolant Temperature Calculated Validity";
BA_ "SignalType" SG_ 874 HtrCoreInltClntTmpCalcV "ENM";
BA_ "GenSigSendType" SG_ 874 HtrCoreInltClntTmpCalcV 1;
BA_ "SignalLongName" SG_ 874 AuxHtrAtv "Auxiliary Heater Active";
BA_ "SignalType" SG_ 874 AuxHtrAtv "BLN";
BA_ "GenSigSendType" SG_ 874 AuxHtrAtv 1;
BA_ "SignalLongName" SG_ 874 CCClntCrcFlwRtReq "Climate Control Coolant Circulation Flow Rate Request";
BA_ "SignalType" SG_ 874 CCClntCrcFlwRtReq "UNM";
BA_ "GenSigDeltaValue" SG_ 874 CCClntCrcFlwRtReq 1;
BA_ "GenSigSendType" SG_ 874 CCClntCrcFlwRtReq 1;
BA_ "GenSigSendOnInit" SG_ 874 CCClntCrcFlwRtReq 2;
BA_ "SignalLongName" SG_ 874 HtrCoreInltClntTmpCalc "Heater Core Inlet Coolant Temperature Calculated";
BA_ "SignalType" SG_ 874 HtrCoreInltClntTmpCalc "UNM";
BA_ "GenSigDeltaValue" SG_ 874 HtrCoreInltClntTmpCalc 1;
BA_ "GenSigSendType" SG_ 874 HtrCoreInltClntTmpCalc 1;
BA_ "SignalLongName" SG_ 912 ClmtHtPwrRqd "Climate Heating Power Required";
BA_ "SignalType" SG_ 912 ClmtHtPwrRqd "BLN";
BA_ "GenSigSendType" SG_ 912 ClmtHtPwrRqd 1;
BA_ "SignalLongName" SG_ 912 ClntHtrElecPwrReq "Coolant Heater Electrical Power Request";
BA_ "SignalType" SG_ 912 ClntHtrElecPwrReq "UNM";
BA_ "GenSigDeltaValue" SG_ 912 ClntHtrElecPwrReq 1;
BA_ "GenSigSendType" SG_ 912 ClntHtrElecPwrReq 1;
BA_ "SignalLongName" SG_ 912 EstACCompPwrRchCbnCmf "Estimated Air Conditioning Control Power to Reach Cabin Comfort";
BA_ "SignalType" SG_ 912 EstACCompPwrRchCbnCmf "UNM";
BA_ "GenSigDeltaValue" SG_ 912 EstACCompPwrRchCbnCmf 1;
BA_ "GenSigSendType" SG_ 912 EstACCompPwrRchCbnCmf 1;
BA_ "SignalLongName" SG_ 912 EstACCompPwrMtnCbnCmf "Estimated Air Conditioning Control Power to Maintain Cabin Comfort";
BA_ "SignalType" SG_ 912 EstACCompPwrMtnCbnCmf "UNM";
BA_ "GenSigDeltaValue" SG_ 912 EstACCompPwrMtnCbnCmf 1;
BA_ "GenSigSendType" SG_ 912 EstACCompPwrMtnCbnCmf 1;
BA_ "SignalLongName" SG_ 965 HybMdDisp "Hybrid Mode Display";
BA_ "SignalType" SG_ 965 HybMdDisp "ENM";
BA_ "GenSigSendType" SG_ 965 HybMdDisp 1;
BA_ "GenSigSendOnInit" SG_ 965 HybMdDisp 1;
BA_ "SignalLongName" SG_ 965 JmpStrtStat "Jump Start Status";
BA_ "SignalType" SG_ 965 JmpStrtStat "ENM";
BA_ "GenSigSendType" SG_ 965 JmpStrtStat 1;
BA_ "GenSigSendOnInit" SG_ 965 JmpStrtStat 1;
BA_ "SignalLongName" SG_ 965 SvcHybridSysIO "Service Hybrid System Indication On";
BA_ "SignalType" SG_ 965 SvcHybridSysIO "BLN";
BA_ "GenSigSendType" SG_ 965 SvcHybridSysIO 1;
BA_ "GenSigSendOnInit" SG_ 965 SvcHybridSysIO 1;
BA_ "SignalLongName" SG_ 965 CstmrUsblSOC "Customer Usable State of Charge";
BA_ "SignalType" SG_ 965 CstmrUsblSOC "UNM";
BA_ "GenSigDeltaValue" SG_ 965 CstmrUsblSOC 1;
BA_ "GenSigSendType" SG_ 965 CstmrUsblSOC 1;
BA_ "GenSigSendOnInit" SG_ 965 CstmrUsblSOC 1;
BA_ "SignalLongName" SG_ 965 CstmrUsblSOCV "Customer Usable State of Charge Validity";
BA_ "SignalType" SG_ 965 CstmrUsblSOCV "ENM";
BA_ "GenSigSendType" SG_ 965 CstmrUsblSOCV 1;
BA_ "GenSigSendOnInit" SG_ 965 CstmrUsblSOCV 1;
BA_ "SignalLongName" SG_ 965 BattCntrlPrcssrVDA "Battery Control Processor Virtual Device Availability";
BA_ "SignalType" SG_ 965 BattCntrlPrcssrVDA "ENM";
BA_ "GenSigStartValue" SG_ 965 BattCntrlPrcssrVDA 1;
BA_ "GenSigSendType" SG_ 965 BattCntrlPrcssrVDA 1;
BA_ "GenSigSendOnInit" SG_ 965 BattCntrlPrcssrVDA 1;
BA_ "SignalLongName" SG_ 965 InstDrvEff "Instantaneous Drive Efficiency";
BA_ "SignalType" SG_ 965 InstDrvEff "SNM";
BA_ "GenSigDeltaValue" SG_ 965 InstDrvEff 1;
BA_ "GenSigSendType" SG_ 965 InstDrvEff 1;
BA_ "GenSigSendOnInit" SG_ 965 InstDrvEff 1;
BA_ "SignalLongName" SG_ 965 ClntCrcFlwRtEst "Coolant Circulation Flow Rate Estimated";
BA_ "SignalType" SG_ 965 ClntCrcFlwRtEst "UNM";
BA_ "GenSigDeltaValue" SG_ 965 ClntCrcFlwRtEst 1;
BA_ "GenSigSendType" SG_ 965 ClntCrcFlwRtEst 1;
BA_ "GenSigSendOnInit" SG_ 965 ClntCrcFlwRtEst 1;
BA_ "SignalLongName" SG_ 313 OffBrdVehImmbNot "Off Board Vehicle Immobilization Notification";
BA_ "SignalType" SG_ 313 OffBrdVehImmbNot "ENM";
BA_ "SignalLongName" SG_ 313 HVInvRatVltV "High Voltage Inverter Rationalized Voltage  Validity";
BA_ "SignalType" SG_ 313 HVInvRatVltV "ENM";
BA_ "GenSigSendOnInit" SG_ 313 HVInvRatVltV 1;
BA_ "SignalLongName" SG_ 313 HybChrgMdStat "Hybrid Charge Mode State";
BA_ "SignalType" SG_ 313 HybChrgMdStat "ENM";
BA_ "GenSigSendOnInit" SG_ 313 HybChrgMdStat 1;
BA_ "SignalLongName" SG_ 313 HVInvRatVlt "High Voltage Inverter Rationalized Voltage";
BA_ "SignalType" SG_ 313 HVInvRatVlt "UNM";
BA_ "GenSigSendOnInit" SG_ 313 HVInvRatVlt 1;
BA_ "SignalLongName" SG_ 313 ElecPrplsnMtrTach "Electric Propulsion Motor Tachometer";
BA_ "SignalType" SG_ 313 ElecPrplsnMtrTach "UNM";
BA_ "SignalLongName" SG_ 315 EvpCorOtltAirTmpCalcdV "Evaporator Core Outlet Air Temperature Calculated Validity";
BA_ "SignalType" SG_ 315 EvpCorOtltAirTmpCalcdV "ENM";
BA_ "GenSigSendType" SG_ 315 EvpCorOtltAirTmpCalcdV 1;
BA_ "SignalLongName" SG_ 315 ThrmlRefCompStat "Thermal Refrigerant Compressor Status";
BA_ "SignalType" SG_ 315 ThrmlRefCompStat "ENM";
BA_ "GenSigSendType" SG_ 315 ThrmlRefCompStat 1;
BA_ "GenSigSendOnInit" SG_ 315 ThrmlRefCompStat 1;
BA_ "SignalLongName" SG_ 315 EvpCorOtltAirTmpCalcd "Evaporator Core Outlet Air Temperature Calculated";
BA_ "SignalType" SG_ 315 EvpCorOtltAirTmpCalcd "UNM";
BA_ "GenSigDeltaValue" SG_ 315 EvpCorOtltAirTmpCalcd 1;
BA_ "GenSigSendType" SG_ 315 EvpCorOtltAirTmpCalcd 1;
BA_ "SignalLongName" SG_ 315 ThrmlRfCmpOvTmpFltPr "Thermal Refrigerant Compressor Over Temperature Fault Present";
BA_ "SignalType" SG_ 315 ThrmlRfCmpOvTmpFltPr "BLN";
BA_ "GenSigSendType" SG_ 315 ThrmlRfCmpOvTmpFltPr 1;
BA_ "GenSigSendOnInit" SG_ 315 ThrmlRfCmpOvTmpFltPr 1;
BA_ "SignalLongName" SG_ 315 ThrmlRefCompSpdV "Thermal Refrigerant Compressor Speed Validity";
BA_ "SignalType" SG_ 315 ThrmlRefCompSpdV "ENM";
BA_ "GenSigSendType" SG_ 315 ThrmlRefCompSpdV 1;
BA_ "GenSigSendOnInit" SG_ 315 ThrmlRefCompSpdV 1;
BA_ "SignalLongName" SG_ 315 ThrmlRefCompSpd "Thermal Refrigerant Compressor Speed";
BA_ "SignalType" SG_ 315 ThrmlRefCompSpd "UNM";
BA_ "GenSigDeltaValue" SG_ 315 ThrmlRefCompSpd 1;
BA_ "GenSigSendType" SG_ 315 ThrmlRefCompSpd 1;
BA_ "GenSigSendOnInit" SG_ 315 ThrmlRefCompSpd 1;
BA_ "SignalLongName" SG_ 314 ClmtCtrlUpprPwrLmt "Climate Control Upper Power Limit";
BA_ "SignalType" SG_ 314 ClmtCtrlUpprPwrLmt "UNM";
BA_ "GenSigDeltaValue" SG_ 314 ClmtCtrlUpprPwrLmt 1;
BA_ "GenSigSendType" SG_ 314 ClmtCtrlUpprPwrLmt 1;
BA_ "GenSigSendOnInit" SG_ 314 ClmtCtrlUpprPwrLmt 1;
BA_ "SignalLongName" SG_ 314 ClmtCtrlLwrPwrLmt "Climate Control Lower Power Limit";
BA_ "SignalType" SG_ 314 ClmtCtrlLwrPwrLmt "UNM";
BA_ "GenSigDeltaValue" SG_ 314 ClmtCtrlLwrPwrLmt 1;
BA_ "GenSigSendType" SG_ 314 ClmtCtrlLwrPwrLmt 1;
BA_ "GenSigSendOnInit" SG_ 314 ClmtCtrlLwrPwrLmt 1;
BA_ "SignalLongName" SG_ 314 ClimCtrlHVDvcShtdwnCmd "Climate Control High Voltage Device Shutdown Commanded";
BA_ "SignalType" SG_ 314 ClimCtrlHVDvcShtdwnCmd "BLN";
BA_ "GenSigSendType" SG_ 314 ClimCtrlHVDvcShtdwnCmd 1;
BA_ "GenSigSendOnInit" SG_ 314 ClimCtrlHVDvcShtdwnCmd 1;
BA_ "SignalLongName" SG_ 314 ClmCntCmpPwrUsdClc "Climate Control Compressor Power Used Calculated";
BA_ "SignalType" SG_ 314 ClmCntCmpPwrUsdClc "UNM";
BA_ "GenSigDeltaValue" SG_ 314 ClmCntCmpPwrUsdClc 1;
BA_ "GenSigSendType" SG_ 314 ClmCntCmpPwrUsdClc 1;
BA_ "SignalLongName" SG_ 317 LBCCsStAvl "Location Based Charging Customization Setting Available";
BA_ "SignalType" SG_ 317 LBCCsStAvl "BLN";
BA_ "GenSigSendType" SG_ 317 LBCCsStAvl 1;
BA_ "GenSigSendOnInit" SG_ 317 LBCCsStAvl 1;
BA_ "SignalLongName" SG_ 317 LBCChrgLvlPrfExpIO "Location Based Charging Charge Level Preference Expiration Indication On";
BA_ "SignalType" SG_ 317 LBCChrgLvlPrfExpIO "BLN";
BA_ "GenSigSendType" SG_ 317 LBCChrgLvlPrfExpIO 1;
BA_ "GenSigSendOnInit" SG_ 317 LBCChrgLvlPrfExpIO 1;
BA_ "SignalLongName" SG_ 317 AuxClntHtrVlvStat "Auxiliary Coolant Heater Valve Status";
BA_ "SignalType" SG_ 317 AuxClntHtrVlvStat "ENM";
BA_ "GenSigSendType" SG_ 317 AuxClntHtrVlvStat 1;
BA_ "GenSigSendOnInit" SG_ 317 AuxClntHtrVlvStat 1;
BA_ "SignalLongName" SG_ 317 LBCCsCrStVal "Location Based Charging Customization Current Setting Value";
BA_ "SignalType" SG_ 317 LBCCsCrStVal "ENM";
BA_ "GenSigSendType" SG_ 317 LBCCsCrStVal 1;
BA_ "GenSigSendOnInit" SG_ 317 LBCCsCrStVal 1;
BA_ "SignalLongName" SG_ 317 EngAstHtDfrdHtMdAct "Engine Assisted Heating Deferred Heat Mode Active";
BA_ "SignalType" SG_ 317 EngAstHtDfrdHtMdAct "BLN";
BA_ "GenSigSendType" SG_ 317 EngAstHtDfrdHtMdAct 1;
BA_ "SignalLongName" SG_ 317 LBCCDRR_ClrStrdPosResp "Location Based Charging Customer Data Reset Response : Clear Stored Position response";
BA_ "SignalType" SG_ 317 LBCCDRR_ClrStrdPosResp "ENM";
BA_ "GenSigSendType" SG_ 317 LBCCDRR_ClrStrdPosResp 1;
BA_ "SignalLongName" SG_ 317 LBCCDRR_PosNumbr "Location Based Charging Customer Data Reset Response : Position Number";
BA_ "SignalType" SG_ 317 LBCCDRR_PosNumbr "ENM";
BA_ "GenSigSendType" SG_ 317 LBCCDRR_PosNumbr 1;
BA_ "SignalLongName" SG_ 317 LBCPSS_PosUpdtStat "Location Based Charging Position Storage Status : Position Update Status";
BA_ "SignalType" SG_ 317 LBCPSS_PosUpdtStat "ENM";
BA_ "GenSigSendType" SG_ 317 LBCPSS_PosUpdtStat 1;
BA_ "SignalLongName" SG_ 317 LBCPSS_PosUpdtLct "Location Based Charging Position Storage Status : Position Update Location";
BA_ "SignalType" SG_ 317 LBCPSS_PosUpdtLct "ENM";
BA_ "GenSigSendType" SG_ 317 LBCPSS_PosUpdtLct 1;
BA_ "SignalLongName" SG_ 317 LBCCF_Lct1PosStrdIO "Location Based Charging Customer Feedback : Location 1 Position Stored Indication On";
BA_ "SignalType" SG_ 317 LBCCF_Lct1PosStrdIO "BLN";
BA_ "GenSigSendType" SG_ 317 LBCCF_Lct1PosStrdIO 1;
BA_ "SignalLongName" SG_ 317 LBCCF_Lct2PosStrdIO "Location Based Charging Customer Feedback : Location 2 Position Stored Indication On";
BA_ "SignalType" SG_ 317 LBCCF_Lct2PosStrdIO "BLN";
BA_ "GenSigSendType" SG_ 317 LBCCF_Lct2PosStrdIO 1;
BA_ "SignalLongName" SG_ 317 LBCCF_Lct3PosStrdIO "Location Based Charging Customer Feedback : Location 3 Position Stored Indication On";
BA_ "SignalType" SG_ 317 LBCCF_Lct3PosStrdIO "BLN";
BA_ "GenSigSendType" SG_ 317 LBCCF_Lct3PosStrdIO 1;
BA_ "SignalLongName" SG_ 317 LBCCF_Lct4PosStrdIO "Location Based Charging Customer Feedback : Location 4 Position Stored Indication On";
BA_ "SignalType" SG_ 317 LBCCF_Lct4PosStrdIO "BLN";
BA_ "GenSigSendType" SG_ 317 LBCCF_Lct4PosStrdIO 1;
BA_ "SignalLongName" SG_ 317 LBCVLS_VehGPSLctV "Location Based Charging Vehicle Location Status : Vehicle GPS Location Validity";
BA_ "SignalType" SG_ 317 LBCVLS_VehGPSLctV "ENM";
BA_ "GenSigSendType" SG_ 317 LBCVLS_VehGPSLctV 1;
BA_ "SignalLongName" SG_ 317 LBCVLS_VehGPSLct "Location Based Charging Vehicle Location Status : Vehicle GPS Location";
BA_ "SignalType" SG_ 317 LBCVLS_VehGPSLct "ENM";
BA_ "GenSigSendType" SG_ 317 LBCVLS_VehGPSLct 1;
BA_ "SignalLongName" SG_ 317 ChrgCyclElecEngyEcnEq "Charge Cycle Electrical Energy Economy Equivalent";
BA_ "SignalType" SG_ 317 ChrgCyclElecEngyEcnEq "UNM";
BA_ "GenSigDeltaValue" SG_ 317 ChrgCyclElecEngyEcnEq 1;
BA_ "GenSigSendType" SG_ 317 ChrgCyclElecEngyEcnEq 1;
BA_ "GenSigSendOnInit" SG_ 317 ChrgCyclElecEngyEcnEq 1;
BA_ "SignalLongName" SG_ 317 ChrgCyclOvrlEngyEcnEq "Charge Cycle Overall Energy Economy Equivalent";
BA_ "SignalType" SG_ 317 ChrgCyclOvrlEngyEcnEq "UNM";
BA_ "GenSigDeltaValue" SG_ 317 ChrgCyclOvrlEngyEcnEq 1;
BA_ "GenSigSendType" SG_ 317 ChrgCyclOvrlEngyEcnEq 1;
BA_ "GenSigSendOnInit" SG_ 317 ChrgCyclOvrlEngyEcnEq 1;
BA_ "SignalLongName" SG_ 326 EngyStgSysActCoolEnb "Energy Storage System Active Cooling Enabled";
BA_ "SignalType" SG_ 326 EngyStgSysActCoolEnb "BLN";
BA_ "GenSigSendType" SG_ 326 EngyStgSysActCoolEnb 1;
BA_ "GenSigSendOnInit" SG_ 326 EngyStgSysActCoolEnb 1;
BA_ "SignalLongName" SG_ 326 DrvCycElEnrgUsd "Drive Cycle Electrical Energy Used";
BA_ "SignalType" SG_ 326 DrvCycElEnrgUsd "UNM";
BA_ "GenSigDeltaValue" SG_ 326 DrvCycElEnrgUsd 1;
BA_ "GenSigSendType" SG_ 326 DrvCycElEnrgUsd 1;
BA_ "GenSigSendOnInit" SG_ 326 DrvCycElEnrgUsd 1;
BA_ "SignalLongName" SG_ 326 HVChrgInhbRsn "High Voltage Charging Inhibit Reason";
BA_ "SignalType" SG_ 326 HVChrgInhbRsn "ENM";
BA_ "GenSigSendType" SG_ 326 HVChrgInhbRsn 1;
BA_ "SignalLongName" SG_ 326 DrvCyclElecEngyEcon "Drive Cycle Electrical Energy Economy";
BA_ "SignalType" SG_ 326 DrvCyclElecEngyEcon "UNM";
BA_ "GenSigDeltaValue" SG_ 326 DrvCyclElecEngyEcon 1;
BA_ "GenSigSendType" SG_ 326 DrvCyclElecEngyEcon 1;
BA_ "SignalLongName" SG_ 326 DrvCyclTrpDstTrvld "Drive Cycle Trip Distance Traveled";
BA_ "SignalType" SG_ 326 DrvCyclTrpDstTrvld "UNM";
BA_ "GenSigDeltaValue" SG_ 326 DrvCyclTrpDstTrvld 1;
BA_ "GenSigSendType" SG_ 326 DrvCyclTrpDstTrvld 1;
BA_ "SignalLongName" SG_ 794 PwrElecCoolLpTempM "Power Electronics Cooling Loop Temperature Mask";
BA_ "SignalType" SG_ 794 PwrElecCoolLpTempM "ENM";
BA_ "GenSigSendType" SG_ 794 PwrElecCoolLpTempM 1;
BA_ "GenSigSendOnInit" SG_ 794 PwrElecCoolLpTempM 1;
BA_ "SignalLongName" SG_ 794 PwrElecCoolLpTempV "Power Electronics Cooling Loop Temperature Validity";
BA_ "SignalType" SG_ 794 PwrElecCoolLpTempV "ENM";
BA_ "GenSigSendType" SG_ 794 PwrElecCoolLpTempV 1;
BA_ "GenSigSendOnInit" SG_ 794 PwrElecCoolLpTempV 1;
BA_ "SignalLongName" SG_ 794 PwrElecCoolLpTemp "Power Electronics Cooling Loop Temperature";
BA_ "SignalType" SG_ 794 PwrElecCoolLpTemp "UNM";
BA_ "GenSigDeltaValue" SG_ 794 PwrElecCoolLpTemp 1;
BA_ "GenSigSendType" SG_ 794 PwrElecCoolLpTemp 1;
BA_ "GenSigSendOnInit" SG_ 794 PwrElecCoolLpTemp 1;
BA_ "SignalLongName" SG_ 794 EUS_TcEngyUsgScrAvVal "Energy Usage Score : Technique Energy Usage Score Average Value";
BA_ "SignalType" SG_ 794 EUS_TcEngyUsgScrAvVal "SNM";
BA_ "GenSigDeltaValue" SG_ 794 EUS_TcEngyUsgScrAvVal 1;
BA_ "GenSigSendType" SG_ 794 EUS_TcEngyUsgScrAvVal 1;
BA_ "SignalLongName" SG_ 794 EUS_TrEngyUsgScrAvVal "Energy Usage Score : Terrain Energy Usage Score Average Value";
BA_ "SignalType" SG_ 794 EUS_TrEngyUsgScrAvVal "SNM";
BA_ "GenSigDeltaValue" SG_ 794 EUS_TrEngyUsgScrAvVal 1;
BA_ "GenSigSendType" SG_ 794 EUS_TrEngyUsgScrAvVal 1;
BA_ "SignalLongName" SG_ 794 EUS_OTEngyUsgScrAvVal "Energy Usage Score : Outside Temperature Energy Usage Score Average Value";
BA_ "SignalType" SG_ 794 EUS_OTEngyUsgScrAvVal "SNM";
BA_ "GenSigDeltaValue" SG_ 794 EUS_OTEngyUsgScrAvVal 1;
BA_ "GenSigSendType" SG_ 794 EUS_OTEngyUsgScrAvVal 1;
BA_ "SignalLongName" SG_ 794 EUS_ITEngyUsgScrAvVal "Energy Usage Score : Inside Temperature Energy Usage Score Average Value";
BA_ "SignalType" SG_ 794 EUS_ITEngyUsgScrAvVal "SNM";
BA_ "GenSigDeltaValue" SG_ 794 EUS_ITEngyUsgScrAvVal 1;
BA_ "GenSigSendType" SG_ 794 EUS_ITEngyUsgScrAvVal 1;
BA_ "SignalLongName" SG_ 794 EUS_TtEngyUsgScrAvVal "Energy Usage Score : Total Energy Usage Score Value";
BA_ "SignalType" SG_ 794 EUS_TtEngyUsgScrAvVal "SNM";
BA_ "GenSigDeltaValue" SG_ 794 EUS_TtEngyUsgScrAvVal 1;
BA_ "GenSigSendType" SG_ 794 EUS_TtEngyUsgScrAvVal 1;
BA_ "SignalLongName" SG_ 1575 SrcNodeID "Source Node Identifier";
BA_ "SignalType" SG_ 1575 SrcNodeID "UNM";
BA_ "SignalLongName" SG_ 1575 UDat "User Data";
BA_ "SignalType" SG_ 1575 UDat "UNM";
BA_ "SignalLongName" SG_ 1587 SrcNodeID "Source Node Identifier";
BA_ "SignalType" SG_ 1587 SrcNodeID "UNM";
BA_ "SignalLongName" SG_ 1587 UDat "User Data";
BA_ "SignalType" SG_ 1587 UDat "UNM";
BA_ "SignalLongName" SG_ 1588 SrcNodeID "Source Node Identifier";
BA_ "SignalType" SG_ 1588 SrcNodeID "UNM";
BA_ "SignalLongName" SG_ 1588 UDat "User Data";
BA_ "SignalType" SG_ 1588 UDat "UNM";
BA_ "SignalLongName" SG_ 299 DDAjrSwAtvMac "Driver Door Ajar Switch Active";
BA_ "SignalType" SG_ 299 DDAjrSwAtvMac "BLN";
BA_ "SignalLongName" SG_ 299 DDAjrSwAtvMMac "Driver Door Ajar Switch Active Mask";
BA_ "SignalType" SG_ 299 DDAjrSwAtvMMac "ENM";
BA_ "SignalLongName" SG_ 299 DrIdMac "Driver Identifier";
BA_ "SignalType" SG_ 299 DrIdMac "ENM";
BA_ "GenSigStartValue" SG_ 299 DrIdMac 7;
BA_ "SignalLongName" SG_ 299 PDAjrSwAtvMac "Passenger Door Ajar Switch Active";
BA_ "SignalType" SG_ 299 PDAjrSwAtvMac "BLN";
BA_ "SignalLongName" SG_ 299 RLDoorAjarSwActMac "Rear Left Door Ajar Switch Active";
BA_ "SignalType" SG_ 299 RLDoorAjarSwActMac "BLN";
BA_ "SignalLongName" SG_ 299 RRDoorAjarSwActMac "Rear Right Door Ajar Switch Active";
BA_ "SignalType" SG_ 299 RRDoorAjarSwActMac "BLN";
BA_ "SignalLongName" SG_ 299 VhSecNImmoIndRqMac "Vehicle Security Non Immobilizer Indication Request";
BA_ "SignalType" SG_ 299 VhSecNImmoIndRqMac "ENM";
BA_ "SignalLongName" SG_ 299 RrClosAjarSwActMac "Rear Closure Ajar Switch Active";
BA_ "SignalType" SG_ 299 RrClosAjarSwActMac "BLN";
BA_ "SignalLongName" SG_ 299 TCSysDisSwAtvMac "Traction Control System Disable Switch Active";
BA_ "SignalType" SG_ 299 TCSysDisSwAtvMac "BLN";
BA_ "SignalLongName" SG_ 299 TCSysDisSwAtvVMac "Traction Control System Disable Switch Active Validity";
BA_ "SignalType" SG_ 299 TCSysDisSwAtvVMac "ENM";
BA_ "SignalLongName" SG_ 299 VehMovStateMac "Vehicle Movement State";
BA_ "SignalType" SG_ 299 VehMovStateMac "ENM";
BA_ "SignalLongName" SG_ 299 WSWshSwAtvMac "Windshield Washer Switch Active";
BA_ "SignalType" SG_ 299 WSWshSwAtvMac "BLN";
BA_ "SignalLongName" SG_ 299 RrClsrSnwLdIOMac "Rear Closure Snow Load Indication On";
BA_ "SignalType" SG_ 299 RrClsrSnwLdIOMac "BLN";
BA_ "GenSigSendType" SG_ 299 RrClsrSnwLdIOMac 1;
BA_ "SignalLongName" SG_ 299 WSWprActMac "Windshield Wiper Active";
BA_ "SignalType" SG_ 299 WSWprActMac "BLN";
BA_ "SignalLongName" SG_ 299 HdStMac "Hood Status";
BA_ "SignalType" SG_ 299 HdStMac "ENM";
BA_ "GenSigSendType" SG_ 299 HdStMac 1;
BA_ "GenSigSendOnInit" SG_ 299 HdStMac 1;
BA_ "SignalLongName" SG_ 299 HdStVMac "Hood Status Validity";
BA_ "SignalType" SG_ 299 HdStVMac "ENM";
BA_ "GenSigSendType" SG_ 299 HdStVMac 1;
BA_ "SignalLongName" SG_ 498 PrkBrkSwAtvMac "Park Brake Switch Active";
BA_ "SignalType" SG_ 498 PrkBrkSwAtvMac "BLN";
BA_ "GenSigSendType" SG_ 498 PrkBrkSwAtvMac 1;
BA_ "SignalLongName" SG_ 498 TrStLgMdAtvMac "Transport Storage Logistic Mode Active";
BA_ "SignalType" SG_ 498 TrStLgMdAtvMac "BLN";
BA_ "GenSigSendType" SG_ 498 TrStLgMdAtvMac 1;
BA_ "SignalLongName" SG_ 498 ThrtlPrgrsnReqMac "Throttle Progression Request";
BA_ "SignalType" SG_ 498 ThrtlPrgrsnReqMac "ENM";
BA_ "GenSigSendType" SG_ 498 ThrtlPrgrsnReqMac 1;
BA_ "SignalLongName" SG_ 202 CrsCntAtvMac "Cruise Control Active";
BA_ "SignalType" SG_ 202 CrsCntAtvMac "BLN";
BA_ "SignalLongName" SG_ 202 CrsCntEnbldMac "Cruise Control Enabled";
BA_ "SignalType" SG_ 202 CrsCntEnbldMac "BLN";
BA_ "SignalLongName" SG_ 202 Eng12vStrtrMtrCmmdOnMac "Engine 12 Volt Starter Motor Commanded On";
BA_ "SignalType" SG_ 202 Eng12vStrtrMtrCmmdOnMac "BLN";
BA_ "SignalLongName" SG_ 202 EngIdlAtvMac "Engine Idle Active";
BA_ "SignalType" SG_ 202 EngIdlAtvMac "BLN";
BA_ "SignalLongName" SG_ 202 EngAirIntBstPrMac "Engine Intake Air Boost Pressure";
BA_ "SignalType" SG_ 202 EngAirIntBstPrMac "SNM";
BA_ "SignalLongName" SG_ 202 EngAirIntBstPrVMac "Engine Intake Air Boost Pressure Validity";
BA_ "SignalType" SG_ 202 EngAirIntBstPrVMac "ENM";
BA_ "SignalLongName" SG_ 202 EngRunAtvMac "Engine Run Active";
BA_ "SignalType" SG_ 202 EngRunAtvMac "BLN";
BA_ "SignalLongName" SG_ 202 PT_BrkPedDscrtInpStatMac "Powertrain Brake Pedal Discrete Input Status";
BA_ "SignalType" SG_ 202 PT_BrkPedDscrtInpStatMac "ENM";
BA_ "SignalLongName" SG_ 202 PT_BrkPedDscrtInpStatVMac "Powertrain Brake Pedal Discrete Input Status Validity";
BA_ "SignalType" SG_ 202 PT_BrkPedDscrtInpStatVMac "ENM";
BA_ "SignalLongName" SG_ 202 PTCrnkAbrtedMac "Powertrain Crank Aborted";
BA_ "SignalType" SG_ 202 PTCrnkAbrtedMac "BLN";
BA_ "SignalLongName" SG_ 202 PTRunAbrtMac "Powertrain Run Aborted";
BA_ "SignalType" SG_ 202 PTRunAbrtMac "BLN";
BA_ "SignalLongName" SG_ 202 RmVhStrtEngRngMac "Remote Vehicle Start Engine Running";
BA_ "SignalType" SG_ 202 RmVhStrtEngRngMac "BLN";
BA_ "SignalLongName" SG_ 202 SpdLmtrSpdWrngEnbldMac "Speed Limiter/Speed Warning Enabled";
BA_ "SignalType" SG_ 202 SpdLmtrSpdWrngEnbldMac "BLN";
BA_REL_ "GenSigTimeoutMsg" BU_SG_REL_ ECC_PB SG_ 881 ASSAudSrcType 881;
BA_REL_ "GenSigSuprvResp" BU_SG_REL_ ECC_PB SG_ 881 ASSAudSrcType 1;
BA_REL_ "GenSigTimeoutTime" BU_SG_REL_ ECC_PB SG_ 881 ASSAudSrcType 3000;
BA_REL_ "GenSigTimeoutMsg" BU_SG_REL_ ECC_PB SG_ 948 RLHCSMIndReq 948;
BA_REL_ "GenSigSuprvResp" BU_SG_REL_ ECC_PB SG_ 948 RLHCSMIndReq 1;
BA_REL_ "GenSigTimeoutTime" BU_SG_REL_ ECC_PB SG_ 948 RLHCSMIndReq 3000;
BA_REL_ "GenSigTimeoutMsg" BU_SG_REL_ ECC_PB SG_ 948 RLHCSMInd1 948;
BA_REL_ "GenSigSuprvResp" BU_SG_REL_ ECC_PB SG_ 948 RLHCSMInd1 1;
BA_REL_ "GenSigTimeoutTime" BU_SG_REL_ ECC_PB SG_ 948 RLHCSMInd1 3000;
BA_REL_ "GenSigTimeoutMsg" BU_SG_REL_ ECC_PB SG_ 948 RLHCSMInd2 948;
BA_REL_ "GenSigSuprvResp" BU_SG_REL_ ECC_PB SG_ 948 RLHCSMInd2 1;
BA_REL_ "GenSigTimeoutTime" BU_SG_REL_ ECC_PB SG_ 948 RLHCSMInd2 3000;
BA_REL_ "GenSigTimeoutMsg" BU_SG_REL_ ECC_PB SG_ 948 RLHCSMInd3 948;
BA_REL_ "GenSigSuprvResp" BU_SG_REL_ ECC_PB SG_ 948 RLHCSMInd3 1;
BA_REL_ "GenSigTimeoutTime" BU_SG_REL_ ECC_PB SG_ 948 RLHCSMInd3 3000;
BA_REL_ "GenSigTimeoutMsg" BU_SG_REL_ ECC_PB SG_ 948 RRHCSMIndReq 948;
BA_REL_ "GenSigSuprvResp" BU_SG_REL_ ECC_PB SG_ 948 RRHCSMIndReq 1;
BA_REL_ "GenSigTimeoutTime" BU_SG_REL_ ECC_PB SG_ 948 RRHCSMIndReq 3000;
BA_REL_ "GenSigTimeoutMsg" BU_SG_REL_ ECC_PB SG_ 948 RRHCSMInd1 948;
BA_REL_ "GenSigSuprvResp" BU_SG_REL_ ECC_PB SG_ 948 RRHCSMInd1 1;
BA_REL_ "GenSigTimeoutTime" BU_SG_REL_ ECC_PB SG_ 948 RRHCSMInd1 3000;
BA_REL_ "GenSigTimeoutMsg" BU_SG_REL_ ECC_PB SG_ 948 RRHCSMInd2 948;
BA_REL_ "GenSigSuprvResp" BU_SG_REL_ ECC_PB SG_ 948 RRHCSMInd2 1;
BA_REL_ "GenSigTimeoutTime" BU_SG_REL_ ECC_PB SG_ 948 RRHCSMInd2 3000;
BA_REL_ "GenSigTimeoutMsg" BU_SG_REL_ ECC_PB SG_ 948 RRHCSMInd3 948;
BA_REL_ "GenSigSuprvResp" BU_SG_REL_ ECC_PB SG_ 948 RRHCSMInd3 1;
BA_REL_ "GenSigTimeoutTime" BU_SG_REL_ ECC_PB SG_ 948 RRHCSMInd3 3000;
BA_REL_ "GenSigTimeoutMsg" BU_SG_REL_ ECC_PB SG_ 948 RLHCSLIndReq 948;
BA_REL_ "GenSigSuprvResp" BU_SG_REL_ ECC_PB SG_ 948 RLHCSLIndReq 1;
BA_REL_ "GenSigTimeoutTime" BU_SG_REL_ ECC_PB SG_ 948 RLHCSLIndReq 3000;
BA_REL_ "GenSigTimeoutMsg" BU_SG_REL_ ECC_PB SG_ 948 RLHCSLSeatLev1 948;
BA_REL_ "GenSigSuprvResp" BU_SG_REL_ ECC_PB SG_ 948 RLHCSLSeatLev1 1;
BA_REL_ "GenSigTimeoutTime" BU_SG_REL_ ECC_PB SG_ 948 RLHCSLSeatLev1 3000;
BA_REL_ "GenSigTimeoutMsg" BU_SG_REL_ ECC_PB SG_ 948 RLHCSLSeatLev2 948;
BA_REL_ "GenSigSuprvResp" BU_SG_REL_ ECC_PB SG_ 948 RLHCSLSeatLev2 1;
BA_REL_ "GenSigTimeoutTime" BU_SG_REL_ ECC_PB SG_ 948 RLHCSLSeatLev2 3000;
BA_REL_ "GenSigTimeoutMsg" BU_SG_REL_ ECC_PB SG_ 948 RLHCSLSeatLev3 948;
BA_REL_ "GenSigSuprvResp" BU_SG_REL_ ECC_PB SG_ 948 RLHCSLSeatLev3 1;
BA_REL_ "GenSigTimeoutTime" BU_SG_REL_ ECC_PB SG_ 948 RLHCSLSeatLev3 3000;
BA_REL_ "GenSigTimeoutMsg" BU_SG_REL_ ECC_PB SG_ 948 RLHCSLSeatLev4 948;
BA_REL_ "GenSigSuprvResp" BU_SG_REL_ ECC_PB SG_ 948 RLHCSLSeatLev4 1;
BA_REL_ "GenSigTimeoutTime" BU_SG_REL_ ECC_PB SG_ 948 RLHCSLSeatLev4 3000;
BA_REL_ "GenSigTimeoutMsg" BU_SG_REL_ ECC_PB SG_ 948 RLHCSLSeatLev5 948;
BA_REL_ "GenSigSuprvResp" BU_SG_REL_ ECC_PB SG_ 948 RLHCSLSeatLev5 1;
BA_REL_ "GenSigTimeoutTime" BU_SG_REL_ ECC_PB SG_ 948 RLHCSLSeatLev5 3000;
BA_REL_ "GenSigTimeoutMsg" BU_SG_REL_ ECC_PB SG_ 948 RRHCSLIndReq 948;
BA_REL_ "GenSigSuprvResp" BU_SG_REL_ ECC_PB SG_ 948 RRHCSLIndReq 1;
BA_REL_ "GenSigTimeoutTime" BU_SG_REL_ ECC_PB SG_ 948 RRHCSLIndReq 3000;
BA_REL_ "GenSigTimeoutMsg" BU_SG_REL_ ECC_PB SG_ 948 RRHCSLSeatLev1 948;
BA_REL_ "GenSigSuprvResp" BU_SG_REL_ ECC_PB SG_ 948 RRHCSLSeatLev1 1;
BA_REL_ "GenSigTimeoutTime" BU_SG_REL_ ECC_PB SG_ 948 RRHCSLSeatLev1 3000;
BA_REL_ "GenSigTimeoutMsg" BU_SG_REL_ ECC_PB SG_ 948 RRHCSLSeatLev2 948;
BA_REL_ "GenSigSuprvResp" BU_SG_REL_ ECC_PB SG_ 948 RRHCSLSeatLev2 1;
BA_REL_ "GenSigTimeoutTime" BU_SG_REL_ ECC_PB SG_ 948 RRHCSLSeatLev2 3000;
BA_REL_ "GenSigTimeoutMsg" BU_SG_REL_ ECC_PB SG_ 948 RRHCSLSeatLev3 948;
BA_REL_ "GenSigSuprvResp" BU_SG_REL_ ECC_PB SG_ 948 RRHCSLSeatLev3 1;
BA_REL_ "GenSigTimeoutTime" BU_SG_REL_ ECC_PB SG_ 948 RRHCSLSeatLev3 3000;
BA_REL_ "GenSigTimeoutMsg" BU_SG_REL_ ECC_PB SG_ 948 RRHCSLSeatLev4 948;
BA_REL_ "GenSigSuprvResp" BU_SG_REL_ ECC_PB SG_ 948 RRHCSLSeatLev4 1;
BA_REL_ "GenSigTimeoutTime" BU_SG_REL_ ECC_PB SG_ 948 RRHCSLSeatLev4 3000;
BA_REL_ "GenSigTimeoutMsg" BU_SG_REL_ ECC_PB SG_ 948 RRHCSLSeatLev5 948;
BA_REL_ "GenSigSuprvResp" BU_SG_REL_ ECC_PB SG_ 948 RRHCSLSeatLev5 1;
BA_REL_ "GenSigTimeoutTime" BU_SG_REL_ ECC_PB SG_ 948 RRHCSLSeatLev5 3000;
BA_REL_ "GenSigTimeoutMsg" BU_SG_REL_ ECC_PB SG_ 502 SysPwrMdMac 502;
BA_REL_ "GenSigSuprvResp" BU_SG_REL_ ECC_PB SG_ 502 SysPwrMdMac 1;
BA_REL_ "GenSigTimeoutTime" BU_SG_REL_ ECC_PB SG_ 502 SysPwrMdMac 3000;
BA_REL_ "GenSigVBitResp" BU_SG_REL_ ECC_PB SG_ 502 SysPwrMdMac 1;
BA_REL_ "GenSigVBitRespComment" BU_SG_REL_ ECC_PB SG_ 502 SysPwrMdMac "SysPwrMdV";
BA_REL_ "GenSigRxStartValue" BU_SG_REL_ ECC_PB SG_ 502 SysPwrMdVMac "1";
BA_REL_ "GenSigTimeoutMsg" BU_SG_REL_ ECC_PB SG_ 502 RemStrtStMac 502;
BA_REL_ "GenSigSuprvResp" BU_SG_REL_ ECC_PB SG_ 502 RemStrtStMac 1;
BA_REL_ "GenSigTimeoutTime" BU_SG_REL_ ECC_PB SG_ 502 RemStrtStMac 3000;
BA_REL_ "GenSigTimeoutMsg" BU_SG_REL_ ECC_PB SG_ 291 SysBkUpPwrMdMac 291;
BA_REL_ "GenSigSuprvResp" BU_SG_REL_ ECC_PB SG_ 291 SysBkUpPwrMdMac 1;
BA_REL_ "GenSigTimeoutTime" BU_SG_REL_ ECC_PB SG_ 291 SysBkUpPwrMdMac 3000;
BA_REL_ "GenSigVBitResp" BU_SG_REL_ ECC_PB SG_ 291 SysBkUpPwrMdMac 1;
BA_REL_ "GenSigVBitRespComment" BU_SG_REL_ ECC_PB SG_ 291 SysBkUpPwrMdMac "SysBkUpPwrMdV";
BA_REL_ "GenSigRxStartValue" BU_SG_REL_ ECC_PB SG_ 291 SysBkupPwrMdEnMac "0";
BA_REL_ "GenSigTimeoutMsg" BU_SG_REL_ ECC_PB SG_ 291 SysBkupPwrMdEnMac 291;
BA_REL_ "GenSigSuprvResp" BU_SG_REL_ ECC_PB SG_ 291 SysBkupPwrMdEnMac 1;
BA_REL_ "GenSigTimeoutTime" BU_SG_REL_ ECC_PB SG_ 291 SysBkupPwrMdEnMac 3000;
BA_REL_ "GenSigRxStartValue" BU_SG_REL_ ECC_PB SG_ 291 SysBkUpPwrMdVMac "1";
BA_REL_ "GenSigRxStartValue" BU_SG_REL_ Firewall_PB SG_ 1630 AirQltySnsCstCrStVal "0";
BA_REL_ "GenSigRxStartValue" BU_SG_REL_ Firewall_PB SG_ 1630 AirQltySnsCstStAvl "0";
BA_REL_ "GenSigRxStartValue" BU_SG_REL_ Firewall_PB SG_ 1630 AirQltySnsCstAvlFlg1 "0";
BA_REL_ "GenSigRxStartValue" BU_SG_REL_ Firewall_PB SG_ 1630 AirQltySnsCstAvlFlg2 "0";
BA_REL_ "GenSigRxStartValue" BU_SG_REL_ Firewall_PB SG_ 1630 AirQltySnsCstAvlFlg3 "0";
BA_REL_ "GenSigRxStartValue" BU_SG_REL_ Firewall_PB SG_ 1630 AirQltySnsCstAvlFlg4 "0";
BA_REL_ "GenSigRxStartValue" BU_SG_REL_ Firewall_PB SG_ 1630 AirQltySnsCstAvlFlg5 "0";
BA_REL_ "GenSigRxStartValue" BU_SG_REL_ Firewall_PB SG_ 1630 AirQltySnsCstAvlFlg6 "0";
BA_REL_ "GenSigRxStartValue" BU_SG_REL_ Firewall_PB SG_ 1630 AirQltySnsCstAvlFlg7 "0";
BA_REL_ "GenSigRxStartValue" BU_SG_REL_ Firewall_PB SG_ 1630 IonzrCtrlCstCrStVal "0";
BA_REL_ "GenSigRxStartValue" BU_SG_REL_ Firewall_PB SG_ 1630 IonzrCtrlCstStAvl "0";
BA_REL_ "GenSigRxStartValue" BU_SG_REL_ Firewall_PB SG_ 1630 IonzrCtrlCstAvlFlg1 "0";
BA_REL_ "GenSigRxStartValue" BU_SG_REL_ Firewall_PB SG_ 1630 IonzrCtrlCstAvlFlg2 "0";
BA_REL_ "GenSigRxStartValue" BU_SG_REL_ Firewall_PB SG_ 1630 IonzrCtrlCstAvlFlg3 "0";
BA_REL_ "GenSigRxStartValue" BU_SG_REL_ Firewall_PB SG_ 1630 IonzrCtrlCstAvlFlg4 "0";
BA_REL_ "GenSigRxStartValue" BU_SG_REL_ Firewall_PB SG_ 1630 IonzrCtrlCstAvlFlg5 "0";
BA_REL_ "GenSigRxStartValue" BU_SG_REL_ Firewall_PB SG_ 1630 IonzrCtrlCstAvlFlg6 "0";
BA_REL_ "GenSigRxStartValue" BU_SG_REL_ Firewall_PB SG_ 1630 IonzrCtrlCstAvlFlg7 "0";
BA_REL_ "GenSigRxStartValue" BU_SG_REL_ Firewall_PB SG_ 1630 AutoDfgCstCrStVal "0";
BA_REL_ "GenSigRxStartValue" BU_SG_REL_ Firewall_PB SG_ 1630 AutoDfgCstStAvl "0";
BA_REL_ "GenSigRxStartValue" BU_SG_REL_ Firewall_PB SG_ 1630 AutoDfgCstAvlFlg1 "0";
BA_REL_ "GenSigRxStartValue" BU_SG_REL_ Firewall_PB SG_ 1630 AutoDfgCstAvlFlg2 "0";
BA_REL_ "GenSigRxStartValue" BU_SG_REL_ Firewall_PB SG_ 1630 AutoDfgCstAvlFlg3 "0";
BA_REL_ "GenSigRxStartValue" BU_SG_REL_ Firewall_PB SG_ 1630 AutoDfgCstAvlFlg4 "0";
BA_REL_ "GenSigRxStartValue" BU_SG_REL_ Firewall_PB SG_ 1630 AutoDfgCstAvlFlg5 "0";
BA_REL_ "GenSigRxStartValue" BU_SG_REL_ Firewall_PB SG_ 1630 AutoDfgCstAvlFlg6 "0";
BA_REL_ "GenSigRxStartValue" BU_SG_REL_ Firewall_PB SG_ 1630 AutoDfgCstAvlFlg7 "0";
BA_REL_ "GenSigRxStartValue" BU_SG_REL_ Firewall_PB SG_ 1630 AutoFanCstCrStVal "0";
BA_REL_ "GenSigRxStartValue" BU_SG_REL_ Firewall_PB SG_ 1630 AutoFanCstStAvl "0";
BA_REL_ "GenSigRxStartValue" BU_SG_REL_ Firewall_PB SG_ 1630 AutoFanCstAvlFlg1 "0";
BA_REL_ "GenSigRxStartValue" BU_SG_REL_ Firewall_PB SG_ 1630 AutoFanCstAvlFlg2 "0";
BA_REL_ "GenSigRxStartValue" BU_SG_REL_ Firewall_PB SG_ 1630 AutoFanCstAvlFlg3 "0";
BA_REL_ "GenSigRxStartValue" BU_SG_REL_ Firewall_PB SG_ 1630 AutoFanCstAvlFlg4 "0";
BA_REL_ "GenSigRxStartValue" BU_SG_REL_ Firewall_PB SG_ 1630 AutoFanCstAvlFlg5 "0";
BA_REL_ "GenSigRxStartValue" BU_SG_REL_ Firewall_PB SG_ 1630 AutoFanCstAvlFlg6 "0";
BA_REL_ "GenSigRxStartValue" BU_SG_REL_ Firewall_PB SG_ 1630 AutoFanCstAvlFlg7 "0";
BA_REL_ "GenSigRxStartValue" BU_SG_REL_ Firewall_PB SG_ 1638 RrDfgStUpCstCrStVal "0";
BA_REL_ "GenSigRxStartValue" BU_SG_REL_ Firewall_PB SG_ 1638 RrDfgStUpCstStAvl "0";
BA_REL_ "GenSigRxStartValue" BU_SG_REL_ Firewall_PB SG_ 1638 RrDfgStUpCstAvlFlg1 "0";
BA_REL_ "GenSigRxStartValue" BU_SG_REL_ Firewall_PB SG_ 1638 RrDfgStUpCstAvlFlg2 "0";
BA_REL_ "GenSigRxStartValue" BU_SG_REL_ Firewall_PB SG_ 1638 RrDfgStUpCstAvlFlg3 "0";
BA_REL_ "GenSigRxStartValue" BU_SG_REL_ Firewall_PB SG_ 1638 RrDfgStUpCstAvlFlg4 "0";
BA_REL_ "GenSigRxStartValue" BU_SG_REL_ Firewall_PB SG_ 1638 RrDfgStUpCstAvlFlg5 "0";
BA_REL_ "GenSigRxStartValue" BU_SG_REL_ Firewall_PB SG_ 1638 RrDfgStUpCstAvlFlg6 "0";
BA_REL_ "GenSigRxStartValue" BU_SG_REL_ Firewall_PB SG_ 1638 RrDfgStUpCstAvlFlg7 "0";
BA_REL_ "GenSigRxStartValue" BU_SG_REL_ Firewall_PB SG_ 1638 RrZnStUpCstCrStVal "0";
BA_REL_ "GenSigRxStartValue" BU_SG_REL_ Firewall_PB SG_ 1638 RrZnStUpCstStAvl "0";
BA_REL_ "GenSigRxStartValue" BU_SG_REL_ Firewall_PB SG_ 1638 RrZnStUpCstAvlFlg1 "0";
BA_REL_ "GenSigRxStartValue" BU_SG_REL_ Firewall_PB SG_ 1638 RrZnStUpCstAvlFlg2 "0";
BA_REL_ "GenSigRxStartValue" BU_SG_REL_ Firewall_PB SG_ 1638 RrZnStUpCstAvlFlg3 "0";
BA_REL_ "GenSigRxStartValue" BU_SG_REL_ Firewall_PB SG_ 1638 RrZnStUpCstAvlFlg4 "0";
BA_REL_ "GenSigRxStartValue" BU_SG_REL_ Firewall_PB SG_ 1638 RrZnStUpCstAvlFlg5 "0";
BA_REL_ "GenSigRxStartValue" BU_SG_REL_ Firewall_PB SG_ 1638 RrZnStUpCstAvlFlg6 "0";
BA_REL_ "GenSigRxStartValue" BU_SG_REL_ Firewall_PB SG_ 1638 RrZnStUpCstAvlFlg7 "0";
BA_REL_ "GenSigRxStartValue" BU_SG_REL_ Firewall_PB SG_ 1638 AutoCoolStCstCrStVal "0";
BA_REL_ "GenSigRxStartValue" BU_SG_REL_ Firewall_PB SG_ 1638 AutoCoolStCstStAvl "0";
BA_REL_ "GenSigRxStartValue" BU_SG_REL_ Firewall_PB SG_ 1638 AutoCoolStCstAvlFlg1 "0";
BA_REL_ "GenSigRxStartValue" BU_SG_REL_ Firewall_PB SG_ 1638 AutoCoolStCstAvlFlg2 "0";
BA_REL_ "GenSigRxStartValue" BU_SG_REL_ Firewall_PB SG_ 1638 AutoCoolStCstAvlFlg3 "0";
BA_REL_ "GenSigRxStartValue" BU_SG_REL_ Firewall_PB SG_ 1638 AutoCoolStCstAvlFlg4 "0";
BA_REL_ "GenSigRxStartValue" BU_SG_REL_ Firewall_PB SG_ 1638 AutoCoolStCstAvlFlg5 "0";
BA_REL_ "GenSigRxStartValue" BU_SG_REL_ Firewall_PB SG_ 1638 AutoCoolStCstAvlFlg6 "0";
BA_REL_ "GenSigRxStartValue" BU_SG_REL_ Firewall_PB SG_ 1638 AutoCoolStCstAvlFlg7 "0";
BA_REL_ "GenSigRxStartValue" BU_SG_REL_ Firewall_PB SG_ 1638 AutoHtdStCstCrStVal "0";
BA_REL_ "GenSigRxStartValue" BU_SG_REL_ Firewall_PB SG_ 1638 AutoHtdStCstStAvl "0";
BA_REL_ "GenSigRxStartValue" BU_SG_REL_ Firewall_PB SG_ 1638 AutoHtdStCstAvlFlg1 "0";
BA_REL_ "GenSigRxStartValue" BU_SG_REL_ Firewall_PB SG_ 1638 AutoHtdStCstAvlFlg2 "0";
BA_REL_ "GenSigRxStartValue" BU_SG_REL_ Firewall_PB SG_ 1638 AutoHtdStCstAvlFlg3 "0";
BA_REL_ "GenSigRxStartValue" BU_SG_REL_ Firewall_PB SG_ 1638 AutoHtdStCstAvlFlg4 "0";
BA_REL_ "GenSigRxStartValue" BU_SG_REL_ Firewall_PB SG_ 1638 AutoHtdStCstAvlFlg5 "0";
BA_REL_ "GenSigRxStartValue" BU_SG_REL_ Firewall_PB SG_ 1638 AutoHtdStCstAvlFlg6 "0";
BA_REL_ "GenSigRxStartValue" BU_SG_REL_ Firewall_PB SG_ 1638 AutoHtdStCstAvlFlg7 "0";
BA_REL_ "GenSigRxStartValue" BU_SG_REL_ Firewall_PB SG_ 1638 HVACRmtStrtStCstCurSetVal "0";
BA_REL_ "GenSigRxStartValue" BU_SG_REL_ Firewall_PB SG_ 1638 HVACRmtStrtStCstStAvl "0";
BA_REL_ "GenSigRxStartValue" BU_SG_REL_ Firewall_PB SG_ 1638 HVACRmtStrtStCstAvlFlg1 "0";
BA_REL_ "GenSigRxStartValue" BU_SG_REL_ Firewall_PB SG_ 1638 HVACRmtStrtStCstAvlFlg2 "0";
BA_REL_ "GenSigRxStartValue" BU_SG_REL_ Firewall_PB SG_ 1638 HVACRmtStrtStCstAvlFlg3 "0";
BA_REL_ "GenSigRxStartValue" BU_SG_REL_ Firewall_PB SG_ 1638 HVACRmtStrtStCstAvlFlg4 "0";
BA_REL_ "GenSigRxStartValue" BU_SG_REL_ Firewall_PB SG_ 1638 HVACRmtStrtStCstAvlFlg5 "0";
BA_REL_ "GenSigRxStartValue" BU_SG_REL_ Firewall_PB SG_ 1638 HVACRmtStrtStCstAvlFlg6 "0";
BA_REL_ "GenSigRxStartValue" BU_SG_REL_ Firewall_PB SG_ 1638 HVACRmtStrtStCstAvlFlg7 "0";
BA_REL_ "GenSigRxStartValue" BU_SG_REL_ ECC_PB SG_ 1631 AirQltySensCstChgSetReq "0";
BA_REL_ "GenSigRxStartValue" BU_SG_REL_ ECC_PB SG_ 1631 IonzrCtrlCstChgSetReq "0";
BA_REL_ "GenSigRxStartValue" BU_SG_REL_ ECC_PB SG_ 1631 AutoDfgCstChgSetReq "0";
BA_REL_ "GenSigRxStartValue" BU_SG_REL_ ECC_PB SG_ 1631 AutoFanCstChgSetReq "0";
BA_REL_ "GenSigRxStartValue" BU_SG_REL_ ECC_PB SG_ 1631 RrDfgStUpCstChgSetReq "0";
BA_REL_ "GenSigRxStartValue" BU_SG_REL_ ECC_PB SG_ 1631 RrZnStUpCstChgSetReq "0";
BA_REL_ "GenSigRxStartValue" BU_SG_REL_ ECC_PB SG_ 1639 AutoHtdStCstChgSetReq "0";
BA_REL_ "GenSigRxStartValue" BU_SG_REL_ ECC_PB SG_ 1639 HVACRmtStrtStCstChgSetReq "0";
BA_REL_ "GenSigRxStartValue" BU_SG_REL_ ECC_PB SG_ 1704 RstrCstDfltReq "0";
BA_REL_ "GenSigRxStartValue" BU_SG_REL_ Firewall_PB SG_ 1713 IndAirDstFL "0";
BA_REL_ "GenSigRxStartValue" BU_SG_REL_ Firewall_PB SG_ 1713 IndAirDstFR "0";
BA_REL_ "GenSigRxStartValue" BU_SG_REL_ Firewall_PB SG_ 1713 IndFrtHVAC_On "0";
BA_REL_ "GenSigRxStartValue" BU_SG_REL_ Firewall_PB SG_ 1713 IndBlwStngLvlFrt "0";
BA_REL_ "GenSigRxStartValue" BU_SG_REL_ Firewall_PB SG_ 1713 IndBlwStngStFrt "0";
BA_REL_ "GenSigRxStartValue" BU_SG_REL_ Firewall_PB SG_ 1713 IndTmpStngLvlFL "0";
BA_REL_ "GenSigRxStartValue" BU_SG_REL_ Firewall_PB SG_ 1713 IndTmpStngStFL "0";
BA_REL_ "GenSigRxStartValue" BU_SG_REL_ Firewall_PB SG_ 1713 IndTmpStngLvlFR "0";
BA_REL_ "GenSigRxStartValue" BU_SG_REL_ Firewall_PB SG_ 1713 IndTmpStngStFR "0";
BA_REL_ "GenSigRxStartValue" BU_SG_REL_ Firewall_PB SG_ 1713 IndTmpUnts "0";
BA_REL_ "GenSigRxStartValue" BU_SG_REL_ Firewall_PB SG_ 1713 IndRecircStng "0";
BA_REL_ "GenSigRxStartValue" BU_SG_REL_ Firewall_PB SG_ 1713 IndFogPrtcTkngFrshAirActMsg "0";
BA_REL_ "GenSigRxStartValue" BU_SG_REL_ Firewall_PB SG_ 1713 IndAirQltSysTkngRecircActMsg "0";
BA_REL_ "GenSigRxStartValue" BU_SG_REL_ Firewall_PB SG_ 1713 IndLowSpdPlltnTkngRecircActMsg "0";
BA_REL_ "GenSigRxStartValue" BU_SG_REL_ Firewall_PB SG_ 1713 IndRrWndDfgStng "0";
BA_REL_ "GenSigRxStartValue" BU_SG_REL_ Firewall_PB SG_ 1713 AirCndActIO "0";
BA_REL_ "GenSigRxStartValue" BU_SG_REL_ IPC_PB SG_ 1713 AirCndActIO "0";
BA_REL_ "GenSigRxStartValue" BU_SG_REL_ Firewall_PB SG_ 1713 IndCompStng "0";
BA_REL_ "GenSigRxStartValue" BU_SG_REL_ Firewall_PB SG_ 1713 IndClmMdStng "0";
BA_REL_ "GenSigRxStartValue" BU_SG_REL_ Firewall_PB SG_ 1713 IndInzrStat "0";
BA_REL_ "GenSigRxStartValue" BU_SG_REL_ Firewall_PB SG_ 1713 IndAC_OnBatCoolMsg "0";
BA_REL_ "GenSigRxStartValue" BU_SG_REL_ Firewall_PB SG_ 1713 IndSYNC_All "0";
BA_REL_ "GenSigRxStartValue" BU_SG_REL_ Firewall_PB SG_ 1713 HVAC_StngsCtrlAvlbl "0";
BA_REL_ "GenSigRxStartValue" BU_SG_REL_ ECC_PB SG_ 1716 ReqAirDstFLInfo "0";
BA_REL_ "GenSigRxStartValue" BU_SG_REL_ ECC_PB SG_ 1716 ReqAirDstFRInfo "0";
BA_REL_ "GenSigRxStartValue" BU_SG_REL_ ECC_PB SG_ 1716 ReqFrtHVAC_PwrChgInfo "0";
BA_REL_ "GenSigRxStartValue" BU_SG_REL_ ECC_PB SG_ 1716 ReqFrtAutoInfo "0";
BA_REL_ "GenSigRxStartValue" BU_SG_REL_ ECC_PB SG_ 1716 ReqBlwLvlChgFrtInfo "0";
BA_REL_ "GenSigRxStartValue" BU_SG_REL_ ECC_PB SG_ 1716 ReqBlwLvlFrtInfo "0";
BA_REL_ "GenSigRxStartValue" BU_SG_REL_ ECC_PB SG_ 1716 ReqBlwLvlFrtAtvInfo "0";
BA_REL_ "GenSigRxStartValue" BU_SG_REL_ ECC_PB SG_ 1716 ReqBlwSpdRdctnInfo "0";
BA_REL_ "GenSigRxStartValue" BU_SG_REL_ ECC_PB SG_ 1716 ReqTmpChgFLInfo "0";
BA_REL_ "GenSigRxStartValue" BU_SG_REL_ ECC_PB SG_ 1716 ReqTmpChgFRInfo "0";
BA_REL_ "GenSigRxStartValue" BU_SG_REL_ ECC_PB SG_ 1716 ReqTmpLvlFLInfo "0";
BA_REL_ "GenSigRxStartValue" BU_SG_REL_ ECC_PB SG_ 1716 ReqTmpLvlFLAtvInfo "0";
BA_REL_ "GenSigRxStartValue" BU_SG_REL_ ECC_PB SG_ 1716 ReqTmpLvlFRInfo "0";
BA_REL_ "GenSigRxStartValue" BU_SG_REL_ ECC_PB SG_ 1716 ReqTmpLvlFRAtvInfo "0";
BA_REL_ "GenSigRxStartValue" BU_SG_REL_ ECC_PB SG_ 1716 ReqRecircStngChgInfo "0";
BA_REL_ "GenSigRxStartValue" BU_SG_REL_ ECC_PB SG_ 1716 ReqCompStngChgInfo "0";
BA_REL_ "GenSigRxStartValue" BU_SG_REL_ ECC_PB SG_ 1716 ReqCompStngInfo "0";
BA_REL_ "GenSigRxStartValue" BU_SG_REL_ ECC_PB SG_ 1716 ReqClmtMdStngChgInfo "0";
BA_REL_ "GenSigRxStartValue" BU_SG_REL_ ECC_PB SG_ 1716 ReqClmtMdStngInfo "0";
BA_REL_ "GenSigRxStartValue" BU_SG_REL_ ECC_PB SG_ 1716 ReqSYNC_AllChgInfo "0";
BA_REL_ "GenSigRxStartValue" BU_SG_REL_ Firewall_PB SG_ 1717 ReqFrtClmtApp "0";
BA_REL_ "GenSigTimeoutMsg" BU_SG_REL_ CGM_PB SG_ 874 AuxHtrAtv 874;
BA_REL_ "GenSigSuprvResp" BU_SG_REL_ CGM_PB SG_ 874 AuxHtrAtv 1;
BA_REL_ "GenSigTimeoutTime" BU_SG_REL_ CGM_PB SG_ 874 AuxHtrAtv 3000;
BA_REL_ "GenSigTimeoutMsg" BU_SG_REL_ CGM_PB SG_ 874 CCClntCrcFlwRtReq 874;
BA_REL_ "GenSigSuprvResp" BU_SG_REL_ CGM_PB SG_ 874 CCClntCrcFlwRtReq 1;
BA_REL_ "GenSigTimeoutTime" BU_SG_REL_ CGM_PB SG_ 874 CCClntCrcFlwRtReq 3000;
BA_REL_ "GenSigTimeoutMsg" BU_SG_REL_ CGM_PB SG_ 874 HtrCoreInltClntTmpCalc 874;
BA_REL_ "GenSigSuprvResp" BU_SG_REL_ CGM_PB SG_ 874 HtrCoreInltClntTmpCalc 1;
BA_REL_ "GenSigTimeoutTime" BU_SG_REL_ CGM_PB SG_ 874 HtrCoreInltClntTmpCalc 3000;
BA_REL_ "GenSigTimeoutMsg" BU_SG_REL_ CGM_PB SG_ 912 ClmtHtPwrRqd 912;
BA_REL_ "GenSigSuprvResp" BU_SG_REL_ CGM_PB SG_ 912 ClmtHtPwrRqd 1;
BA_REL_ "GenSigTimeoutTime" BU_SG_REL_ CGM_PB SG_ 912 ClmtHtPwrRqd 3000;
BA_REL_ "GenSigTimeoutMsg" BU_SG_REL_ ECC_PB SG_ 315 EvpCorOtltAirTmpCalcd 315;
BA_REL_ "GenSigSuprvResp" BU_SG_REL_ ECC_PB SG_ 315 EvpCorOtltAirTmpCalcd 1;
BA_REL_ "GenSigTimeoutTime" BU_SG_REL_ ECC_PB SG_ 315 EvpCorOtltAirTmpCalcd 3000;
BA_REL_ "GenSigTimeoutMsg" BU_SG_REL_ ECC_PB SG_ 314 ClmCntCmpPwrUsdClc 314;
BA_REL_ "GenSigSuprvResp" BU_SG_REL_ ECC_PB SG_ 314 ClmCntCmpPwrUsdClc 1;
BA_REL_ "GenSigTimeoutTime" BU_SG_REL_ ECC_PB SG_ 314 ClmCntCmpPwrUsdClc 3000;
BA_REL_ "GenSigTimeoutMsg" BU_SG_REL_ ECC_PB SG_ 317 EngAstHtDfrdHtMdAct 317;
BA_REL_ "GenSigSuprvResp" BU_SG_REL_ ECC_PB SG_ 317 EngAstHtDfrdHtMdAct 1;
BA_REL_ "GenSigTimeoutTime" BU_SG_REL_ ECC_PB SG_ 317 EngAstHtDfrdHtMdAct 3000;
VAL_ 914 PassHCSeatSw3Act 1 "True" 0 "False" ;
VAL_ 914 PassHCSeatSw2Act 1 "True" 0 "False" ;
VAL_ 914 PassHCSeatSw1Act 1 "True" 0 "False" ;
VAL_ 914 DrvHCSeatSw3Act 1 "True" 0 "False" ;
VAL_ 914 DrvHCSeatSw2Act 1 "True" 0 "False" ;
VAL_ 914 DrvHCSeatSw1Act 1 "True" 0 "False" ;
VAL_ 950 RRHCSeatSw3Act 1 "True" 0 "False" ;
VAL_ 950 RRHCSeatSw2Act 1 "True" 0 "False" ;
VAL_ 950 RRHCSeatSw1Act 1 "True" 0 "False" ;
VAL_ 950 RLHCSeatSw3Act 1 "True" 0 "False" ;
VAL_ 950 RLHCSeatSw2Act 1 "True" 0 "False" ;
VAL_ 950 RLHCSeatSw1Act 1 "True" 0 "False" ;
VAL_ 850 PsngSysLatV 0 "Valid" 1 "Invalid" ;
VAL_ 850 PsngSysLongV 0 "Valid" 1 "Invalid" ;
VAL_ 851 PsngSysDilPrcsV 0 "Valid" 1 "Invalid" ;
VAL_ 851 PsngSysHdingV 0 "Valid" 1 "Invalid" ;
VAL_ 851 PsngSysCalcSpdV 0 "Valid" 1 "Invalid" ;
VAL_ 851 PsngSysElvtnV 0 "Valid" 1 "Invalid" ;
VAL_ 881 LgclAVChnl 0 "None" 1 "Unused and Reserved 1" 2 "Unused and Reserved 2" 3 "Asynchronous Message" 4 "Incoming Call" 5 "Phone" 6 "Synchronous Message" 7 "Speech Recognition" 8 "Emergency Phone Call" 9 "Short Mix Alert Message" 10 "Unused and Reserved 3" 11 "Unused and Reserved 4" 12 "Onstar Initiated Call" ;
VAL_ 881 ASSAudSrcType 1 "Television Tuner" 8 "Auxiliary Device" 12 "Remote Digital Video Disk" 16 "Remote CD Changer" 20 "Digital Audio Broadcast" 24 "Sat. Digital Audio Receiver System" 28 "Phone" ;
VAL_ 881 ASSAudSrcChType 0 "No Action" 1 "Mono" 2 "Stereo" 3 "Mixed" 4 "Mono Emergency" ;
VAL_ 881 ASSAudSrcStatCode 0 "Device Present" 1 "Audio Available" 2 "Audio Not Available" 3 "Reserved" 4 "Producing Silence" 5 "Producing Audio" ;
VAL_ 883 ASS2AudSrcType 1 "Television Tuner" 8 "Auxiliary Device" 12 "Remote Digital Video Disk" 16 "Remote CD Changer" 20 "Digital Audio Broadcast" 24 "Sat. Digital Audio Receiver System" 28 "Phone" ;
VAL_ 883 ASS2AudSrcChType 0 "No Action" 1 "Mono" 2 "Stereo" 3 "Mixed" 4 "Mono Emergency" ;
VAL_ 883 ASS2AudSrcStatCode 0 "Device Present" 1 "Audio Available" 2 "Audio Not Available" 3 "Reserved" 4 "Producing Silence" 5 "Producing Audio" ;
VAL_ 948 RLHCSMIndReq 0 "Off" 1 "Continuous Indication" 2 "Flash Rate #1 Indication" 3 "Flash Rate #2 Indication" ;
VAL_ 948 RLHCSMInd1 1 "True" 0 "False" ;
VAL_ 948 RLHCSMInd2 1 "True" 0 "False" ;
VAL_ 948 RLHCSMInd3 1 "True" 0 "False" ;
VAL_ 948 RRHCSMIndReq 0 "Off" 1 "Continuous Indication" 2 "Flash Rate #1 Indication" 3 "Flash Rate #2 Indication" ;
VAL_ 948 RRHCSMInd1 1 "True" 0 "False" ;
VAL_ 948 RRHCSMInd2 1 "True" 0 "False" ;
VAL_ 948 RRHCSMInd3 1 "True" 0 "False" ;
VAL_ 948 RLHCSLIndReq 0 "Off" 1 "Continuous Indication" 2 "Flash Rate #1 Indication" 3 "Flash Rate #2 Indication" ;
VAL_ 948 RLHCSLSeatLev1 1 "True" 0 "False" ;
VAL_ 948 RLHCSLSeatLev2 1 "True" 0 "False" ;
VAL_ 948 RLHCSLSeatLev3 1 "True" 0 "False" ;
VAL_ 948 RLHCSLSeatLev4 1 "True" 0 "False" ;
VAL_ 948 RLHCSLSeatLev5 1 "True" 0 "False" ;
VAL_ 948 RRHCSLIndReq 0 "Off" 1 "Continuous Indication" 2 "Flash Rate #1 Indication" 3 "Flash Rate #2 Indication" ;
VAL_ 948 RRHCSLSeatLev1 1 "True" 0 "False" ;
VAL_ 948 RRHCSLSeatLev2 1 "True" 0 "False" ;
VAL_ 948 RRHCSLSeatLev3 1 "True" 0 "False" ;
VAL_ 948 RRHCSLSeatLev4 1 "True" 0 "False" ;
VAL_ 948 RRHCSLSeatLev5 1 "True" 0 "False" ;
VAL_ 1061 DispMeasSys 0 "Metric" 1 "English" ;
VAL_ 1061 DispMeasSysExt 0 "Metric" 1 "US" 2 "Imperial" ;
VAL_ 1138 SecCmpstdValV 0 "Valid" 1 "Invalid" ;
VAL_ 1138 MinsCmpstdValV 0 "Valid" 1 "Invalid" ;
VAL_ 1138 HrsCmpstdValV 0 "Valid" 1 "Invalid" ;
VAL_ 1138 CldrMthCmpstdVal 0 "Unknown" 1 "January" 2 "February" 3 "March" 4 "April" 5 "May" 6 "June" 7 "July" 8 "August" 9 "September" 10 "October" 11 "November" 12 "December" ;
VAL_ 1136 FrPedDetCsStReq 0 "No Action" 1 "Off" 2 "Alert" 3 "Alert and Brake" ;
VAL_ 1136 CldrMth 0 "Unknown" 1 "January" 2 "February" 3 "March" 4 "April" 5 "May" 6 "June" 7 "July" 8 "August" 9 "September" 10 "October" 11 "November" 12 "December" ;
VAL_ 1136 TimeDispFormat 0 "12 hour mode" 1 "24 hour mode" ;
VAL_ 1088 ReIniReq_BCM 1 "True" 0 "False" ;
VAL_ 1089 ReIniReq_IPC 1 "True" 0 "False" ;
VAL_ 1122 ReIniReq_APA 1 "True" 0 "False" ;
VAL_ 1091 ReIniReq_ECC 1 "True" 0 "False" ;
VAL_ 1093 ReIniReq_ESCL 1 "True" 0 "False" ;
VAL_ 1094 ReIniReq_FCM 1 "True" 0 "False" ;
VAL_ 1095 ReIniReq_ONSTAR 1 "True" 0 "False" ;
VAL_ 1096 ReIniReq_RadioHead 1 "True" 0 "False" ;
VAL_ 1097 ReIniReq_SDM 1 "True" 0 "False" ;
VAL_ 502 SysPwrMdMac 0 "Off" 1 "Accessory" 2 "Run" 3 "Crank Request" ;
VAL_ 502 SysPwrMdVMac 0 "Valid" 1 "Invalid" ;
VAL_ 502 ImmblzrPreRelPswdStatMac 0 "No Information" 1 "Information Valid" ;
VAL_ 502 PMMAccTrmStMac 0 "Inactive" 1 "Active" ;
VAL_ 502 PMMRunCrkTrmStMac 0 "Inactive" 1 "Active" ;
VAL_ 502 RemStrtStMac 0 "Inactive" 1 "Active" ;
VAL_ 502 RmVehStrRqMac 0 "Remote Start Not Requested" 1 "Remote Start Requested" ;
VAL_ 291 SysBkUpPwrMdMac 0 "Off" 1 "Accessory" 2 "Run" 3 "Crank Request" ;
VAL_ 291 SysBkupPwrMdEnMac 1 "True" 0 "False" ;
VAL_ 291 SysBkUpPwrMdVMac 0 "Valid" 1 "Invalid" ;
VAL_ 291 BkUpPwrMdRnCrnkOutSt 0 "FALSE" 1 "TRUE" ;
VAL_ 291 ElecPwrStrSlctdMdMac 0 "Standard" 1 "Comfort" 2 "Reserved" 3 "Reserved" ;
VAL_ 1003 VehSpdAvgDrvnSrcMac 0 "Transmission Output Speed" 1 "Wheel Speed" ;
VAL_ 1003 VehSpdAvgDrvnVMac 0 "Valid" 1 "Invalid" ;
VAL_ 203 AccActPosVMac 0 "Valid" 1 "Invalid" ;
VAL_ 203 EngSpdStatMac 0 "Normal Operation" 1 "Degraded Operation" 3 "Invalid" ;
VAL_ 203 PT_CrnkActMac 1 "True" 0 "False" ;
VAL_ 1630 AirQltySnsCstCrStVal 0 "SETTING_UNKNOWN" 1 "OFF" 2 "LOW_SENSITIVITY" 3 "HI_SENSITIVITY" 4 "RESERVED_1" 5 "RESERVED_2" 6 "RESERVED_3" 7 "RESERVED_4" ;
VAL_ 1630 AirQltySnsCstStAvl 0 "FALSE" 1 "TRUE" ;
VAL_ 1630 AirQltySnsCstAvlFlg1 0 "FALSE" 1 "TRUE" ;
VAL_ 1630 AirQltySnsCstAvlFlg2 0 "FALSE" 1 "TRUE" ;
VAL_ 1630 AirQltySnsCstAvlFlg3 0 "FALSE" 1 "TRUE" ;
VAL_ 1630 AirQltySnsCstAvlFlg4 0 "FALSE" 1 "TRUE" ;
VAL_ 1630 AirQltySnsCstAvlFlg5 0 "FALSE" 1 "TRUE" ;
VAL_ 1630 AirQltySnsCstAvlFlg6 0 "FALSE" 1 "TRUE" ;
VAL_ 1630 AirQltySnsCstAvlFlg7 0 "FALSE" 1 "TRUE" ;
VAL_ 1630 IonzrCtrlCstCrStVal 0 "SETTING_UNKNOWN" 1 "OFF" 2 "ON" 3 "RESERVED_1" 4 "RESERVED_2" 5 "RESERVED_3" 6 "RESERVED_4" 7 "RESERVED_5" ;
VAL_ 1630 IonzrCtrlCstStAvl 0 "FALSE" 1 "TRUE" ;
VAL_ 1630 IonzrCtrlCstAvlFlg1 0 "FALSE" 1 "TRUE" ;
VAL_ 1630 IonzrCtrlCstAvlFlg2 0 "FALSE" 1 "TRUE" ;
VAL_ 1630 IonzrCtrlCstAvlFlg3 0 "FALSE" 1 "TRUE" ;
VAL_ 1630 IonzrCtrlCstAvlFlg4 0 "FALSE" 1 "TRUE" ;
VAL_ 1630 IonzrCtrlCstAvlFlg5 0 "FALSE" 1 "TRUE" ;
VAL_ 1630 IonzrCtrlCstAvlFlg6 0 "FALSE" 1 "TRUE" ;
VAL_ 1630 IonzrCtrlCstAvlFlg7 0 "FALSE" 1 "TRUE" ;
VAL_ 1630 AutoDfgCstCrStVal 0 "SETTING_UNKNOWN" 1 "OFF" 2 "ON" 3 "RESERVED_1" 4 "RESERVED_2" 5 "RESERVED_3" 6 "RESERVED_4" 7 "RESERVED_5" ;
VAL_ 1630 AutoDfgCstStAvl 0 "FALSE" 1 "TRUE" ;
VAL_ 1630 AutoDfgCstAvlFlg1 0 "FALSE" 1 "TRUE" ;
VAL_ 1630 AutoDfgCstAvlFlg2 0 "FALSE" 1 "TRUE" ;
VAL_ 1630 AutoDfgCstAvlFlg3 0 "FALSE" 1 "TRUE" ;
VAL_ 1630 AutoDfgCstAvlFlg4 0 "FALSE" 1 "TRUE" ;
VAL_ 1630 AutoDfgCstAvlFlg5 0 "FALSE" 1 "TRUE" ;
VAL_ 1630 AutoDfgCstAvlFlg6 0 "FALSE" 1 "TRUE" ;
VAL_ 1630 AutoDfgCstAvlFlg7 0 "FALSE" 1 "TRUE" ;
VAL_ 1630 AutoFanCstCrStVal 0 "SETTING_UNKNOWN" 1 "LOW" 2 "NORMAL" 3 "HIGH" 4 "RESERVED_1" 5 "RESERVED_2" 6 "RESERVED_3" 7 "RESERVED_4" ;
VAL_ 1630 AutoFanCstStAvl 0 "FALSE" 1 "TRUE" ;
VAL_ 1630 AutoFanCstAvlFlg1 0 "FALSE" 1 "TRUE" ;
VAL_ 1630 AutoFanCstAvlFlg2 0 "FALSE" 1 "TRUE" ;
VAL_ 1630 AutoFanCstAvlFlg3 0 "FALSE" 1 "TRUE" ;
VAL_ 1630 AutoFanCstAvlFlg4 0 "FALSE" 1 "TRUE" ;
VAL_ 1630 AutoFanCstAvlFlg5 0 "FALSE" 1 "TRUE" ;
VAL_ 1630 AutoFanCstAvlFlg6 0 "FALSE" 1 "TRUE" ;
VAL_ 1630 AutoFanCstAvlFlg7 0 "FALSE" 1 "TRUE" ;
VAL_ 1638 RrDfgStUpCstCrStVal 0 "SETTING_UNKNOWN" 1 "MANUAL" 2 "AUTOMATIC" 3 "RESERVED_1" 4 "RESERVED_2" 5 "RESERVED_3" 6 "RESERVED_4" 7 "RESERVED_5" ;
VAL_ 1638 RrDfgStUpCstStAvl 0 "FALSE" 1 "TRUE" ;
VAL_ 1638 RrDfgStUpCstAvlFlg1 0 "FALSE" 1 "TRUE" ;
VAL_ 1638 RrDfgStUpCstAvlFlg2 0 "FALSE" 1 "TRUE" ;
VAL_ 1638 RrDfgStUpCstAvlFlg3 0 "FALSE" 1 "TRUE" ;
VAL_ 1638 RrDfgStUpCstAvlFlg4 0 "FALSE" 1 "TRUE" ;
VAL_ 1638 RrDfgStUpCstAvlFlg5 0 "FALSE" 1 "TRUE" ;
VAL_ 1638 RrDfgStUpCstAvlFlg6 0 "FALSE" 1 "TRUE" ;
VAL_ 1638 RrDfgStUpCstAvlFlg7 0 "FALSE" 1 "TRUE" ;
VAL_ 1638 RrZnStUpCstCrStVal 0 "SETTING_UNKNOWN" 1 "REAR_OFF" 2 "REAR_MIMIC_FRONT" 3 "REAR_LAST_KNOWN" 4 "RESERVED_1" 5 "RESERVED_2" 6 "RESERVED_3" 7 "RESERVED_4" ;
VAL_ 1638 RrZnStUpCstStAvl 0 "FALSE" 1 "TRUE" ;
VAL_ 1638 RrZnStUpCstAvlFlg1 0 "FALSE" 1 "TRUE" ;
VAL_ 1638 RrZnStUpCstAvlFlg2 0 "FALSE" 1 "TRUE" ;
VAL_ 1638 RrZnStUpCstAvlFlg3 0 "FALSE" 1 "TRUE" ;
VAL_ 1638 RrZnStUpCstAvlFlg4 0 "FALSE" 1 "TRUE" ;
VAL_ 1638 RrZnStUpCstAvlFlg5 0 "FALSE" 1 "TRUE" ;
VAL_ 1638 RrZnStUpCstAvlFlg6 0 "FALSE" 1 "TRUE" ;
VAL_ 1638 RrZnStUpCstAvlFlg7 0 "FALSE" 1 "TRUE" ;
VAL_ 1638 AutoCoolStCstCrStVal 0 "SETTING_UNKNOWN" 1 "OFF" 2 "ON" 3 "RESERVED_1" 4 "RESERVED_2" 5 "RESERVED_3" 6 "RESERVED_4" 7 "RESERVED_5" ;
VAL_ 1638 AutoCoolStCstStAvl 0 "FALSE" 1 "TRUE" ;
VAL_ 1638 AutoCoolStCstAvlFlg1 0 "FALSE" 1 "TRUE" ;
VAL_ 1638 AutoCoolStCstAvlFlg2 0 "FALSE" 1 "TRUE" ;
VAL_ 1638 AutoCoolStCstAvlFlg3 0 "FALSE" 1 "TRUE" ;
VAL_ 1638 AutoCoolStCstAvlFlg4 0 "FALSE" 1 "TRUE" ;
VAL_ 1638 AutoCoolStCstAvlFlg5 0 "FALSE" 1 "TRUE" ;
VAL_ 1638 AutoCoolStCstAvlFlg6 0 "FALSE" 1 "TRUE" ;
VAL_ 1638 AutoCoolStCstAvlFlg7 0 "FALSE" 1 "TRUE" ;
VAL_ 1638 AutoHtdStCstCrStVal 0 "SETTING_UNKNOWN" 1 "OFF" 2 "ON" 3 "RESERVED_1" 4 "RESERVED_2" 5 "RESERVED_3" 6 "RESERVED_4" 7 "RESERVED_5" ;
VAL_ 1638 AutoHtdStCstStAvl 0 "FALSE" 1 "TRUE" ;
VAL_ 1638 AutoHtdStCstAvlFlg1 0 "FALSE" 1 "TRUE" ;
VAL_ 1638 AutoHtdStCstAvlFlg2 0 "FALSE" 1 "TRUE" ;
VAL_ 1638 AutoHtdStCstAvlFlg3 0 "FALSE" 1 "TRUE" ;
VAL_ 1638 AutoHtdStCstAvlFlg4 0 "FALSE" 1 "TRUE" ;
VAL_ 1638 AutoHtdStCstAvlFlg5 0 "FALSE" 1 "TRUE" ;
VAL_ 1638 AutoHtdStCstAvlFlg6 0 "FALSE" 1 "TRUE" ;
VAL_ 1638 AutoHtdStCstAvlFlg7 0 "FALSE" 1 "TRUE" ;
VAL_ 1638 HVACRmtStrtStCstCurSetVal 0 "SETTING_UNKNOWN" 1 "AUTOMATIC" 2 "LAST_SETTING" 3 "RESERVED_1" 4 "RESERVED_2" 5 "RESERVED_3" 6 "RESERVED_4" 7 "RESERVED_5" ;
VAL_ 1638 HVACRmtStrtStCstStAvl 0 "FALSE" 1 "TRUE" ;
VAL_ 1638 HVACRmtStrtStCstAvlFlg1 0 "FALSE" 1 "TRUE" ;
VAL_ 1638 HVACRmtStrtStCstAvlFlg2 0 "FALSE" 1 "TRUE" ;
VAL_ 1638 HVACRmtStrtStCstAvlFlg3 0 "FALSE" 1 "TRUE" ;
VAL_ 1638 HVACRmtStrtStCstAvlFlg4 0 "FALSE" 1 "TRUE" ;
VAL_ 1638 HVACRmtStrtStCstAvlFlg5 0 "FALSE" 1 "TRUE" ;
VAL_ 1638 HVACRmtStrtStCstAvlFlg6 0 "FALSE" 1 "TRUE" ;
VAL_ 1638 HVACRmtStrtStCstAvlFlg7 0 "FALSE" 1 "TRUE" ;
VAL_ 1631 AirQltySensCstChgSetReq 0 "NO_ACTION" 1 "OFF" 2 "LOW_SENSITIVITY" 3 "HI_SENSITIVITY" 4 "RESERVED_4" 5 "RESERVED_5" 6 "RESERVED_6" 7 "RESERVED_7" ;
VAL_ 1631 IonzrCtrlCstChgSetReq 0 "NO_ACTION" 1 "OFF" 2 "ON" 3 "RESERVED_3" 4 "RESERVED_4" 5 "RESERVED_5" 6 "RESERVED_6" 7 "RESERVED_7" ;
VAL_ 1631 AutoDfgCstChgSetReq 0 "NO_ACTION" 1 "OFF" 2 "ON" 3 "RESERVED_3" 4 "RESERVED_4" 5 "RESERVED_5" 6 "RESERVED_6" 7 "RESERVED_7" ;
VAL_ 1631 AutoFanCstChgSetReq 0 "NO_ACTION" 1 "LOW" 2 "NORMAL" 3 "HIGH" 4 "RESERVED_4" 5 "RESERVED_5" 6 "RESERVED_6" 7 "RESERVED_7" ;
VAL_ 1631 RrDfgStUpCstChgSetReq 0 "NO_ACTION" 1 "MANUAL" 2 "AUTOMATIC" 3 "RESERVED_3" 4 "RESERVED_4" 5 "RESERVED_5" 6 "RESERVED_6" 7 "RESERVED_7" ;
VAL_ 1631 RrZnStUpCstChgSetReq 0 "NO_ACTION" 1 "REAR_OFF" 2 "REAR_MIMIC_FRONT" 3 "REAR_LAST_KNOWN" 4 "RESERVED_4" 5 "RESERVED_5" 6 "RESERVED_6" 7 "RESERVED_7" ;
VAL_ 1639 AutoHtdStCstChgSetReq 0 "NO_ACTION" 1 "OFF" 2 "ON" 3 "RESERVED_3" 4 "RESERVED_4" 5 "RESERVED_5" 6 "RESERVED_6" 7 "RESERVED_7" ;
VAL_ 1639 HVACRmtStrtStCstChgSetReq 0 "NO_ACTION" 1 "AUTOMATIC" 2 "LAST_SETTING" 3 "RESERVED_3" 4 "RESERVED_4" 5 "RESERVED_5" 6 "RESERVED_6" 7 "RESERVED_7" ;
VAL_ 1704 RstrCstDfltReq 0 "FALSE" 1 "TRUE" ;
VAL_ 1713 IndAirDstFL 0 "Off" 1 "Auto" 2 "Floor" 3 "Floor And Vent" 4 "Vent" 5 "Vent And Windshield" 6 "Windshield" 7 "Floor And Windshield" 8 "Floor And Vent And Windshield" 9 "Max Defrost" ;
VAL_ 1713 IndAirDstFR 0 "Off" 1 "Auto" 2 "Floor" 3 "Floor And Vent" 4 "Vent" 5 "Vent And Windshield" 6 "Windshield" 7 "Floor And Windshield" 8 "Floor And Vent And Windshield" 9 "Max Defrost" ;
VAL_ 1713 IndFrtHVAC_On 0 "FALSE" 1 "TRUE" ;
VAL_ 1713 IndBlwStngStFrt 0 "Off" 1 "Auto" 2 "Manual" ;
VAL_ 1713 IndTmpStngStFL 0 "Off" 1 "Auto" 2 "Auto Lo" 3 "Auto Hi" 4 "Manual" ;
VAL_ 1713 IndTmpStngStFR 0 "Off" 1 "Auto" 2 "Auto Lo" 3 "Auto Hi" 4 "Manual" ;
VAL_ 1713 IndTmpUnts 0 "Celcius" 1 "Fahrenheit" ;
VAL_ 1713 IndRecircStng 0 "Off" 1 "Auto" 2 "Fresh Air" 3 "Recirc" ;
VAL_ 1713 IndFogPrtcTkngFrshAirActMsg 0 "FALSE" 1 "TRUE" ;
VAL_ 1713 IndAirQltSysTkngRecircActMsg 0 "FALSE" 1 "TRUE" ;
VAL_ 1713 IndLowSpdPlltnTkngRecircActMsg 0 "FALSE" 1 "TRUE" ;
VAL_ 1713 IndRrWndDfgStng 0 "Rear Defog OFF" 1 "Rear Defog ON" ;
VAL_ 1713 AirCndActIO 0 "FALSE" 1 "TRUE" ;
VAL_ 1713 IndCompStng 0 "OFF" 1 "COMP_OFF" 2 "COMP_ON" 3 "COMP_ECON" ;
VAL_ 1713 IndClmMdStng 0 "OFF" 1 "Comfort" 2 "ECO" 3 "Fan Only" ;
VAL_ 1713 IndInzrStat 0 "OFF" 1 "Ionizer ON" 2 "Ionizer OFF" 3 "Ionizer LO" 4 "Ionizer HI" ;
VAL_ 1713 IndAC_OnBatCoolMsg 0 "FALSE" 1 "TRUE" ;
VAL_ 1713 IndSYNC_All 0 "FALSE" 1 "TRUE" ;
VAL_ 1713 HVAC_StngsCtrlAvlbl 0 "FALSE" 1 "TRUE" ;
VAL_ 1716 ReqAirDstFLInfo 0 "NoAction" 1 "Auto" 2 "Floor" 3 "FloorAndVent" 4 "Vent" 5 "VentAndWindshield" 6 "Windshield" 7 "FloorAndWindshield" 8 "FloorAndVentAndWindshield" ;
VAL_ 1716 ReqAirDstFRInfo 0 "NoAction" 1 "Auto" 2 "Floor" 3 "FloorAndVent" 4 "Vent" 5 "VentAndWindshield" 6 "Windshield" 7 "FloorAndWindshield" 8 "FloorAndVentAndWindshield" ;
VAL_ 1716 ReqFrtHVAC_PwrChgInfo 0 "FALSE" 1 "TRUE" ;
VAL_ 1716 ReqFrtAutoInfo 0 "FALSE" 1 "TRUE" ;
VAL_ 1716 ReqBlwLvlFrtAtvInfo 0 "FALSE" 1 "TRUE" ;
VAL_ 1716 ReqBlwSpdRdctnInfo 0 "FALSE" 1 "TRUE" ;
VAL_ 1716 ReqTmpLvlFLAtvInfo 0 "FALSE" 1 "TRUE" ;
VAL_ 1716 ReqTmpLvlFRAtvInfo 0 "FALSE" 1 "TRUE" ;
VAL_ 1716 ReqRecircStngChgInfo 0 "FALSE" 1 "TRUE" ;
VAL_ 1716 ReqCompStngChgInfo 0 "FALSE" 1 "TRUE" ;
VAL_ 1716 ReqCompStngInfo 0 "NoAction" 1 "COMP_OFF" 2 "COMP_ON" 3 "COMP_ECON" ;
VAL_ 1716 ReqClmtMdStngChgInfo 0 "FALSE" 1 "TRUE" ;
VAL_ 1716 ReqClmtMdStngInfo 0 "NoAction" 1 "Comfort" 2 "ECO" 3 "Fan_Only" ;
VAL_ 1716 ReqSYNC_AllChgInfo 0 "FALSE" 1 "TRUE" ;
VAL_ 1717 ReqFrtClmtApp 0 "FALSE" 1 "TRUE" ;
VAL_ 858 CldrMth_154Mac 0 "Unknown" 1 "January" 2 "February" 3 "March" 4 "April" 5 "May" 6 "June" 7 "July" 8 "August" 9 "September" 10 "October" 11 "November" 12 "December" ;
VAL_ 859 HrsVMac 0 "Valid" 1 "Invalid" ;
VAL_ 859 MinsVMac 0 "Valid" 1 "Invalid" ;
VAL_ 859 SecVMac 0 "Valid" 1 "Invalid" ;
VAL_ 1147 CldrMthCmpstdValMac 0 "Unknown" 1 "January" 2 "February" 3 "March" 4 "April" 5 "May" 6 "June" 7 "July" 8 "August" 9 "September" 10 "October" 11 "November" 12 "December" ;
VAL_ 1150 CldrMthMac 0 "Unknown" 1 "January" 2 "February" 3 "March" 4 "April" 5 "May" 6 "June" 7 "July" 8 "August" 9 "September" 10 "October" 11 "November" 12 "December" ;
VAL_ 1151 TimeDispFormatMac 0 "12 hour mode" 1 "24 hour mode" ;
VAL_ 921 DTCIUnused6_399 1 "True" 0 "False" ;
VAL_ 921 DTCIUnused5_399 1 "True" 0 "False" ;
VAL_ 921 DTCIUnused4_399 1 "True" 0 "False" ;
VAL_ 921 DTCIUnused3_399 1 "True" 0 "False" ;
VAL_ 921 DTCIUnused2_399 1 "True" 0 "False" ;
VAL_ 921 DTCIUnused1_399 1 "True" 0 "False" ;
VAL_ 921 DTCI_WrnIndTrggrd_399 1 "True" 0 "False" ;
VAL_ 921 DTCI_DTCTriggered_399 1 "True" 0 "False" ;
VAL_ 921 DTCI_WIR_399 1 "True" 0 "False" ;
VAL_ 921 DTCI_TNCTOC_399 1 "True" 0 "False" ;
VAL_ 921 DTCI_TFSLC_399 1 "True" 0 "False" ;
VAL_ 921 DTCI_TNCSLC_399 1 "True" 0 "False" ;
VAL_ 921 DTCI_CDTC_399 1 "True" 0 "False" ;
VAL_ 921 DTCI_PDTC_399 1 "True" 0 "False" ;
VAL_ 921 DTCI_TFTOC_399 1 "True" 0 "False" ;
VAL_ 921 DTCI_TF_399 1 "True" 0 "False" ;
VAL_ 921 DTCI_DTCFaultType_399 0 "Not Supported" 1 "Type A" 2 "Type B" 3 "Type C" ;
VAL_ 874 HtrCoreInltClntTmpCalcV 0 "Valid" 1 "Invalid" ;
VAL_ 874 AuxHtrAtv 1 "True" 0 "False" ;
VAL_ 912 ClmtHtPwrRqd 1 "True" 0 "False" ;
VAL_ 965 HybMdDisp 0 "Default / Accessory" 1 "Engine Idle" 2 "Auto Stop" 3 "Battery Power 2WD" 4 "Battery Power 4WD" 5 "Engine Power 2WD" 6 "Engine Power 4WD" 7 "Hybrid Power 2WD" 8 "Hybrid Power 4WD" 9 "Charging With Engine Off" 10 "Charging With Engine On" 11 "Undetermined" 12 "Battery Power Load Sharing" 13 "Engine Power Load Sharing" 14 "Engine Charging Battery Moving" 15 "Engine Charging Battery While Idle" ;
VAL_ 965 JmpStrtStat 0 "Inactive" 1 "In Progress" 2 "Complete" 3 "Power Mode" 4 "Disabled" ;
VAL_ 965 SvcHybridSysIO 1 "True" 0 "False" ;
VAL_ 965 CstmrUsblSOCV 0 "Valid" 1 "Invalid" ;
VAL_ 965 BattCntrlPrcssrVDA 0 "VirtualDeviceUnavailable" 1 "VirtualDeviceAvailable" ;
VAL_ 313 OffBrdVehImmbNot 0 "No Action" 1 "Immobilization State 1" 2 "Immobilization State 2" ;
VAL_ 313 HVInvRatVltV 0 "Valid" 1 "Invalid" ;
VAL_ 313 HybChrgMdStat 0 "Charge Depleting" 1 "Charge Sustaining" 2 "Unused and reserved 1" 3 "Unused and reserved 2" ;
VAL_ 315 EvpCorOtltAirTmpCalcdV 0 "Valid" 1 "Invalid" ;
VAL_ 315 ThrmlRefCompStat 0 "Normal Operation" 1 "Degraded Operation" 2 "Inoperative" 3 "Invalid" ;
VAL_ 315 ThrmlRfCmpOvTmpFltPr 1 "True" 0 "False" ;
VAL_ 315 ThrmlRefCompSpdV 0 "Valid" 1 "Invalid" ;
VAL_ 314 ClimCtrlHVDvcShtdwnCmd 1 "True" 0 "False" ;
VAL_ 317 LBCCsStAvl 1 "True" 0 "False" ;
VAL_ 317 LBCChrgLvlPrfExpIO 1 "True" 0 "False" ;
VAL_ 317 AuxClntHtrVlvStat 0 "Engine Bypass" 1 "Transition" 2 "Engine Link" 3 "Fault Active" 4 "Re-Calibration" 5 "Diagnostic Override" 6 "De-Aeration Routine Active" 7 "Unused and Reserved 2" ;
VAL_ 317 LBCCsCrStVal 0 "No Action" 1 "Off" 2 "On" ;
VAL_ 317 EngAstHtDfrdHtMdAct 1 "True" 0 "False" ;
VAL_ 317 LBCCDRR_ClrStrdPosResp 0 "No Action" 1 "Clear Position Request Acknowledged" 2 "Clear Position Performed" ;
VAL_ 317 LBCCDRR_PosNumbr 0 "No Action" 1 "Position Number 1" 2 "Position Number 2" 3 "Position Number 3" 4 "Position Number 4" ;
VAL_ 317 LBCPSS_PosUpdtStat 0 "No Action" 1 "Position  Updated" 2 "Position Modification Failed" ;
VAL_ 317 LBCPSS_PosUpdtLct 0 "No Action" 1 "Position 1" 2 "Position 2" 3 "Position 3" 4 "Position 4" ;
VAL_ 317 LBCCF_Lct1PosStrdIO 1 "True" 0 "False" ;
VAL_ 317 LBCCF_Lct2PosStrdIO 1 "True" 0 "False" ;
VAL_ 317 LBCCF_Lct3PosStrdIO 1 "True" 0 "False" ;
VAL_ 317 LBCCF_Lct4PosStrdIO 1 "True" 0 "False" ;
VAL_ 317 LBCVLS_VehGPSLctV 0 "Valid" 1 "Invalid" ;
VAL_ 317 LBCVLS_VehGPSLct 0 "Vehicle Not Within Stored GPS Region" 1 "Vehicle Within Stored GPS Region 1" 2 "Vehicle Within Stored GPS Region 2" 3 "Vehicle Within Stored GPS Region 3" 4 "Vehicle Within Stored GPS Region 4" ;
VAL_ 326 EngyStgSysActCoolEnb 1 "True" 0 "False" ;
VAL_ 326 HVChrgInhbRsn 0 "No Action" 1 "Charge Cord Not Fully Inserted" 2 "Charge Cord Lock Not Engaged" 3 "See Charging Station" ;
VAL_ 794 PwrElecCoolLpTempM 0 "Don't Use Data" 1 "Use Data" ;
VAL_ 794 PwrElecCoolLpTempV 0 "Valid" 1 "Invalid" ;
VAL_ 299 DDAjrSwAtvMac 1 "True" 0 "False" ;
VAL_ 299 DDAjrSwAtvMMac 0 "Don't Use Data" 1 "Use Data" ;
VAL_ 299 DrIdMac 0 "Driver #1" 1 "Driver #2" 2 "Driver #3" 3 "Driver #4" 4 "Driver #5" 5 "Driver #6" 6 "Driver #7" 7 "Unknown" ;
VAL_ 299 PDAjrSwAtvMac 1 "True" 0 "False" ;
VAL_ 299 RLDoorAjarSwActMac 1 "True" 0 "False" ;
VAL_ 299 RRDoorAjarSwActMac 1 "True" 0 "False" ;
VAL_ 299 VhSecNImmoIndRqMac 0 "No Indication" 1 "Continuous Indication" 2 "Flashing Indication" ;
VAL_ 299 RrClosAjarSwActMac 1 "True" 0 "False" ;
VAL_ 299 TCSysDisSwAtvMac 1 "True" 0 "False" ;
VAL_ 299 TCSysDisSwAtvVMac 0 "Valid" 1 "Invalid" ;
VAL_ 299 VehMovStateMac 0 "Parked" 1 "Neutral" 2 "Forward" 3 "Reverse" 4 "Invalid" ;
VAL_ 299 WSWshSwAtvMac 1 "True" 0 "False" ;
VAL_ 299 RrClsrSnwLdIOMac 1 "True" 0 "False" ;
VAL_ 299 WSWprActMac 1 "True" 0 "False" ;
VAL_ 299 HdStMac 0 "Closed" 1 "Ajar" 2 "Open" ;
VAL_ 299 HdStVMac 0 "Valid" 1 "Invalid" ;
VAL_ 498 PrkBrkSwAtvMac 1 "True" 0 "False" ;
VAL_ 498 TrStLgMdAtvMac 1 "True" 0 "False" ;
VAL_ 498 ThrtlPrgrsnReqMac 0 "Map A" 1 "Map B" 2 "Map C" ;
VAL_ 202 CrsCntAtvMac 1 "True" 0 "False" ;
VAL_ 202 CrsCntEnbldMac 1 "True" 0 "False" ;
VAL_ 202 Eng12vStrtrMtrCmmdOnMac 1 "True" 0 "False" ;
VAL_ 202 EngIdlAtvMac 1 "True" 0 "False" ;
VAL_ 202 EngAirIntBstPrVMac 0 "Valid" 1 "Invalid" ;
VAL_ 202 EngRunAtvMac 1 "True" 0 "False" ;
VAL_ 202 PT_BrkPedDscrtInpStatMac 0 "Brake Not Applied" 1 "Brake Applied" ;
VAL_ 202 PT_BrkPedDscrtInpStatVMac 0 "Valid" 1 "Invalid" ;
VAL_ 202 PTCrnkAbrtedMac 1 "True" 0 "False" ;
VAL_ 202 PTRunAbrtMac 1 "True" 0 "False" ;
VAL_ 202 RmVhStrtEngRngMac 1 "True" 0 "False" ;
VAL_ 202 SpdLmtrSpdWrngEnbldMac 1 "True" 0 "False" ;
SIG_GROUP_ 881 AudSrcStat 1 : ASSAudSrcType ASSAudSrcChType ASSAudSrcStatCode;
SIG_GROUP_ 883 AudSrcStat2 1 : ASS2AudSrcType ASS2AudSrcChType ASS2AudSrcStatCode;
SIG_GROUP_ 948 RLHCSModeIndCtrl 1 : RLHCSMIndReq RLHCSMInd1 RLHCSMInd2 RLHCSMInd3;
SIG_GROUP_ 948 RRHCSModeIndCtrl 1 : RRHCSMIndReq RRHCSMInd1 RRHCSMInd2 RRHCSMInd3;
SIG_GROUP_ 948 RLHCSeatLevIndCtrl 1 : RLHCSLIndReq RLHCSLSeatLev1 RLHCSLSeatLev2 RLHCSLSeatLev3 RLHCSLSeatLev4 RLHCSLSeatLev5;
SIG_GROUP_ 948 RRHCSeatLevIndCtrl 1 : RRHCSLIndReq RRHCSLSeatLev1 RRHCSLSeatLev2 RRHCSLSeatLev3 RRHCSLSeatLev4 RRHCSLSeatLev5;
SIG_GROUP_ 1136 TmofDay 1 : TOD_HrofDay TOD_MinofHr TOD_SecofMin;
SIG_GROUP_ 1151 TmofDayMac 1 : TOD_HrofDayMac TOD_MinofHrMac TOD_SecofMinMac;
SIG_GROUP_ 921 DTCInfo_399 1 : DTCIUnused6_399 DTCIUnused5_399 DTCIUnused4_399 DTCIUnused3_399 DTCIUnused2_399 DTCIUnused1_399 DTCI_WrnIndTrggrd_399 DTCI_DTCTriggered_399 DTCI_DTCSource_399 DTCI_DTCNumber_399 DTCI_DTCFailType_399 DTCI_WIR_399 DTCI_TNCTOC_399 DTCI_TFSLC_399 DTCI_TNCSLC_399 DTCI_CDTC_399 DTCI_PDTC_399 DTCI_TFTOC_399 DTCI_TF_399 DTCI_DTCFaultType_399;
SIG_GROUP_ 317 LBCCstmrDaRstResp 1 : LBCCDRR_ClrStrdPosResp LBCCDRR_PosNumbr;
SIG_GROUP_ 317 LBCPosStgStat 1 : LBCPSS_PosUpdtStat LBCPSS_PosUpdtLct;
SIG_GROUP_ 317 LBCCstmrFdbk 1 : LBCCF_Lct1PosStrdIO LBCCF_Lct2PosStrdIO LBCCF_Lct3PosStrdIO LBCCF_Lct4PosStrdIO;
SIG_GROUP_ 317 LBCVehLctStat 1 : LBCVLS_VehGPSLctV LBCVLS_VehGPSLct;
SIG_GROUP_ 794 EngyUsgScr 1 : EUS_TcEngyUsgScrAvVal EUS_TrEngyUsgScrAvVal EUS_OTEngyUsgScrAvVal EUS_ITEngyUsgScrAvVal EUS_TtEngyUsgScrAvVal;
